VERSION ""

NS_ :

BS_:

BU_: VMM IMR BCS GSM EMS EPB SRS TEL ICM ACU VCU WCM TSCM Tester Test SCMRR SCMRL SCM SBM RCP PSDR PSDL PLGM PAS LCU IHU IBCM IAL HVSPRR HVSPRL HVSMR HVSM HVACF HUD GWM FRDCM FLDCM FCP FAPA ETC Diagnostic Messages AVAS AMP

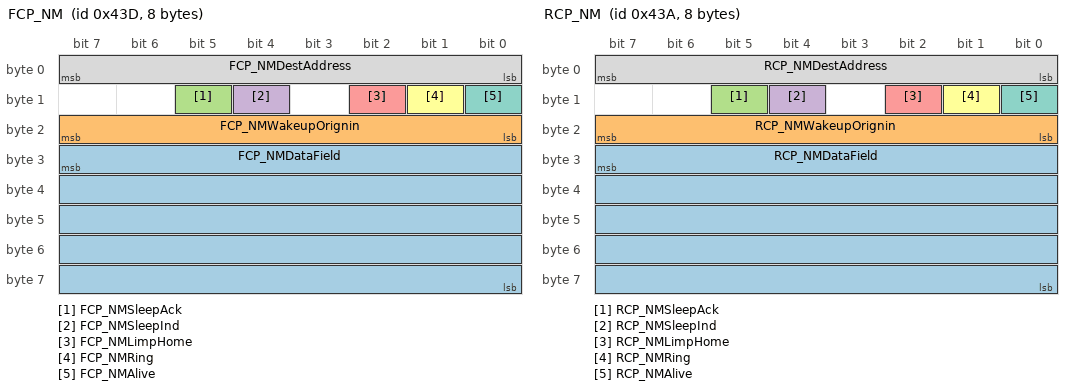
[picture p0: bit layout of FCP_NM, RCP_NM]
BO_ 1085 FCP_NM: 8 FCP
 SG_ FCP_NMDataField : 31|40@0+ (1,0) [0|0] ""  PSDR,PSDL,AMP,LCU,HUD,PLGM,FLDCM,FRDCM,SCM,TSCM,IBCM,HVACF,IAL,RCP,HVSM,IHU,SBM,WCM,ETC,GWM
 SG_ FCP_NMWakeupOrignin : 23|8@0+ (1,0) [0|255] ""  PSDR,PSDL,AMP,LCU,HUD,PLGM,FLDCM,FRDCM,SCM,TSCM,IBCM,HVACF,IAL,RCP,HVSM,IHU,SBM,WCM,ETC,GWM
 SG_ FCP_NMSleepAck : 13|1@0+ (1,0) [0|1] ""  PSDR,PSDL,AMP,LCU,HUD,PLGM,FLDCM,FRDCM,SCM,TSCM,IBCM,HVACF,IAL,RCP,HVSM,IHU,SBM,WCM,ETC,GWM
 SG_ FCP_NMSleepInd : 12|1@0+ (1,0) [0|1] ""  PSDR,PSDL,AMP,LCU,HUD,PLGM,FLDCM,FRDCM,SCM,TSCM,IBCM,HVACF,IAL,RCP,HVSM,IHU,SBM,WCM,ETC,GWM
 SG_ FCP_NMLimpHome : 10|1@0+ (1,0) [0|1] ""  PSDR,PSDL,AMP,LCU,HUD,PLGM,FLDCM,FRDCM,SCM,TSCM,IBCM,HVACF,IAL,RCP,HVSM,IHU,SBM,WCM,ETC,GWM
 SG_ FCP_NMRing : 9|1@0+ (1,0) [0|1] ""  PSDR,PSDL,AMP,LCU,HUD,PLGM,FLDCM,FRDCM,SCM,TSCM,IBCM,HVACF,IAL,RCP,HVSM,IHU,SBM,WCM,ETC,GWM
 SG_ FCP_NMAlive : 8|1@0+ (1,0) [0|1] ""  PSDR,PSDL,AMP,LCU,HUD,PLGM,FLDCM,FRDCM,SCM,TSCM,IBCM,HVACF,IAL,RCP,HVSM,IHU,SBM,WCM,ETC,GWM
 SG_ FCP_NMDestAddress : 7|8@0+ (1,0) [0|255] ""  PSDR,PSDL,AMP,LCU,HUD,PLGM,FLDCM,FRDCM,SCM,TSCM,IBCM,HVACF,IAL,RCP,HVSM,IHU,SBM,WCM,ETC,GWM

BO_ 1082 RCP_NM: 8 RCP
 SG_ RCP_NMDataField : 31|40@0+ (1,0) [0|0] ""  PSDR,PSDL,AMP,LCU,HUD,PLGM,FLDCM,FRDCM,SCM,TSCM,IBCM,HVACF,IAL,HVSM,IHU,SBM,WCM,ETC,GWM
 SG_ RCP_NMWakeupOrignin : 23|8@0+ (1,0) [0|255] ""  PSDR,PSDL,AMP,LCU,HUD,PLGM,FLDCM,FRDCM,SCM,TSCM,IBCM,HVACF,IAL,HVSM,IHU,SBM,WCM,ETC,GWM
 SG_ RCP_NMSleepAck : 13|1@0+ (1,0) [0|1] ""  PSDR,PSDL,AMP,LCU,HUD,PLGM,FLDCM,FRDCM,SCM,TSCM,IBCM,HVACF,IAL,HVSM,IHU,SBM,WCM,ETC,GWM
 SG_ RCP_NMSleepInd : 12|1@0+ (1,0) [0|1] ""  PSDR,PSDL,AMP,LCU,HUD,PLGM,FLDCM,FRDCM,SCM,TSCM,IBCM,HVACF,IAL,HVSM,IHU,SBM,WCM,ETC,GWM
 SG_ RCP_NMLimpHome : 10|1@0+ (1,0) [0|1] ""  PSDR,PSDL,AMP,LCU,HUD,PLGM,FLDCM,FRDCM,SCM,TSCM,IBCM,HVACF,IAL,HVSM,IHU,SBM,WCM,ETC,GWM
 SG_ RCP_NMRing : 9|1@0+ (1,0) [0|1] ""  PSDR,PSDL,AMP,LCU,HUD,PLGM,FLDCM,FRDCM,SCM,TSCM,IBCM,HVACF,IAL,HVSM,IHU,SBM,WCM,ETC,GWM
 SG_ RCP_NMAlive : 8|1@0+ (1,0) [0|1] ""  PSDR,PSDL,AMP,LCU,HUD,PLGM,FLDCM,FRDCM,SCM,TSCM,IBCM,HVACF,IAL,HVSM,IHU,SBM,WCM,ETC,GWM
 SG_ RCP_NMDestAddress : 7|8@0+ (1,0) [0|255] ""  PSDR,PSDL,AMP,LCU,HUD,PLGM,FLDCM,FRDCM,SCM,TSCM,IBCM,HVACF,IAL,HVSM,IHU,SBM,WCM,ETC,GWM

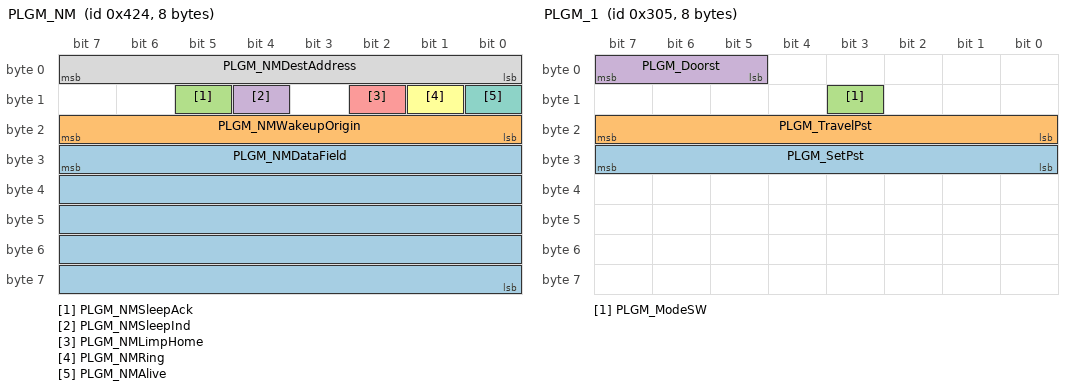
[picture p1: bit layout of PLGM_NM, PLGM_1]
BO_ 1060 PLGM_NM: 8 PLGM
 SG_ PLGM_NMDataField : 31|40@0+ (1,0) [0|0] ""  PSDR,PSDL,AMP,LCU,HUD,FLDCM,FRDCM,SCM,TSCM,IBCM,HVACF,IAL,RCP,FCP,HVSM,IHU,SBM,WCM,ETC,GWM
 SG_ PLGM_NMWakeupOrigin : 23|8@0+ (1,0) [0|255] ""  PSDR,PSDL,AMP,LCU,HUD,FLDCM,FRDCM,SCM,TSCM,IBCM,HVACF,IAL,RCP,FCP,HVSM,IHU,SBM,WCM,ETC,GWM
 SG_ PLGM_NMSleepAck : 13|1@0+ (1,0) [0|1] ""  PSDR,PSDL,AMP,LCU,HUD,FLDCM,FRDCM,SCM,TSCM,IBCM,HVACF,IAL,RCP,FCP,HVSM,IHU,SBM,WCM,ETC,GWM
 SG_ PLGM_NMSleepInd : 12|1@0+ (1,0) [0|1] ""  PSDR,PSDL,AMP,LCU,HUD,FLDCM,FRDCM,SCM,TSCM,IBCM,HVACF,IAL,RCP,FCP,HVSM,IHU,SBM,WCM,ETC,GWM
 SG_ PLGM_NMLimpHome : 10|1@0+ (1,0) [0|1] ""  PSDR,PSDL,AMP,LCU,HUD,FLDCM,FRDCM,SCM,TSCM,IBCM,HVACF,IAL,RCP,FCP,HVSM,IHU,SBM,WCM,ETC,GWM
 SG_ PLGM_NMRing : 9|1@0+ (1,0) [0|1] ""  PSDR,PSDL,AMP,LCU,HUD,FLDCM,FRDCM,SCM,TSCM,IBCM,HVACF,IAL,RCP,FCP,HVSM,IHU,SBM,WCM,ETC,GWM
 SG_ PLGM_NMAlive : 8|1@0+ (1,0) [0|1] ""  PSDR,PSDL,AMP,LCU,HUD,FLDCM,FRDCM,SCM,TSCM,IBCM,HVACF,IAL,RCP,FCP,HVSM,IHU,SBM,WCM,ETC,GWM
 SG_ PLGM_NMDestAddress : 7|8@0+ (1,0) [0|255] ""  PSDR,PSDL,AMP,LCU,HUD,FLDCM,FRDCM,SCM,TSCM,IBCM,HVACF,IAL,RCP,FCP,HVSM,IHU,SBM,WCM,ETC,GWM

BO_ 773 PLGM_1: 8 PLGM
 SG_ PLGM_SetPst : 31|8@0+ (1,0) [0|100] "%"  IHU,GWM
 SG_ PLGM_TravelPst : 23|8@0+ (1,0) [0|100] "%"  IHU,GWM
 SG_ PLGM_ModeSW : 11|1@0+ (1,0) [0|1] ""  IHU,GWM
 SG_ PLGM_Doorst : 7|3@0+ (1,0) [0|7] ""  IHU,SBM,GWM

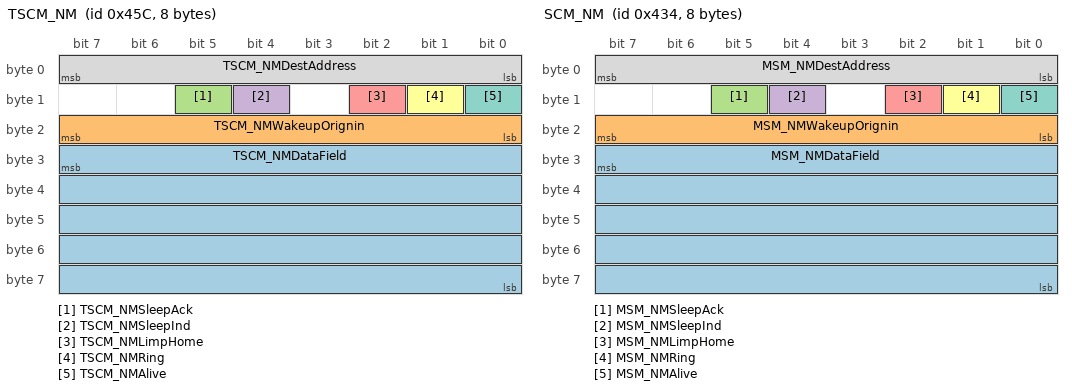
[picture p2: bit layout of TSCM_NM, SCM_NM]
BO_ 1116 TSCM_NM: 8 TSCM
 SG_ TSCM_NMDataField : 31|40@0+ (1,0) [0|0] ""  PSDR,PSDL,AMP,LCU,HUD,PLGM,FLDCM,FRDCM,SCM,IBCM,HVACF,IAL,RCP,FCP,HVSM,IHU,SBM,WCM,ETC
 SG_ TSCM_NMWakeupOrignin : 23|8@0+ (1,0) [0|255] ""  PSDR,PSDL,AMP,LCU,HUD,PLGM,FLDCM,FRDCM,SCM,IBCM,HVACF,IAL,RCP,FCP,HVSM,IHU,SBM,WCM,ETC
 SG_ TSCM_NMSleepAck : 13|1@0+ (1,0) [0|1] ""  PSDR,PSDL,AMP,LCU,HUD,PLGM,FLDCM,FRDCM,SCM,IBCM,HVACF,IAL,RCP,FCP,HVSM,IHU,SBM,WCM,ETC
 SG_ TSCM_NMSleepInd : 12|1@0+ (1,0) [0|1] ""  PSDR,PSDL,AMP,LCU,HUD,PLGM,FLDCM,FRDCM,SCM,IBCM,HVACF,IAL,RCP,FCP,HVSM,IHU,SBM,WCM,ETC
 SG_ TSCM_NMLimpHome : 10|1@0+ (1,0) [0|1] ""  PSDR,PSDL,AMP,LCU,HUD,PLGM,FLDCM,FRDCM,SCM,IBCM,HVACF,IAL,RCP,FCP,HVSM,IHU,SBM,WCM,ETC
 SG_ TSCM_NMRing : 9|1@0+ (1,0) [0|1] ""  PSDR,PSDL,AMP,LCU,HUD,PLGM,FLDCM,FRDCM,SCM,IBCM,HVACF,IAL,RCP,FCP,HVSM,IHU,SBM,WCM,ETC
 SG_ TSCM_NMAlive : 8|1@0+ (1,0) [0|1] ""  PSDR,PSDL,AMP,LCU,HUD,PLGM,FLDCM,FRDCM,SCM,IBCM,HVACF,IAL,RCP,FCP,HVSM,IHU,SBM,WCM,ETC
 SG_ TSCM_NMDestAddress : 7|8@0+ (1,0) [0|255] ""  PSDR,PSDL,AMP,LCU,HUD,PLGM,FLDCM,FRDCM,SCM,IBCM,HVACF,IAL,RCP,FCP,HVSM,IHU,SBM,WCM,ETC

BO_ 1076 SCM_NM: 8 SCM
 SG_ MSM_NMDataField : 31|40@0+ (1,0) [0|0] ""  PSDR,PSDL,AMP,LCU,HUD,PLGM,FLDCM,FRDCM,TSCM,IBCM,HVACF,IAL,RCP,FCP,HVSM,IHU,SBM,WCM,ETC,GWM
 SG_ MSM_NMWakeupOrignin : 23|8@0+ (1,0) [0|255] ""  PSDR,PSDL,AMP,LCU,HUD,PLGM,FLDCM,FRDCM,TSCM,IBCM,HVACF,IAL,RCP,FCP,HVSM,IHU,SBM,WCM,ETC,GWM
 SG_ MSM_NMSleepAck : 13|1@0+ (1,0) [0|1] ""  PSDR,PSDL,AMP,LCU,HUD,PLGM,FLDCM,FRDCM,TSCM,IBCM,HVACF,IAL,RCP,FCP,HVSM,IHU,SBM,WCM,ETC,GWM
 SG_ MSM_NMSleepInd : 12|1@0+ (1,0) [0|1] ""  PSDR,PSDL,AMP,LCU,HUD,PLGM,FLDCM,FRDCM,TSCM,IBCM,HVACF,IAL,RCP,FCP,HVSM,IHU,SBM,WCM,ETC,GWM
 SG_ MSM_NMLimpHome : 10|1@0+ (1,0) [0|1] ""  PSDR,PSDL,AMP,LCU,HUD,PLGM,FLDCM,FRDCM,TSCM,IBCM,HVACF,IAL,RCP,FCP,HVSM,IHU,SBM,WCM,ETC,GWM
 SG_ MSM_NMRing : 9|1@0+ (1,0) [0|1] ""  PSDR,PSDL,AMP,LCU,HUD,PLGM,FLDCM,FRDCM,TSCM,IBCM,HVACF,IAL,RCP,FCP,HVSM,IHU,SBM,WCM,ETC,GWM
 SG_ MSM_NMAlive : 8|1@0+ (1,0) [0|1] ""  PSDR,PSDL,AMP,LCU,HUD,PLGM,FLDCM,FRDCM,TSCM,IBCM,HVACF,IAL,RCP,FCP,HVSM,IHU,SBM,WCM,ETC,GWM
 SG_ MSM_NMDestAddress : 7|8@0+ (1,0) [0|255] ""  PSDR,PSDL,AMP,LCU,HUD,PLGM,FLDCM,FRDCM,TSCM,IBCM,HVACF,IAL,RCP,FCP,HVSM,IHU,SBM,WCM,ETC,GWM

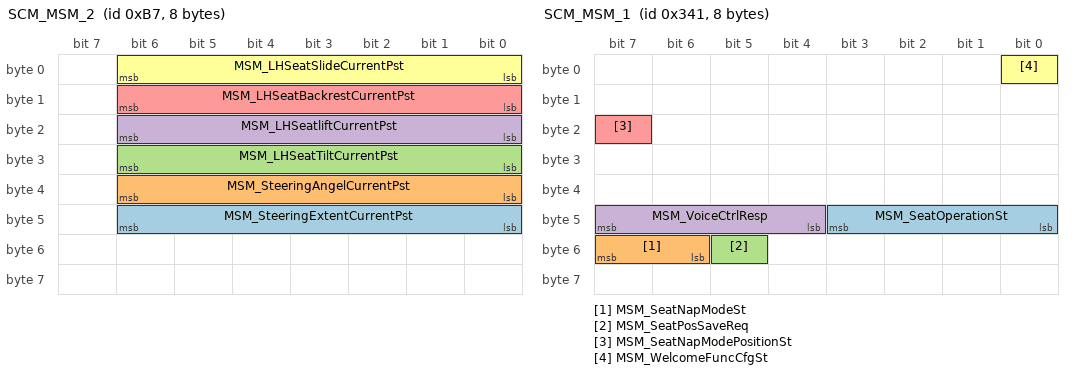
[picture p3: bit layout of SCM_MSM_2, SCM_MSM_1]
BO_ 183 SCM_MSM_2: 8 SCM
 SG_ MSM_SteeringExtentCurrentPst : 46|7@0+ (1,1) [0|0] "%"  IHU
 SG_ MSM_SteeringAngelCurrentPst : 38|7@0+ (1,1) [0|0] "%"  IHU
 SG_ MSM_LHSeatTiltCurrentPst : 30|7@0+ (1,1) [0|0] "%"  IHU
 SG_ MSM_LHSeatliftCurrentPst : 22|7@0+ (1,1) [0|0] "%"  IHU
 SG_ MSM_LHSeatBackrestCurrentPst : 14|7@0+ (1,1) [0|0] "%"  IHU
 SG_ MSM_LHSeatSlideCurrentPst : 6|7@0+ (1,1) [0|0] "%"  IHU

BO_ 833 SCM_MSM_1: 8 SCM
 SG_ MSM_SeatOperationSt : 43|4@0+ (1,0) [0|15] ""  FLDCM,FRDCM,IHU
 SG_ MSM_SeatNapModeSt : 55|2@0+ (1,0) [0|3] ""  FLDCM,IHU
 SG_ MSM_SeatPosSaveReq : 53|1@0+ (1,0) [0|1] ""  FLDCM,IHU
 SG_ MSM_VoiceCtrlResp : 47|4@0+ (1,0) [0|15] ""  IHU
 SG_ MSM_SeatNapModePositionSt : 23|1@0+ (1,0) [0|1] ""  IHU
 SG_ MSM_WelcomeFuncCfgSt : 0|1@0+ (1,0) [0|1] ""  IHU

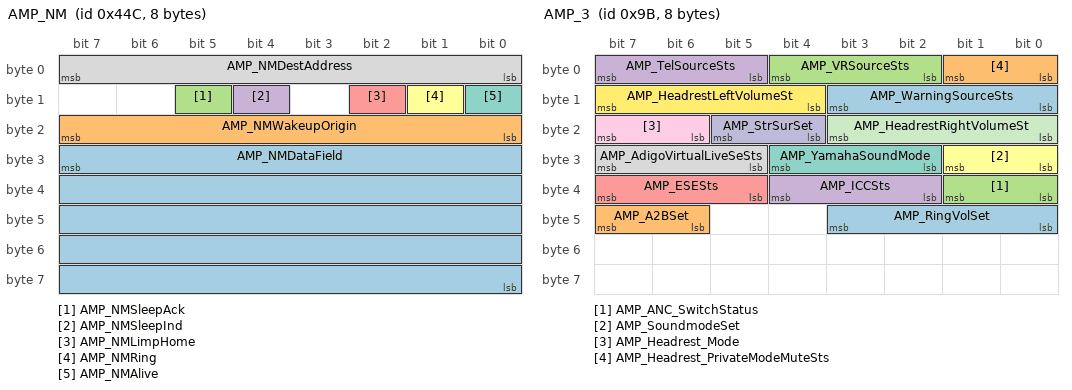
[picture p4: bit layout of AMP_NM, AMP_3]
BO_ 1100 AMP_NM: 8 AMP
 SG_ AMP_NMDataField : 31|40@0+ (1,0) [0|0] "-"  PSDR,PSDL,AMP,LCU,HUD,PLGM,FLDCM,FRDCM,SCM,TSCM,IBCM,HVACF,IAL,RCP,FCP,HVSM,IHU,SBM,WCM,ETC,GWM
 SG_ AMP_NMWakeupOrigin : 23|8@0+ (1,0) [0|255] "-"  PSDR,PSDL,AMP,LCU,HUD,PLGM,FLDCM,FRDCM,SCM,TSCM,IBCM,HVACF,IAL,RCP,FCP,HVSM,IHU,SBM,WCM,ETC,GWM
 SG_ AMP_NMSleepAck : 13|1@0+ (1,0) [0|1] "-"  PSDR,PSDL,AMP,LCU,HUD,PLGM,FLDCM,FRDCM,SCM,TSCM,IBCM,HVACF,IAL,RCP,FCP,HVSM,IHU,SBM,WCM,ETC,GWM
 SG_ AMP_NMSleepInd : 12|1@0+ (1,0) [0|1] "-"  PSDR,PSDL,AMP,LCU,HUD,PLGM,FLDCM,FRDCM,SCM,TSCM,IBCM,HVACF,IAL,RCP,FCP,HVSM,IHU,SBM,WCM,ETC,GWM
 SG_ AMP_NMLimpHome : 10|1@0+ (1,0) [0|1] "-"  PSDR,PSDL,AMP,LCU,HUD,PLGM,FLDCM,FRDCM,SCM,TSCM,IBCM,HVACF,IAL,RCP,FCP,HVSM,IHU,SBM,WCM,ETC,GWM
 SG_ AMP_NMRing : 9|1@0+ (1,0) [0|1] "-"  PSDR,PSDL,AMP,LCU,HUD,PLGM,FLDCM,FRDCM,SCM,TSCM,IBCM,HVACF,IAL,RCP,FCP,HVSM,IHU,SBM,WCM,ETC,GWM
 SG_ AMP_NMAlive : 8|1@0+ (1,0) [0|1] "-"  PSDR,PSDL,AMP,LCU,HUD,PLGM,FLDCM,FRDCM,SCM,TSCM,IBCM,HVACF,IAL,RCP,FCP,HVSM,IHU,SBM,WCM,ETC,GWM
 SG_ AMP_NMDestAddress : 7|8@0+ (1,0) [0|255] "-"  PSDR,PSDL,AMP,LCU,HUD,PLGM,FLDCM,FRDCM,SCM,TSCM,IBCM,HVACF,IAL,RCP,FCP,HVSM,IHU,SBM,WCM,ETC,GWM

BO_ 155 AMP_3: 8 AMP
 SG_ AMP_RingVolSet : 43|4@0+ (1,0) [0|15] ""  IHU
 SG_ AMP_A2BSet : 47|2@0+ (1,0) [0|3] ""  IHU
 SG_ AMP_ANC_SwitchStatus : 33|2@0+ (1,0) [0|3] ""  IHU
 SG_ AMP_ICCSts : 36|3@0+ (1,0) [0|7] ""  IHU
 SG_ AMP_ESESts : 39|3@0+ (1,0) [0|7] ""  IHU
 SG_ AMP_SoundmodeSet : 25|2@0+ (1,0) [0|3] ""  IHU
 SG_ AMP_YamahaSoundMode : 28|3@0+ (1,0) [0|7] ""  IHU
 SG_ AMP_AdigoVirtualLiveSeSts : 31|3@0+ (1,0) [0|7] ""  IHU
 SG_ AMP_Headrest_Mode : 23|2@0+ (1,0) [0|3] ""  HVSPRR,HVSPRL,IHU
 SG_ AMP_StrSurSet : 21|2@0+ (1,0) [0|1] ""  IHU
 SG_ AMP_HeadrestRightVolumeSt : 19|4@0+ (1,0) [0|15] ""  HVSPRR,IHU
 SG_ AMP_HeadrestLeftVolumeSt : 15|4@0+ (1,0) [0|15] ""  HVSPRL,IHU
 SG_ AMP_WarningSourceSts : 11|4@0+ (1,0) [0|15] ""  IHU
 SG_ AMP_Headrest_PrivateModeMuteSts : 1|2@0+ (1,0) [0|3] ""  HVSPRR,HVSPRL,IHU
 SG_ AMP_VRSourceSts : 4|3@0+ (1,0) [0|7] ""  IHU
 SG_ AMP_TelSourceSts : 7|3@0+ (1,0) [0|7] ""  IHU

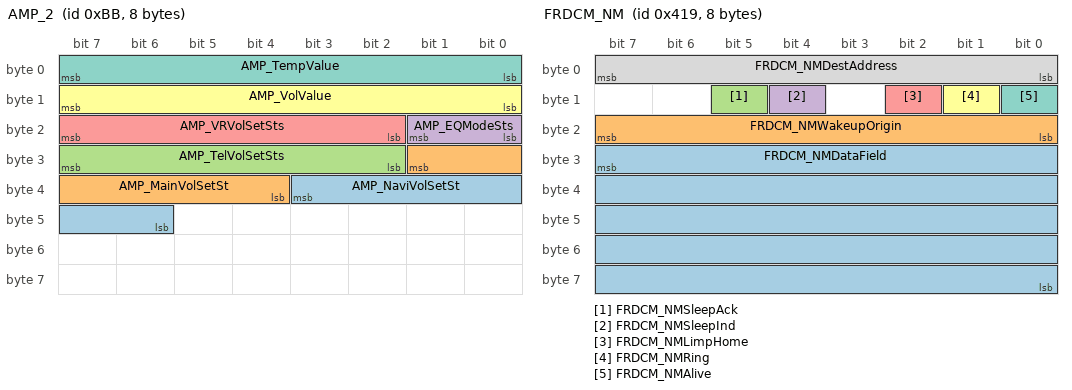
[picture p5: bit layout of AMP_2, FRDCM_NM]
BO_ 187 AMP_2: 8 AMP
 SG_ AMP_NaviVolSetSt : 35|6@0+ (1,0) [0|63] ""  IHU
 SG_ AMP_MainVolSetSt : 25|6@0+ (1,0) [0|63] ""  IHU
 SG_ AMP_TelVolSetSts : 31|6@0+ (1,0) [0|63] ""  IHU
 SG_ AMP_EQModeSts : 17|2@0+ (1,0) [0|3] ""  IHU
 SG_ AMP_VRVolSetSts : 23|6@0+ (1,0) [0|63] ""  IHU
 SG_ AMP_VolValue : 15|8@0+ (1,0) [0|255] ""  IHU
 SG_ AMP_TempValue : 7|8@0+ (1,0) [0|255] ""  IHU

BO_ 188 AMP_1: 8 AMP
 SG_ AMP_SpeakMid : 57|2@0+ (1,0) [0|3] ""  IHU
 SG_ AMP_SpeakrRR : 59|2@0+ (1,0) [0|3] ""  IHU
 SG_ AMP_SpeakrRL : 61|2@0+ (1,0) [0|3] ""  IHU
 SG_ AMP_SpeakrFR : 63|2@0+ (1,0) [0|3] ""  IHU
 SG_ AMP_SpeakFL : 49|2@0+ (1,0) [0|3] ""  IHU
 SG_ AMP_MediaSourceSt : 53|4@0+ (1,0) [0|15] ""  IHU
 SG_ AMP_ClariFiSt : 55|2@0+ (1,0) [0|3] ""  IHU
 SG_ AMP_PowerSts : 41|2@0+ (1,0) [0|3] ""  IHU
 SG_ AMP_HighFrqSet : 46|5@0+ (1,0) [0|31] ""  IHU
 SG_ AMP_TreSurSetSt : 32|2@0+ (1,0) [0|3] ""  IHU
 SG_ AMP_GetHUTInfoSts : 34|2@0+ (1,0) [0|3] ""  IHU
 SG_ AMP_TEL_ECallSts : 36|2@0+ (1,0) [0|3] ""  IHU
 SG_ AMP_MuteRearSet : 38|2@0+ (1,0) [0|3] ""  IHU
 SG_ AMP_MuteSt : 24|2@0+ (1,0) [0|3] ""  IHU
 SG_ AMP_DriveSideSt : 26|2@0+ (1,0) [0|3] ""  IHU
 SG_ AMP_MidFrqSet : 31|5@0+ (1,0) [0|31] ""  IHU
 SG_ AMP_LowFrqSet : 20|5@0+ (1,0) [0|31] ""  IHU
 SG_ AMP_VSCModeSt : 23|3@0+ (1,0) [0|7] ""  IHU
 SG_ AMP_NaviSourceSt : 10|3@0+ (1,0) [0|7] ""  IHU
 SG_ AMP_FadeSetSt : 15|5@0+ (1,0) [0|31] ""  IHU
 SG_ AMP_BeepSourceSts : 2|3@0+ (1,0) [0|7] ""  IHU
 SG_ AMP_BlcSetSt : 7|5@0+ (1,0) [0|31] ""  IHU

BO_ 1049 FRDCM_NM: 8 FRDCM
 SG_ FRDCM_NMDataField : 31|40@0+ (1,0) [0|0] ""  PSDR,PSDL,AMP,LCU,HUD,PLGM,FLDCM,SCM,TSCM,IBCM,HVACF,IAL,RCP,FCP,HVSM,IHU,SBM,WCM,ETC,GWM
 SG_ FRDCM_NMWakeupOrigin : 23|8@0+ (1,0) [0|255] ""  PSDR,PSDL,AMP,LCU,HUD,PLGM,FLDCM,SCM,TSCM,IBCM,HVACF,IAL,RCP,FCP,HVSM,IHU,SBM,WCM,ETC,GWM
 SG_ FRDCM_NMSleepAck : 13|1@0+ (1,0) [0|1] ""  PSDR,PSDL,AMP,LCU,HUD,PLGM,FLDCM,SCM,TSCM,IBCM,HVACF,IAL,RCP,FCP,HVSM,IHU,SBM,WCM,ETC,GWM
 SG_ FRDCM_NMSleepInd : 12|1@0+ (1,0) [0|1] ""  PSDR,PSDL,AMP,LCU,HUD,PLGM,FLDCM,SCM,TSCM,IBCM,HVACF,IAL,RCP,FCP,HVSM,IHU,SBM,WCM,ETC,GWM
 SG_ FRDCM_NMLimpHome : 10|1@0+ (1,0) [0|1] ""  PSDR,PSDL,AMP,LCU,HUD,PLGM,FLDCM,SCM,TSCM,IBCM,HVACF,IAL,RCP,FCP,HVSM,IHU,SBM,WCM,ETC,GWM
 SG_ FRDCM_NMRing : 9|1@0+ (1,0) [0|1] ""  PSDR,PSDL,AMP,LCU,HUD,PLGM,FLDCM,SCM,TSCM,IBCM,HVACF,IAL,RCP,FCP,HVSM,IHU,SBM,WCM,ETC,GWM
 SG_ FRDCM_NMAlive : 8|1@0+ (1,0) [0|1] ""  PSDR,PSDL,AMP,LCU,HUD,PLGM,FLDCM,SCM,TSCM,IBCM,HVACF,IAL,RCP,FCP,HVSM,IHU,SBM,WCM,ETC,GWM
 SG_ FRDCM_NMDestAddress : 7|8@0+ (1,0) [0|255] ""  PSDR,PSDL,AMP,LCU,HUD,PLGM,FLDCM,SCM,TSCM,IBCM,HVACF,IAL,RCP,FCP,HVSM,IHU,SBM,WCM,ETC,GWM

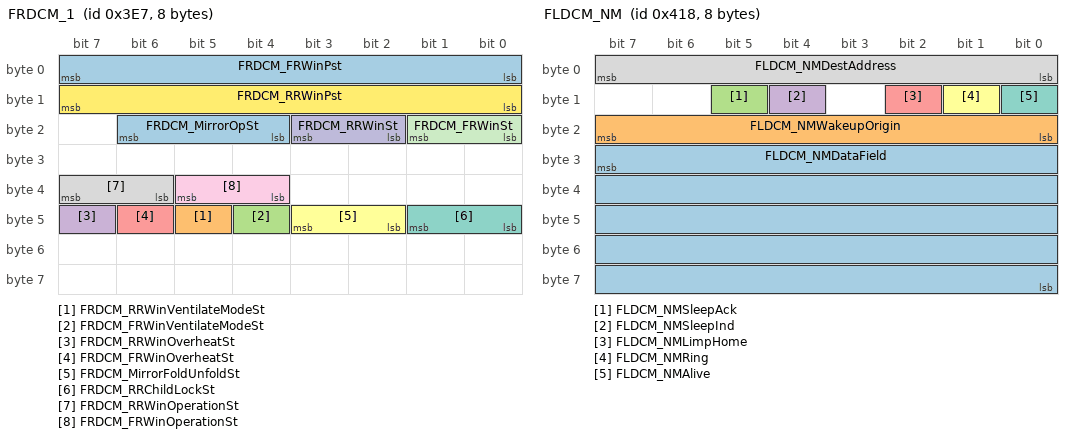
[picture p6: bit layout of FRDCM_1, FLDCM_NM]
BO_ 999 FRDCM_1: 8 FRDCM
 SG_ FRDCM_MirrorOpSt : 22|3@0+ (1,0) [0|7] ""  TEL,FLDCM,IHU,GWM
 SG_ FRDCM_RRWinVentilateModeSt : 45|1@0+ (1,0) [0|1] ""  FLDCM,IHU,GWM
 SG_ FRDCM_FRWinVentilateModeSt : 44|1@0+ (1,0) [0|1] ""  FLDCM,IHU,GWM
 SG_ FRDCM_RRWinOverheatSt : 47|1@0+ (1,0) [0|3] ""  IHU,SBM,GWM
 SG_ FRDCM_FRWinOverheatSt : 46|1@0+ (1,0) [0|3] ""  IHU,SBM,GWM
 SG_ FRDCM_MirrorFoldUnfoldSt : 43|2@0+ (1,0) [0|3] ""  IHU,FAPA,GWM
 SG_ FRDCM_RRChildLockSt : 41|2@0+ (1,0) [0|3] ""  IBCM,IHU,GWM
 SG_ FRDCM_RRWinOperationSt : 39|2@0+ (1,0) [0|3] ""  IBCM,IHU,SBM,GWM
 SG_ FRDCM_FRWinOperationSt : 37|2@0+ (1,0) [0|3] ""  IBCM,IHU,SBM,GWM
 SG_ FRDCM_RRWinSt : 19|2@0+ (1,0) [0|3] ""  FLDCM,IBCM,IAL,IHU,SBM,FAPA,GWM
 SG_ FRDCM_FRWinSt : 17|2@0+ (1,0) [0|3] ""  FLDCM,IBCM,IAL,IHU,SBM,FAPA,GWM
 SG_ FRDCM_RRWinPst : 15|8@0+ (0.5,0) [0|100] "%"  AMP,IBCM,IHU,GWM
 SG_ FRDCM_FRWinPst : 7|8@0+ (0.5,0) [0|100] "%"  AMP,IBCM,IHU,GWM

BO_ 1048 FLDCM_NM: 8 FLDCM
 SG_ FLDCM_NMDataField : 31|40@0+ (1,0) [0|0] ""  PSDR,PSDL,AMP,LCU,HUD,PLGM,FRDCM,SCM,TSCM,IBCM,HVACF,IAL,RCP,FCP,HVSM,IHU,SBM,WCM,ETC,GWM
 SG_ FLDCM_NMWakeupOrigin : 23|8@0+ (1,0) [0|255] ""  PSDR,PSDL,AMP,LCU,HUD,PLGM,FRDCM,SCM,TSCM,IBCM,HVACF,IAL,RCP,FCP,HVSM,IHU,SBM,WCM,ETC,GWM
 SG_ FLDCM_NMSleepAck : 13|1@0+ (1,0) [0|1] ""  PSDR,PSDL,AMP,LCU,HUD,PLGM,FRDCM,SCM,TSCM,IBCM,HVACF,IAL,RCP,FCP,HVSM,IHU,SBM,WCM,ETC,GWM
 SG_ FLDCM_NMSleepInd : 12|1@0+ (1,0) [0|1] ""  PSDR,PSDL,AMP,LCU,HUD,PLGM,FRDCM,SCM,TSCM,IBCM,HVACF,IAL,RCP,FCP,HVSM,IHU,SBM,WCM,ETC,GWM
 SG_ FLDCM_NMLimpHome : 10|1@0+ (1,0) [0|1] ""  PSDR,PSDL,AMP,LCU,HUD,PLGM,FRDCM,SCM,TSCM,IBCM,HVACF,IAL,RCP,FCP,HVSM,IHU,SBM,WCM,ETC,GWM
 SG_ FLDCM_NMRing : 9|1@0+ (1,0) [0|1] ""  PSDR,PSDL,AMP,LCU,HUD,PLGM,FRDCM,SCM,TSCM,IBCM,HVACF,IAL,RCP,FCP,HVSM,IHU,SBM,WCM,ETC,GWM
 SG_ FLDCM_NMAlive : 8|1@0+ (1,0) [0|1] ""  PSDR,PSDL,AMP,LCU,HUD,PLGM,FRDCM,SCM,TSCM,IBCM,HVACF,IAL,RCP,FCP,HVSM,IHU,SBM,WCM,ETC,GWM
 SG_ FLDCM_NMDestAddress : 7|8@0+ (1,0) [0|255] ""  PSDR,PSDL,AMP,LCU,HUD,PLGM,FRDCM,SCM,TSCM,IBCM,HVACF,IAL,RCP,FCP,HVSM,IHU,SBM,WCM,ETC,GWM

BO_ 997 FLDCM_1: 8 FLDCM
 SG_ FLDCM_MirrorOpSt : 34|3@0+ (1,0) [0|7] ""  TEL,FRDCM,IHU,GWM
 SG_ FLDCM_RLWinVentilateModeSt : 63|1@0+ (1,0) [0|1] ""  FRDCM,IHU,GWM
 SG_ FLDCM_FLWinVentilateModeSt : 62|1@0+ (1,0) [0|1] ""  FRDCM,IHU,GWM
 SG_ FLDCM_MirrorFoldUnfoldSt : 61|2@0+ (1,0) [0|3] ""  IHU,FAPA,GWM
 SG_ FLDCM_RLWinOperationSt : 59|2@0+ (1,0) [0|3] ""  IBCM,IHU,SBM,GWM
 SG_ FLDCM_FLWinOperationSt : 57|2@0+ (1,0) [0|3] ""  IBCM,IHU,SBM,GWM
 SG_ FLDCM_OSRMAngleAdjFuncCfgSt : 55|2@0+ (1,0) [0|3] ""  FRDCM,IHU,GWM
 SG_ FLDCM_MemorySysBuzzerReq : 53|2@0+ (1,0) [0|3] ""  IHU,GWM
 SG_ FLDCM_RLWinOverheatSt : 49|1@0+ (1,0) [0|1] ""  IHU,SBM,GWM
 SG_ FLDCM_FLWinOverheatSt : 48|1@0+ (1,0) [0|1] ""  IHU,SBM,GWM
 SG_ FLDCM_APWLEnableSt : 44|1@0+ (1,0) [0|1] ""  FRDCM,IHU,GWM
 SG_ FLDCM_PowerWinOpenWarn : 43|1@0+ (1,0) [0|1] ""  IHU,GWM
 SG_ FLDCM_MemSysOperationReq : 42|1@0+ (1,0) [0|1] ""  IHU,GWM
 SG_ FLDCM_RLChildLockSt : 41|2@0+ (1,0) [0|3] ""  IBCM,IHU,GWM
 SG_ FLDCM_RLWinSt : 19|2@0+ (1,0) [0|3] ""  IBCM,IAL,IHU,SBM,FAPA,GWM
 SG_ FLDCM_FLWinSt : 17|2@0+ (1,0) [0|3] ""  IBCM,IAL,IHU,SBM,FAPA,GWM
 SG_ FLDCM_RLWinPst : 15|8@0+ (0.5,0) [0|100] "%"  AMP,IBCM,IHU,GWM
 SG_ FLDCM_FLWinPst : 7|8@0+ (0.5,0) [0|100] "%"  AMP,IBCM,IHU,GWM

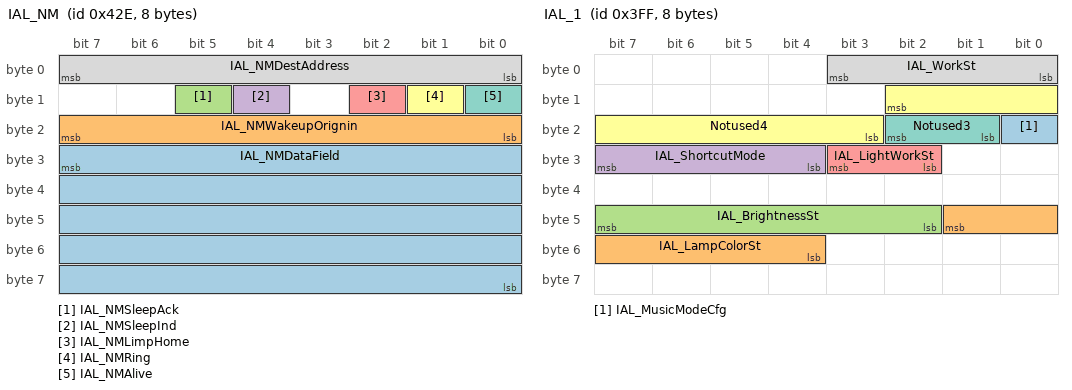
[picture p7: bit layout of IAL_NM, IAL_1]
BO_ 1070 IAL_NM: 8 IAL
 SG_ IAL_NMDataField : 31|40@0+ (1,0) [0|0] ""  PSDR,PSDL,AMP,LCU,HUD,PLGM,FLDCM,FRDCM,SCM,TSCM,IBCM,HVACF,RCP,FCP,HVSM,IHU,SBM,WCM,ETC,GWM
 SG_ IAL_NMWakeupOrignin : 23|8@0+ (1,0) [0|255] ""  PSDR,PSDL,AMP,LCU,HUD,PLGM,FLDCM,FRDCM,SCM,TSCM,IBCM,HVACF,RCP,FCP,HVSM,IHU,SBM,WCM,ETC,GWM
 SG_ IAL_NMSleepAck : 13|1@0+ (1,0) [0|1] ""  PSDR,PSDL,AMP,LCU,HUD,PLGM,FLDCM,FRDCM,SCM,TSCM,IBCM,HVACF,RCP,FCP,HVSM,IHU,SBM,WCM,ETC,GWM
 SG_ IAL_NMSleepInd : 12|1@0+ (1,0) [0|1] ""  PSDR,PSDL,AMP,LCU,HUD,PLGM,FLDCM,FRDCM,SCM,TSCM,IBCM,HVACF,RCP,FCP,HVSM,IHU,SBM,WCM,ETC,GWM
 SG_ IAL_NMLimpHome : 10|1@0+ (1,0) [0|1] ""  PSDR,PSDL,AMP,LCU,HUD,PLGM,FLDCM,FRDCM,SCM,TSCM,IBCM,HVACF,RCP,FCP,HVSM,IHU,SBM,WCM,ETC,GWM
 SG_ IAL_NMRing : 9|1@0+ (1,0) [0|1] ""  PSDR,PSDL,AMP,LCU,HUD,PLGM,FLDCM,FRDCM,SCM,TSCM,IBCM,HVACF,RCP,FCP,HVSM,IHU,SBM,WCM,ETC,GWM
 SG_ IAL_NMAlive : 8|1@0+ (1,0) [0|1] ""  PSDR,PSDL,AMP,LCU,HUD,PLGM,FLDCM,FRDCM,SCM,TSCM,IBCM,HVACF,RCP,FCP,HVSM,IHU,SBM,WCM,ETC,GWM
 SG_ IAL_NMDestAddress : 7|8@0+ (1,0) [0|255] ""  PSDR,PSDL,AMP,LCU,HUD,PLGM,FLDCM,FRDCM,SCM,TSCM,IBCM,HVACF,RCP,FCP,HVSM,IHU,SBM,WCM,ETC,GWM

BO_ 1023 IAL_1: 8 IBCM
 SG_ IAL_MusicModeCfg : 16|1@0+ (1,0) [0|1] ""  IHU
 SG_ IAL_LampColorSt : 41|6@0+ (1,0) [0|63] ""  FCP,IHU,GWM
 SG_ IAL_BrightnessSt : 47|6@0+ (1,0) [0|63] ""  IHU,GWM
 SG_ IAL_ShortcutMode : 31|4@0+ (1,0) [0|7] ""  IHU
 SG_ IAL_LightWorkSt : 27|2@0+ (1,0) [0|3] ""  IHU,GWM
 SG_ Notused4 : 10|8@0+ (1,0) [0|255] ""  IHU
 SG_ Notused3 : 18|2@0+ (1,0) [0|3] ""  IHU
 SG_ IAL_WorkSt : 3|4@0+ (1,0) [0|15] "-"  FCP,IHU

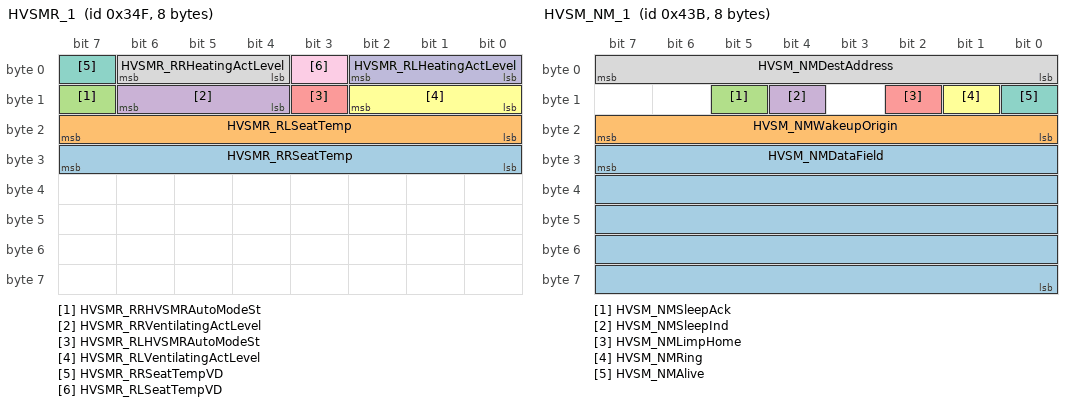
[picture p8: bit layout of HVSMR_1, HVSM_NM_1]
BO_ 847 HVSMR_1: 8 HVSMR
 SG_ HVSMR_RRSeatTemp : 31|8@0+ (1,-40) [-40|87.5] "°C"  IHU
 SG_ HVSMR_RLSeatTemp : 23|8@0+ (1,-40) [-40|87.5] "°C"  IHU
 SG_ HVSMR_RRHVSMRAutoModeSt : 15|1@0+ (1,0) [0|1] ""  IHU
 SG_ HVSMR_RRVentilatingActLevel : 14|3@0+ (1,0) [0|7] ""  IHU
 SG_ HVSMR_RLHVSMRAutoModeSt : 11|1@0+ (1,0) [0|1] ""  IHU
 SG_ HVSMR_RLVentilatingActLevel : 10|3@0+ (1,0) [0|7] ""  IHU
 SG_ HVSMR_RRSeatTempVD : 7|1@0+ (1,0) [0|1] ""  IHU
 SG_ HVSMR_RRHeatingActLevel : 6|3@0+ (1,0) [0|7] ""  IHU
 SG_ HVSMR_RLSeatTempVD : 3|1@0+ (1,0) [0|1] ""  IHU
 SG_ HVSMR_RLHeatingActLevel : 2|3@0+ (1,0) [0|7] ""  IHU

BO_ 1083 HVSM_NM_1: 8 HVSM
 SG_ HVSM_NMDataField : 31|40@0+ (1,0) [0|0] ""  PSDR,PSDL,AMP,LCU,HUD,PLGM,FLDCM,FRDCM,SCM,TSCM,IBCM,HVACF,IAL,RCP,FCP,IHU,SBM,WCM,ETC,GWM
 SG_ HVSM_NMWakeupOrigin : 23|8@0+ (1,0) [0|255] ""  PSDR,PSDL,AMP,LCU,HUD,PLGM,FLDCM,FRDCM,SCM,TSCM,IBCM,HVACF,IAL,RCP,FCP,IHU,SBM,WCM,ETC,GWM
 SG_ HVSM_NMSleepAck : 13|1@0+ (1,0) [0|1] ""  PSDR,PSDL,AMP,LCU,HUD,PLGM,FLDCM,FRDCM,SCM,TSCM,IBCM,HVACF,IAL,RCP,FCP,IHU,SBM,WCM,ETC,GWM
 SG_ HVSM_NMSleepInd : 12|1@0+ (1,0) [0|1] ""  PSDR,PSDL,AMP,LCU,HUD,PLGM,FLDCM,FRDCM,SCM,TSCM,IBCM,HVACF,IAL,RCP,FCP,IHU,SBM,WCM,ETC,GWM
 SG_ HVSM_NMLimpHome : 10|1@0+ (1,0) [0|1] ""  PSDR,PSDL,AMP,LCU,HUD,PLGM,FLDCM,FRDCM,SCM,TSCM,IBCM,HVACF,IAL,RCP,FCP,IHU,SBM,WCM,ETC,GWM
 SG_ HVSM_NMRing : 9|1@0+ (1,0) [0|1] ""  PSDR,PSDL,AMP,LCU,HUD,PLGM,FLDCM,FRDCM,SCM,TSCM,IBCM,HVACF,IAL,RCP,FCP,IHU,SBM,WCM,ETC,GWM
 SG_ HVSM_NMAlive : 8|1@0+ (1,0) [0|1] ""  PSDR,PSDL,AMP,LCU,HUD,PLGM,FLDCM,FRDCM,SCM,TSCM,IBCM,HVACF,IAL,RCP,FCP,IHU,SBM,WCM,ETC,GWM
 SG_ HVSM_NMDestAddress : 7|8@0+ (1,0) [0|255] ""  PSDR,PSDL,AMP,LCU,HUD,PLGM,FLDCM,FRDCM,SCM,TSCM,IBCM,HVACF,IAL,RCP,FCP,IHU,SBM,WCM,ETC,GWM

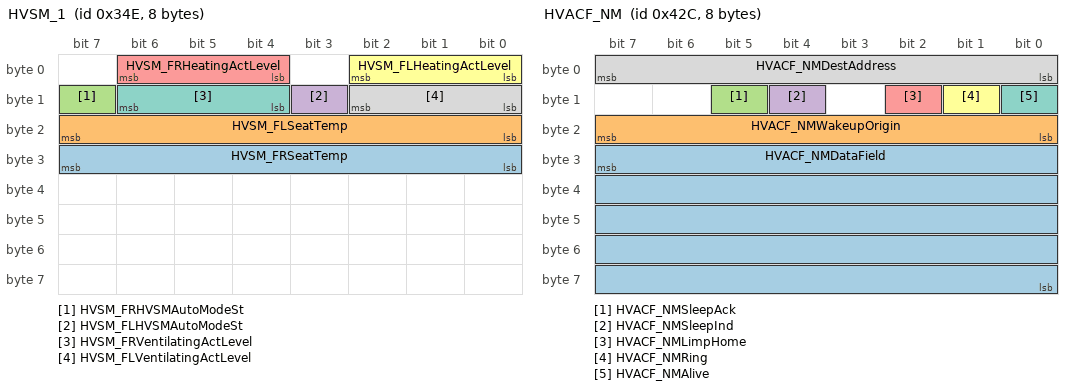
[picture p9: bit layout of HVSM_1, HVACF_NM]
BO_ 846 HVSM_1: 8 HVSM
 SG_ HVSM_FRSeatTemp : 31|8@0+ (0.5,-40) [-40|87.5] ""  IHU,ACU,FCP
 SG_ HVSM_FLSeatTemp : 23|8@0+ (0.5,-40) [-40|87.5] ""  IHU,ACU,FCP
 SG_ HVSM_FRHVSMAutoModeSt : 15|1@0+ (1,0) [0|1] ""  IHU,ACU,FCP
 SG_ HVSM_FLHVSMAutoModeSt : 11|1@0+ (1,0) [0|1] ""  FCP,IHU,ACU
 SG_ HVSM_FRHeatingActLevel : 6|3@0+ (1,0) [0|7] ""  IHU,ACU,FCP
 SG_ HVSM_FLHeatingActLevel : 2|3@0+ (1,0) [0|7] ""  ACU,IHU,FCP
 SG_ HVSM_FRVentilatingActLevel : 14|3@0+ (1,0) [0|7] ""  FCP,IHU
 SG_ HVSM_FLVentilatingActLevel : 10|3@0+ (1,0) [0|7] ""  FCP,IHU

BO_ 1068 HVACF_NM: 8 HVACF
 SG_ HVACF_NMDataField : 31|40@0+ (1,0) [0|0] ""  PSDR,PSDL,AMP,LCU,HUD,PLGM,FLDCM,FRDCM,SCM,TSCM,IBCM,IAL,RCP,FCP,HVSM,IHU,SBM,WCM,ETC,GWM
 SG_ HVACF_NMWakeupOrigin : 23|8@0+ (1,0) [0|255] ""  PSDR,PSDL,AMP,LCU,HUD,PLGM,FLDCM,FRDCM,SCM,TSCM,IBCM,IAL,RCP,FCP,HVSM,IHU,SBM,WCM,ETC,GWM
 SG_ HVACF_NMSleepAck : 13|1@0+ (1,0) [0|1] ""  PSDR,PSDL,AMP,LCU,HUD,PLGM,FLDCM,FRDCM,SCM,TSCM,IBCM,IAL,RCP,FCP,HVSM,IHU,SBM,WCM,ETC,GWM
 SG_ HVACF_NMSleepInd : 12|1@0+ (1,0) [0|1] ""  PSDR,PSDL,AMP,LCU,HUD,PLGM,FLDCM,FRDCM,SCM,TSCM,IBCM,IAL,RCP,FCP,HVSM,IHU,SBM,WCM,ETC,GWM
 SG_ HVACF_NMLimpHome : 10|1@0+ (1,0) [0|1] ""  PSDR,PSDL,AMP,LCU,HUD,PLGM,FLDCM,FRDCM,SCM,TSCM,IBCM,IAL,RCP,FCP,HVSM,IHU,SBM,WCM,ETC,GWM
 SG_ HVACF_NMRing : 9|1@0+ (1,0) [0|1] ""  PSDR,PSDL,AMP,LCU,HUD,PLGM,FLDCM,FRDCM,SCM,TSCM,IBCM,IAL,RCP,FCP,HVSM,IHU,SBM,WCM,ETC,GWM
 SG_ HVACF_NMAlive : 8|1@0+ (1,0) [0|1] ""  PSDR,PSDL,AMP,LCU,HUD,PLGM,FLDCM,FRDCM,SCM,TSCM,IBCM,IAL,RCP,FCP,HVSM,IHU,SBM,WCM,ETC,GWM
 SG_ HVACF_NMDestAddress : 7|8@0+ (1,0) [0|255] ""  PSDR,PSDL,AMP,LCU,HUD,PLGM,FLDCM,FRDCM,SCM,TSCM,IBCM,IAL,RCP,FCP,HVSM,IHU,SBM,WCM,ETC,GWM

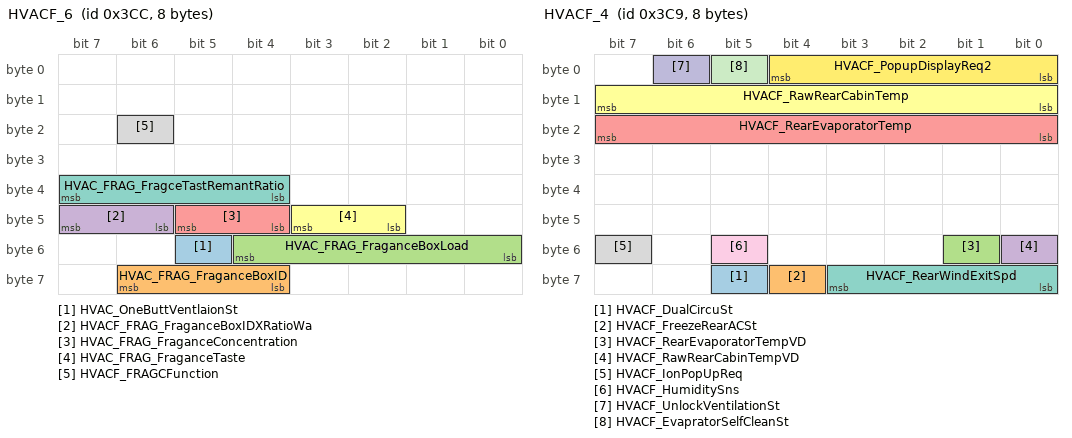
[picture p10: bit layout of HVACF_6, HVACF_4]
BO_ 972 HVACF_6: 8 HVACF
 SG_ HVAC_OneButtVentlaionSt : 53|1@0+ (1,0) [0|1] ""  IHU
 SG_ HVAC_FRAG_FraganceBoxID : 62|3@0+ (1,0) [0|7] ""  IHU
 SG_ HVAC_FRAG_FraganceBoxLoad : 52|5@0+ (1,0) [0|31] "%"  IHU
 SG_ HVACF_FRAG_FraganceBoxIDXRatioWa : 47|2@0+ (1,0) [0|3] ""  IHU
 SG_ HVAC_FRAG_FraganceConcentration : 45|2@0+ (1,0) [0|3] ""  IHU
 SG_ HVAC_FRAG_FraganceTaste : 43|2@0+ (1,0) [0|3] ""  IHU
 SG_ HVAC_FRAG_FragceTastRemantRatio : 39|4@0+ (10,0) [0|100] "%"  IHU
 SG_ HVACF_FRAGCFunction : 22|1@0+ (1,0) [0|1] "-"  IHU

BO_ 969 HVACF_4: 8 HVACF
 SG_ HVACF_DualCircuSt : 61|1@0+ (1,0) [0|1] ""  IHU
 SG_ HVACF_FreezeRearACSt : 60|1@0+ (1,0) [0|1] ""  IHU
 SG_ HVACF_RearEvaporatorTempVD : 49|1@0+ (1,0) [0|1] ""  IHU
 SG_ HVACF_RawRearCabinTempVD : 48|1@0+ (1,0) [0|1] ""  IHU
 SG_ HVACF_RearEvaporatorTemp : 23|8@0+ (0.5,-40) [-40|87.5] ""  IHU
 SG_ HVACF_RawRearCabinTemp : 15|8@0+ (0.5,-40) [-40|87.5] ""  IHU
 SG_ HVACF_RearWindExitSpd : 59|4@0+ (1,0) [0|15] ""  RCP,FCP,IHU,GWM
 SG_ HVACF_IonPopUpReq : 55|1@0+ (1,0) [0|1] ""  IHU,GWM
 SG_ HVACF_HumiditySns : 53|1@0+ (1,0) [0|1] ""  IHU,GWM
 SG_ HVACF_UnlockVentilationSt : 6|1@0+ (1,0) [0|1] ""  IHU
 SG_ HVACF_EvapratorSelfCleanSt : 5|1@0+ (1,0) [0|1] ""  IHU
 SG_ HVACF_PopupDisplayReq2 : 4|5@0+ (1,0) [0|30] ""  IHU,GWM

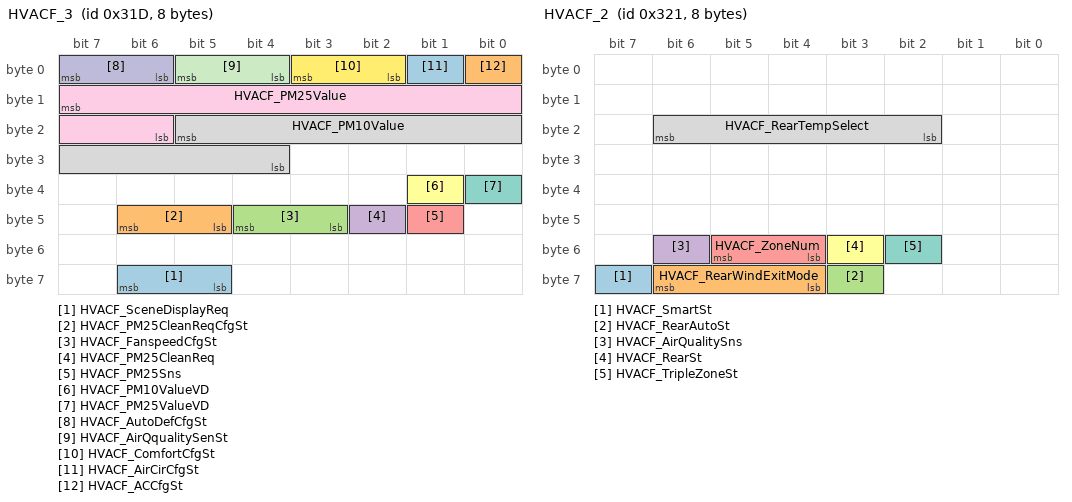
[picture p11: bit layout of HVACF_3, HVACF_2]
BO_ 797 HVACF_3: 8 HVACF
 SG_ HVACF_SceneDisplayReq : 62|2@0+ (1,0) [0|3] ""  IHU,GWM
 SG_ HVACF_PM25CleanReqCfgSt : 46|2@0+ (1,0) [0|3] ""  IHU,GWM
 SG_ HVACF_FanspeedCfgSt : 44|2@0+ (1,0) [0|3] ""  IHU,GWM
 SG_ HVACF_PM25CleanReq : 42|1@0+ (1,0) [0|1] ""  IHU,GWM
 SG_ HVACF_PM25Sns : 41|1@0+ (1,0) [0|1] ""  IHU,GWM
 SG_ HVACF_PM10ValueVD : 33|1@0+ (1,0) [0|1] ""  IHU,GWM
 SG_ HVACF_PM25ValueVD : 32|1@0+ (1,0) [0|1] ""  IHU,GWM
 SG_ HVACF_PM10Value : 21|10@0+ (1,0) [0|999] ""  IHU,GWM
 SG_ HVACF_PM25Value : 15|10@0+ (1,0) [0|999] ""  IHU,GWM
 SG_ HVACF_AutoDefCfgSt : 7|2@0+ (1,0) [0|3] ""  IHU,GWM
 SG_ HVACF_AirQqualitySenSt : 5|2@0+ (1,0) [0|3] ""  IHU,GWM
 SG_ HVACF_ComfortCfgSt : 3|2@0+ (1,0) [0|3] ""  IHU,GWM
 SG_ HVACF_AirCirCfgSt : 1|1@0+ (1,0) [0|1] ""  IHU,GWM
 SG_ HVACF_ACCfgSt : 0|1@0+ (1,0) [0|1] ""  IHU,GWM

BO_ 801 HVACF_2: 8 HVACF
 SG_ HVACF_SmartSt : 63|1@0+ (1,0) [0|1] ""  IHU
 SG_ HVACF_RearWindExitMode : 62|3@0+ (1,0) [0|7] ""  RCP,FCP,IHU,GWM
 SG_ HVACF_RearAutoSt : 59|1@0+ (1,0) [0|1] ""  RCP,FCP,IHU,GWM
 SG_ HVACF_AirQualitySns : 54|1@0+ (1,0) [0|1] ""  IHU,GWM
 SG_ HVACF_ZoneNum : 53|2@0+ (1,0) [0|3] ""  IHU,GWM
 SG_ HVACF_RearSt : 51|1@0+ (1,0) [0|1] ""  IHU,GWM
 SG_ HVACF_TripleZoneSt : 50|1@0+ (1,0) [0|1] ""  IHU,GWM
 SG_ HVACF_RearTempSelect : 22|5@0+ (0.5,18) [18|32] "°C"  IBCM,IAL,RCP,FCP,IHU,GWM

BO_ 800 HVACF_1: 8 HVACF
 SG_ HVACF_PsnTempSelect : 48|5@0+ (0.5,18) [18|32] "°C"  IBCM,IAL,IHU,SBM,GWM
 SG_ HVACF_WindExitSpd : 59|4@0+ (1,0) [0|15] ""  IHU,SBM,GWM
 SG_ HVACF_IonMode : 55|2@0+ (1,0) [0|3] ""  IHU,GWM
 SG_ HVACF_DriverTempSelect : 53|5@0+ (0.5,18) [18|32] "°C"  IBCM,IAL,IHU,SBM,GWM
 SG_ HVACF_PopUpDisplayReq1 : 47|1@0+ (1,0) [0|1] ""  IHU,SBM,GWM
 SG_ HVACF_AirCirculationSt : 46|2@0+ (1,0) [0|3] ""  IHU,SBM,GWM
 SG_ HVACF_SYNCSt : 39|1@0+ (1,0) [0|1] ""  IHU,GWM
 SG_ HVACF_TempSelectManual : 38|3@0+ (1,0) [0|7] ""  IHU,GWM
 SG_ HVACF_IonCleanFunction : 35|1@0+ (1,0) [0|1] ""  IHU,GWM
 SG_ HVACF_WindExitMode : 34|3@0+ (1,0) [0|7] ""  IHU,SBM,GWM
 SG_ HVACF_Type : 31|1@0+ (1,0) [0|1] ""  IHU,SBM,GWM
 SG_ HVACF_AutoSt : 30|1@0+ (1,0) [0|1] ""  RCP,FCP,HVSM,IHU,SBM,GWM
 SG_ HVACF_DualSyncSt : 29|1@0+ (1,0) [0|1] ""  IHU,GWM
 SG_ HVACF_TempSelectAuto : 28|5@0+ (0.5,18) [18|32] "°C"  IHU,SBM,GWM
 SG_ HVACF_CorrectedExterTemp : 15|8@0+ (0.5,-40) [-40|87.5] "°C"  HVSMR,SCMRL,SCM,IBCM,RCP,FCP,HVSM,IHU,SBM,PAS,FAPA,GWM
 SG_ HVACF_ACSt : 6|1@0+ (1,0) [0|1] ""  IHU,SBM,GWM
 SG_ HVACF_CorrectedExterTempVD : 3|1@0+ (1,0) [0|1] ""  HVSMR,SCMRL,SCM,IBCM,RCP,FCP,HVSM,IHU,SBM,PAS,GWM
 SG_ HVACF_RearDefrostSt : 2|1@0+ (1,0) [0|1] ""  IBCM,IHU,SBM,GWM

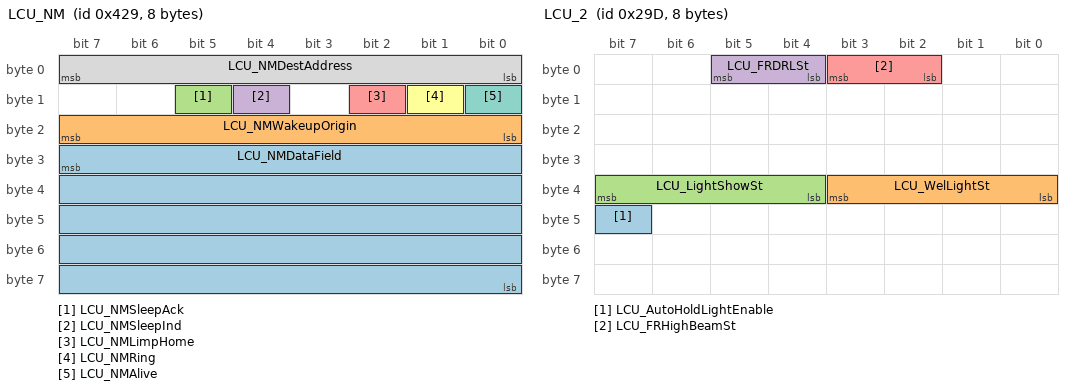
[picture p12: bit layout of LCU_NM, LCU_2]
BO_ 1065 LCU_NM: 8 LCU
 SG_ LCU_NMDataField : 31|40@0+ (1,0) [0|0] ""  PSDR,PSDL,AMP,HUD,PLGM,FLDCM,FRDCM,SCM,TSCM,IBCM,HVACF,IAL,RCP,FCP,HVSM,IHU,SBM,WCM,ETC,GWM
 SG_ LCU_NMWakeupOrigin : 23|8@0+ (1,0) [0|255] ""  PSDR,PSDL,AMP,HUD,PLGM,FLDCM,FRDCM,SCM,TSCM,IBCM,HVACF,IAL,RCP,FCP,HVSM,IHU,SBM,WCM,ETC,GWM
 SG_ LCU_NMSleepAck : 13|1@0+ (1,0) [0|1] ""  PSDR,PSDL,AMP,HUD,PLGM,FLDCM,FRDCM,SCM,TSCM,IBCM,HVACF,IAL,RCP,FCP,HVSM,IHU,SBM,WCM,ETC,GWM
 SG_ LCU_NMSleepInd : 12|1@0+ (1,0) [0|1] ""  PSDR,PSDL,AMP,HUD,PLGM,FLDCM,FRDCM,SCM,TSCM,IBCM,HVACF,IAL,RCP,FCP,HVSM,IHU,SBM,WCM,ETC,GWM
 SG_ LCU_NMLimpHome : 10|1@0+ (1,0) [0|1] ""  PSDR,PSDL,AMP,HUD,PLGM,FLDCM,FRDCM,SCM,TSCM,IBCM,HVACF,IAL,RCP,FCP,HVSM,IHU,SBM,WCM,ETC,GWM
 SG_ LCU_NMRing : 9|1@0+ (1,0) [0|1] ""  PSDR,PSDL,AMP,HUD,PLGM,FLDCM,FRDCM,SCM,TSCM,IBCM,HVACF,IAL,RCP,FCP,HVSM,IHU,SBM,WCM,ETC,GWM
 SG_ LCU_NMAlive : 8|1@0+ (1,0) [0|1] ""  PSDR,PSDL,AMP,HUD,PLGM,FLDCM,FRDCM,SCM,TSCM,IBCM,HVACF,IAL,RCP,FCP,HVSM,IHU,SBM,WCM,ETC,GWM
 SG_ LCU_NMDestAddress : 7|8@0+ (1,0) [0|255] ""  PSDR,PSDL,AMP,HUD,PLGM,FLDCM,FRDCM,SCM,TSCM,IBCM,HVACF,IAL,RCP,FCP,HVSM,IHU,SBM,WCM,ETC,GWM

BO_ 669 LCU_2: 8 GWM
 SG_ LCU_AutoHoldLightEnable : 47|1@0+ (1,0) [0|1] ""  IHU
 SG_ LCU_WelLightSt : 35|4@0+ (1,0) [0|15] ""  IHU
 SG_ LCU_LightShowSt : 39|4@0+ (1,0) [0|15] ""  IHU
 SG_ LCU_FRDRLSt : 5|2@0+ (1,0) [0|3] ""  IBCM,IHU
 SG_ LCU_FRHighBeamSt : 3|2@0+ (1,0) [0|3] ""  IBCM,IHU

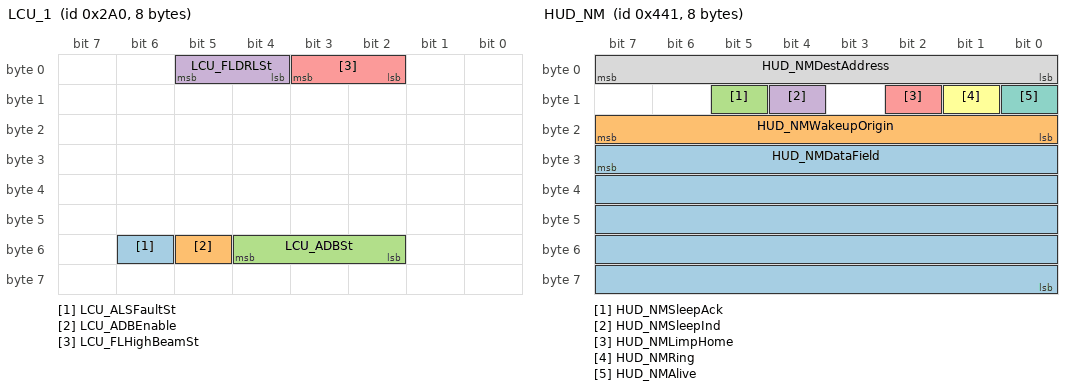
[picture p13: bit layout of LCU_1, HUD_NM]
BO_ 672 LCU_1: 8 GWM
 SG_ LCU_ALSFaultSt : 54|1@0+ (1,0) [0|1] ""  IHU
 SG_ LCU_ADBEnable : 53|1@0+ (1,0) [0|1] ""  IHU
 SG_ LCU_ADBSt : 52|3@0+ (1,0) [0|7] ""  IHU
 SG_ LCU_FLDRLSt : 5|2@0+ (1,0) [0|3] ""  IBCM,IHU
 SG_ LCU_FLHighBeamSt : 3|2@0+ (1,0) [0|3] ""  IBCM,IHU

BO_ 1089 HUD_NM: 8 HUD
 SG_ HUD_NMDataField : 31|40@0+ (1,0) [0|0] ""  PSDR,PSDL,AMP,LCU,PLGM,FLDCM,FRDCM,SCM,TSCM,IBCM,HVACF,IAL,RCP,FCP,HVSM,IHU,SBM,WCM,ETC,GWM
 SG_ HUD_NMWakeupOrigin : 23|8@0+ (1,0) [0|255] ""  PSDR,PSDL,AMP,LCU,PLGM,FLDCM,FRDCM,SCM,TSCM,IBCM,HVACF,IAL,RCP,FCP,HVSM,IHU,SBM,WCM,ETC,GWM
 SG_ HUD_NMSleepAck : 13|1@0+ (1,0) [0|1] ""  PSDR,PSDL,AMP,LCU,PLGM,FLDCM,FRDCM,SCM,TSCM,IBCM,HVACF,IAL,RCP,FCP,HVSM,IHU,SBM,WCM,ETC,GWM
 SG_ HUD_NMSleepInd : 12|1@0+ (1,0) [0|1] ""  PSDR,PSDL,AMP,LCU,PLGM,FLDCM,FRDCM,SCM,TSCM,IBCM,HVACF,IAL,RCP,FCP,HVSM,IHU,SBM,WCM,ETC,GWM
 SG_ HUD_NMLimpHome : 10|1@0+ (1,0) [0|1] ""  PSDR,PSDL,AMP,LCU,PLGM,FLDCM,FRDCM,SCM,TSCM,IBCM,HVACF,IAL,RCP,FCP,HVSM,IHU,SBM,WCM,ETC,GWM
 SG_ HUD_NMRing : 9|1@0+ (1,0) [0|1] ""  PSDR,PSDL,AMP,LCU,PLGM,FLDCM,FRDCM,SCM,TSCM,IBCM,HVACF,IAL,RCP,FCP,HVSM,IHU,SBM,WCM,ETC,GWM
 SG_ HUD_NMAlive : 8|1@0+ (1,0) [0|1] ""  PSDR,PSDL,AMP,LCU,PLGM,FLDCM,FRDCM,SCM,TSCM,IBCM,HVACF,IAL,RCP,FCP,HVSM,IHU,SBM,WCM,ETC,GWM
 SG_ HUD_NMDestAddress : 7|8@0+ (1,0) [0|255] ""  PSDR,PSDL,AMP,LCU,PLGM,FLDCM,FRDCM,SCM,TSCM,IBCM,HVACF,IAL,RCP,FCP,HVSM,IHU,SBM,WCM,ETC,GWM

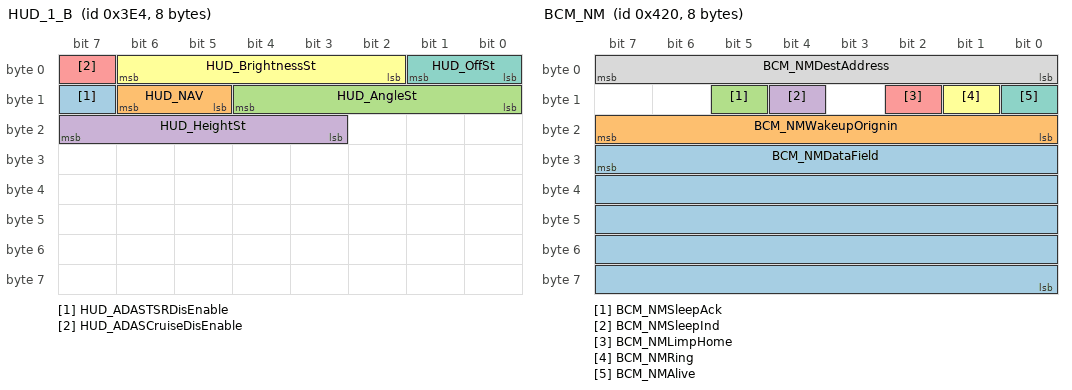
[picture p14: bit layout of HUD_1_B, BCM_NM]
BO_ 996 HUD_1_B: 8 HUD
 SG_ HUD_ADASTSRDisEnable : 15|1@0+ (1,0) [0|1] ""  IHU
 SG_ HUD_NAV : 14|2@0+ (1,0) [0|2] ""  IHU
 SG_ HUD_AngleSt : 12|5@0+ (1,0) [0|31] ""  IHU
 SG_ HUD_HeightSt : 23|5@0+ (1,0) [0|31] ""  IHU
 SG_ HUD_ADASCruiseDisEnable : 7|1@0+ (1,0) [0|1] ""  IHU
 SG_ HUD_BrightnessSt : 6|5@0+ (1,0) [0|31] ""  IHU
 SG_ HUD_OffSt : 1|2@0+ (1,0) [0|3] ""  IHU

BO_ 2015 Func_Diag_Rx: 8 Tester
 SG_ Func_Diag_Request : 7|64@0+ (1,0) [0|0] ""  HVSMR,SCMRR,SCMRL,PSDR,PSDL,AMP,LCU,HUD,PLGM,FLDCM,FRDCM,SCM,TSCM,IBCM,HVACF,IAL,RCP,FCP,HVSM,IHU,SBM,WCM,ETC,PAS,FAPA,GWM

BO_ 1056 BCM_NM: 8 IBCM
 SG_ BCM_NMDataField : 31|40@0+ (1,0) [0|0] ""  PSDR,PSDL,AMP,LCU,HUD,PLGM,FLDCM,FRDCM,SCM,TSCM,HVACF,IAL,RCP,FCP,HVSM,IHU,SBM,WCM,ETC,GWM
 SG_ BCM_NMWakeupOrignin : 23|8@0+ (1,0) [0|255] ""  PSDR,PSDL,AMP,LCU,HUD,PLGM,FLDCM,FRDCM,SCM,TSCM,HVACF,IAL,RCP,FCP,HVSM,IHU,SBM,WCM,ETC,GWM
 SG_ BCM_NMSleepAck : 13|1@0+ (1,0) [0|1] ""  PSDR,PSDL,AMP,LCU,HUD,PLGM,FLDCM,FRDCM,SCM,TSCM,HVACF,IAL,RCP,FCP,HVSM,IHU,SBM,WCM,ETC,GWM
 SG_ BCM_NMSleepInd : 12|1@0+ (1,0) [0|1] ""  PSDR,PSDL,AMP,LCU,HUD,PLGM,FLDCM,FRDCM,SCM,TSCM,HVACF,IAL,RCP,FCP,HVSM,IHU,SBM,WCM,ETC,GWM
 SG_ BCM_NMLimpHome : 10|1@0+ (1,0) [0|1] ""  PSDR,PSDL,AMP,LCU,HUD,PLGM,FLDCM,FRDCM,SCM,TSCM,HVACF,IAL,RCP,FCP,HVSM,IHU,SBM,WCM,ETC,GWM
 SG_ BCM_NMRing : 9|1@0+ (1,0) [0|1] ""  PSDR,PSDL,AMP,LCU,HUD,PLGM,FLDCM,FRDCM,SCM,TSCM,HVACF,IAL,RCP,FCP,HVSM,IHU,SBM,WCM,ETC,GWM
 SG_ BCM_NMAlive : 8|1@0+ (1,0) [0|1] ""  PSDR,PSDL,AMP,LCU,HUD,PLGM,FLDCM,FRDCM,SCM,TSCM,HVACF,IAL,RCP,FCP,HVSM,IHU,SBM,WCM,ETC,GWM
 SG_ BCM_NMDestAddress : 7|8@0+ (1,0) [0|255] ""  PSDR,PSDL,AMP,LCU,HUD,PLGM,FLDCM,FRDCM,SCM,TSCM,HVACF,IAL,RCP,FCP,HVSM,IHU,SBM,WCM,ETC,GWM

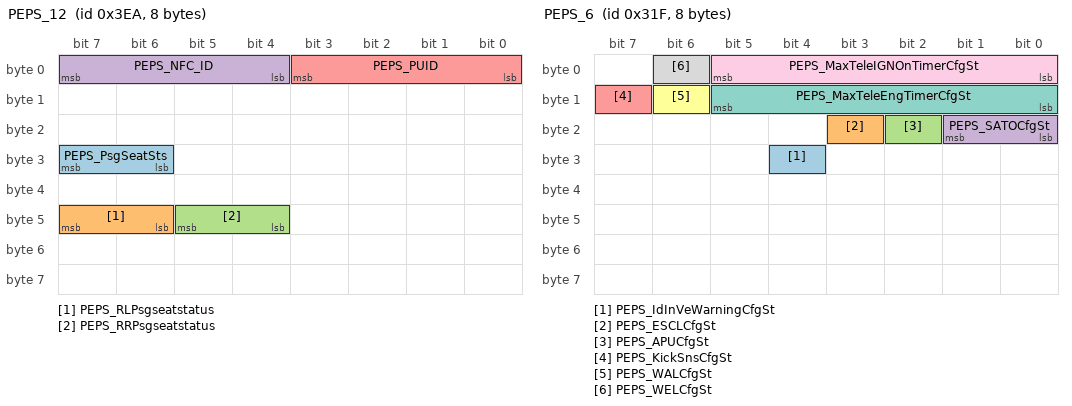
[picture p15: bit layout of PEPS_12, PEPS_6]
BO_ 1002 PEPS_12: 8 IBCM
 SG_ PEPS_PsgSeatSts : 31|2@0+ (1,0) [0|3] ""  IHU
 SG_ PEPS_RLPsgseatstatus : 47|2@0+ (1,0) [0|3] ""  IHU
 SG_ PEPS_RRPsgseatstatus : 45|2@0+ (1,0) [0|3] ""  IHU
 SG_ PEPS_NFC_ID : 7|4@0+ (1,0) [0|15] ""  IHU
 SG_ PEPS_PUID : 3|4@0+ (1,0) [0|15] ""  SCM,IAL,IHU,SBM

BO_ 799 PEPS_6: 8 IBCM
 SG_ PEPS_IdInVeWarningCfgSt : 28|1@0+ (1,0) [0|1] ""  IHU,GWM
 SG_ PEPS_ESCLCfgSt : 19|1@0+ (1,0) [0|1] ""  IHU,GWM
 SG_ PEPS_APUCfgSt : 18|1@0+ (1,0) [0|1] ""  IHU,GWM
 SG_ PEPS_SATOCfgSt : 17|2@0+ (1,0) [0|3] ""  IHU,GWM
 SG_ PEPS_KickSnsCfgSt : 15|1@0+ (1,0) [0|1] ""  IHU,GWM
 SG_ PEPS_WALCfgSt : 14|1@0+ (1,0) [0|1] ""  IHU,GWM
 SG_ PEPS_MaxTeleEngTimerCfgSt : 13|6@0+ (1,0) [0|30] "min"  IHU,GWM
 SG_ PEPS_WELCfgSt : 6|1@0+ (1,0) [0|1] ""  IHU,GWM
 SG_ PEPS_MaxTeleIGNOnTimerCfgSt : 5|6@0+ (1,0) [0|30] "min"  IHU,GWM

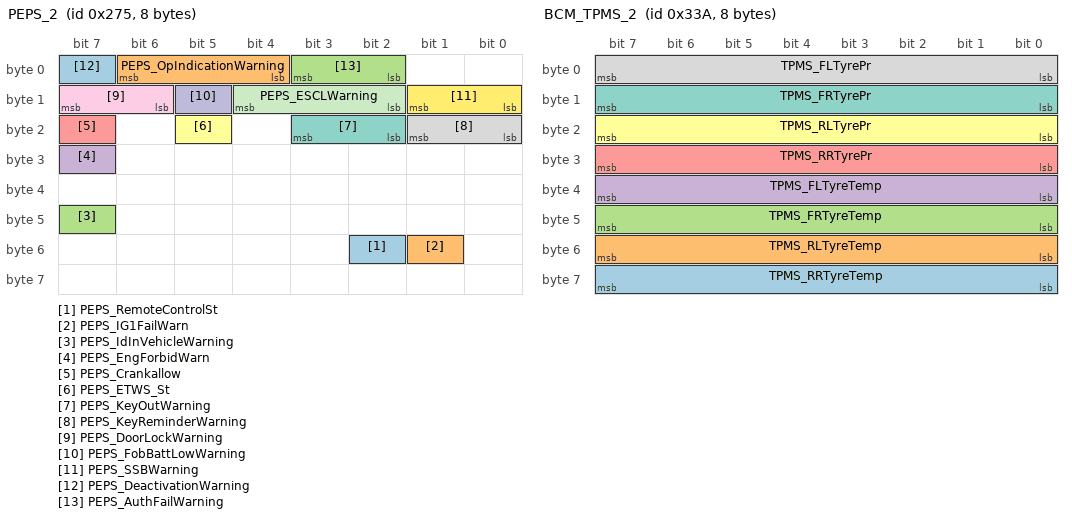
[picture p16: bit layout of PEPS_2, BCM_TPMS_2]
BO_ 629 PEPS_2: 8 IBCM
 SG_ PEPS_RemoteControlSt : 50|1@0+ (1,0) [0|1] ""  IHU
 SG_ PEPS_IG1FailWarn : 49|1@0+ (1,0) [0|1] ""  IHU,GWM
 SG_ PEPS_IdInVehicleWarning : 47|1@0+ (1,0) [0|1] ""  IHU,GWM
 SG_ PEPS_EngForbidWarn : 31|1@0+ (1,0) [0|1] ""  IHU,GWM
 SG_ PEPS_Crankallow : 23|1@0+ (1,0) [0|1] ""  IHU,SBM,GWM
 SG_ PEPS_ETWS_St : 21|1@0+ (1,0) [0|1] ""  IHU,GWM
 SG_ PEPS_KeyOutWarning : 19|2@0+ (1,0) [0|3] ""  IAL,IHU,GWM
 SG_ PEPS_KeyReminderWarning : 17|2@0+ (1,0) [0|3] ""  IAL,IHU,SBM,GWM
 SG_ PEPS_DoorLockWarning : 15|2@0+ (1,0) [0|3] ""  IHU,GWM
 SG_ PEPS_FobBattLowWarning : 13|1@0+ (1,0) [0|1] ""  IHU,SBM,GWM
 SG_ PEPS_ESCLWarning : 12|3@0+ (1,0) [0|7] ""  IHU,SBM,GWM
 SG_ PEPS_SSBWarning : 9|2@0+ (1,0) [0|3] ""  IHU,SBM,GWM
 SG_ PEPS_DeactivationWarning : 7|1@0+ (1,0) [0|1] ""  IHU,SBM,GWM
 SG_ PEPS_OpIndicationWarning : 6|3@0+ (1,0) [0|7] ""  IHU,GWM
 SG_ PEPS_AuthFailWarning : 3|2@0+ (1,0) [0|3] ""  IHU,GWM

BO_ 826 BCM_TPMS_2: 8 IBCM
 SG_ TPMS_RRTyreTemp : 63|8@0+ (1,-50) [-40|120] "℃"  IHU,SBM,GWM
 SG_ TPMS_RLTyreTemp : 55|8@0+ (1,-50) [-40|120] "℃"  IHU,SBM,GWM
 SG_ TPMS_FRTyreTemp : 47|8@0+ (1,-50) [-40|120] "℃"  IHU,SBM,GWM
 SG_ TPMS_FLTyreTemp : 39|8@0+ (1,-50) [-40|120] "℃"  IHU,SBM,GWM
 SG_ TPMS_RRTyrePr : 31|8@0+ (1.373,0) [0|254] "kpa"  IHU,SBM,GWM
 SG_ TPMS_RLTyrePr : 23|8@0+ (1.373,0) [0|254] "kpa"  IHU,SBM,GWM
 SG_ TPMS_FRTyrePr : 15|8@0+ (1.373,0) [0|254] "kpa"  IHU,SBM,GWM
 SG_ TPMS_FLTyrePr : 7|8@0+ (1.373,0) [0|254] "kpa"  IHU,SBM,GWM

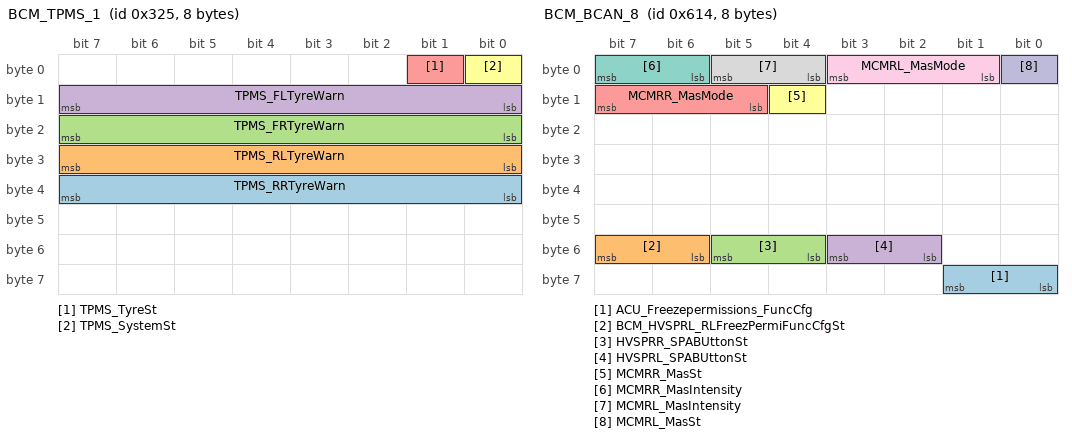
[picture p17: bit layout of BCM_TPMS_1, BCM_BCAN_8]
BO_ 805 BCM_TPMS_1: 8 IBCM
 SG_ TPMS_RRTyreWarn : 39|8@0+ (1,0) [0|255] ""  IHU,GWM
 SG_ TPMS_RLTyreWarn : 31|8@0+ (1,0) [0|255] ""  IHU,GWM
 SG_ TPMS_FRTyreWarn : 23|8@0+ (1,0) [0|255] ""  IHU,GWM
 SG_ TPMS_FLTyreWarn : 15|8@0+ (1,0) [0|255] ""  IHU,GWM
 SG_ TPMS_TyreSt : 1|1@0+ (1,0) [0|1] ""  IHU,FAPA,GWM
 SG_ TPMS_SystemSt : 0|1@0+ (1,0) [0|1] ""  IHU,GWM

BO_ 974 BCM_BCAN_9: 8 IBCM
 SG_ BCM_TCH_CupholdHeatCoolAutoMdSt : 49|2@0+ (1,0) [0|3] ""  IHU
 SG_ BCM_TCH_CupholderHeatCoolModeSt : 51|2@0+ (1,0) [0|3] ""  IHU

BO_ 149 BCM_BCAN_10: 8 IBCM
 SG_ BCM_PCS_ButtonPress : 0|1@0+ (1,0) [0|1] ""  IHU

BO_ 1556 BCM_BCAN_8: 8 IBCM
 SG_ ACU_Freezepermissions_FuncCfg : 57|2@0+ (1,0) [0|3] ""  IHU
 SG_ BCM_HVSPRL_RLFreezPermiFuncCfgSt : 55|2@0+ (1,0) [0|3] ""  IHU
 SG_ HVSPRR_SPABUttonSt : 53|2@0+ (1,0) [0|3] ""  IHU
 SG_ HVSPRL_SPABUttonSt : 51|2@0+ (1,0) [0|3] ""  IHU
 SG_ MCMRR_MasMode : 15|3@0+ (1,0) [0|7] ""  IHU
 SG_ MCMRR_MasSt : 12|1@0+ (1,0) [0|1] ""  HVSPRR,IHU
 SG_ MCMRR_MasIntensity : 7|2@0+ (1,0) [0|3] ""  IHU
 SG_ MCMRL_MasIntensity : 5|2@0+ (1,0) [0|3] ""  IHU
 SG_ MCMRL_MasMode : 3|3@0+ (1,0) [0|7] ""  IHU
 SG_ MCMRL_MasSt : 0|1@0+ (1,0) [0|1] ""  HVSPRL,IHU

BO_ 960 BCM_BCAN_5: 8 IBCM
 SG_ BCM_RefuelSwSt : 34|1@0+ (1,0) [0|1] ""  IHU
 SG_ BCM_RainstormModeReq : 57|2@0+ (1,0) [0|3] ""  IHU,GWM
 SG_ BCM_SunshadePstSt : 55|4@0+ (1,0) [0|15] ""  HUD,IHU,GWM
 SG_ BCM_SunRoofPst : 46|7@0+ (1,0) [0|100] "%"  IHU,GWM
 SG_ BCM_VCU_UnlockACChgPortReqP : 32|1@0+ (1,0) [0|1] ""  IHU,GWM
 SG_ BCM_AmbientLightSt : 31|1@0+ (1,0) [0|1] ""  IHU,GWM
 SG_ BCM_FrontWiperSwitchSt : 30|2@0+ (1,0) [0|3] ""  IHU,GWM
 SG_ BCM_LampOnWarningReq : 21|1@0+ (1,0) [0|1] ""  IHU,SBM,GWM
 SG_ BCM_SunRoofOpenWarning : 20|1@0+ (1,0) [0|1] ""  IAL,IHU,SBM,GWM
 SG_ BCM_RearWiperSwitchSt : 23|1@0+ (1,0) [0|1] ""  IHU,GWM
 SG_ BCM_SunshadePst : 14|7@0+ (1,0) [0|100] ""  IHU,GWM
 SG_ BCM_BrakeLightFaultSt : 7|1@0+ (1,0) [0|1] ""  IHU,FAPA,GWM
 SG_ BCM_BrakeLightSt : 6|1@0+ (1,0) [0|1] ""  IHU,FAPA,GWM
 SG_ BCM_ReverseLightFaultSt : 5|1@0+ (1,0) [0|1] ""  IHU,GWM
 SG_ BCM_ReverseLightSt : 4|1@0+ (1,0) [0|1] ""  IHU,FAPA,GWM
 SG_ BCM_RLSWarningLight : 2|1@0+ (1,0) [0|1] ""  IHU,GWM
 SG_ BCM_RLSWarningRain : 1|1@0+ (1,0) [0|1] ""  IHU,GWM
 SG_ BCM_HazardLampSt : 0|1@0+ (1,0) [0|1] ""  HVACF,FCP,IHU,SBM,FAPA,GWM

CM_ SG_ 1085 FCP_NMWakeupOrignin "Origin of the wake up";
CM_ SG_ 1082 RCP_NMWakeupOrignin "Origin of the wake up";
CM_ SG_ 1060 PLGM_NMWakeupOrigin "Origin of the wake up";
CM_ SG_ 773 PLGM_SetPst "Tail door set position";
CM_ SG_ 773 PLGM_TravelPst "Tail door travel position";
CM_ SG_ 773 PLGM_ModeSW "PLG mode switch staus";
CM_ SG_ 1116 TSCM_NMWakeupOrignin "Origin of the wake up";
CM_ SG_ 1116 TSCM_NMDestAddress "NM destination address";
CM_ SG_ 1076 MSM_NMWakeupOrignin "Origin of the wake up";
CM_ SG_ 1076 MSM_NMDestAddress "NM destination address";
CM_ SG_ 183 MSM_SteeringExtentCurrentPst "Steering Extent Current  Position Percentage";
CM_ SG_ 183 MSM_SteeringAngelCurrentPst "Steering Angel Current  Position Percentage";
CM_ SG_ 183 MSM_LHSeatTiltCurrentPst "Front Left Seat Tilt Current Position Percentage";
CM_ SG_ 183 MSM_LHSeatliftCurrentPst "Front Left Seat Lift Current  Position Percentage";
CM_ SG_ 183 MSM_LHSeatBackrestCurrentPst "Front Left Seat Backrest Current  Position Percentage";
CM_ SG_ 183 MSM_LHSeatSlideCurrentPst "Front Left Seat Slide Current  Position Percentage";
CM_ SG_ 833 MSM_SeatNapModeSt "Seat nap mode Status";
CM_ SG_ 833 MSM_SeatPosSaveReq "Seat nap mode position save popup Request";
CM_ SG_ 833 MSM_VoiceCtrlResp "MSM Voice control response";
CM_ SG_ 833 MSM_SeatNapModePositionSt "Seat nap mode position stored status feedback to ACU";
CM_ SG_ 833 MSM_WelcomeFuncCfgSt "MSM welcome function configuration status";
CM_ SG_ 1100 AMP_NMWakeupOrigin "Origin of the wake up";
CM_ SG_ 1100 AMP_NMDestAddress "NM destination address";
CM_ SG_ 155 AMP_A2BSet "AMP_A2BSet";
CM_ SG_ 155 AMP_ANC_SwitchStatus "ANC_SwitchStatus";
CM_ SG_ 155 AMP_ICCSts "ICC_Sts";
CM_ SG_ 155 AMP_ESESts "ESE_Sts";
CM_ SG_ 155 AMP_SoundmodeSet "SoundmodeSet";
CM_ SG_ 155 AMP_YamahaSoundMode "Yamaha Sound effect Mode";
CM_ SG_ 155 AMP_AdigoVirtualLiveSeSts "Adigo_VirtualLiveSet_Sts";
CM_ SG_ 155 AMP_Headrest_Mode "Headrest_Mode";
CM_ SG_ 155 AMP_StrSurSet "Stereo or surround set.";
CM_ SG_ 155 AMP_HeadrestRightVolumeSt "Headrest Right Private Mode Volume Status";
CM_ SG_ 155 AMP_HeadrestLeftVolumeSt "Headrest Left Private Mode Volume Status";
CM_ SG_ 155 AMP_WarningSourceSts "WarningSound source  status";
CM_ SG_ 155 AMP_Headrest_PrivateModeMuteSts "Headrest(Left or Right)_Mute_Status";
CM_ SG_ 155 AMP_VRSourceSts "VR source  status";
CM_ SG_ 155 AMP_TelSourceSts "Telephone source status";
CM_ BO_ 187 "Reserved";
CM_ SG_ 187 AMP_NaviVolSetSt "Navi volume adjustment";
CM_ SG_ 187 AMP_MainVolSetSt "Main volume step";
CM_ SG_ 187 AMP_TelVolSetSts "HFM(hand free mode), RT(ring tone) and Tbox-I/B call volume set status.";
CM_ SG_ 187 AMP_EQModeSts "EQ mode status.";
CM_ SG_ 187 AMP_VRVolSetSts "VR/TTS(text to sound) volume set state.";
CM_ SG_ 187 AMP_VolValue "Internal working voltage of AMP";
CM_ SG_ 187 AMP_TempValue "Internal temperature of AMP";
CM_ SG_ 188 AMP_SpeakMid "Mid speaker";
CM_ SG_ 188 AMP_SpeakrRR "RR speaker";
CM_ SG_ 188 AMP_SpeakrRL "RL speaker";
CM_ SG_ 188 AMP_SpeakrFR "FR speaker";
CM_ SG_ 188 AMP_SpeakFL "FL speaker";
CM_ SG_ 188 AMP_MediaSourceSt "Media/ Source State";
CM_ SG_ 188 AMP_ClariFiSt "Clari-Fi state respond.";
CM_ SG_ 188 AMP_PowerSts "AMP feedback Power 
Status to HUT";
CM_ SG_ 188 AMP_HighFrqSet "High frequency audio setting";
CM_ SG_ 188 AMP_TreSurSetSt "Stereo or surround state. (Only for A86)";
CM_ SG_ 188 AMP_GetHUTInfoSts "Get HUT Information.";
CM_ SG_ 188 AMP_TEL_ECallSts "T_box Ecall(emergency call) status.";
CM_ SG_ 188 AMP_MuteRearSet "Mute rear speakers";
CM_ SG_ 188 AMP_MuteSt "Mute/Unmute all speakers";
CM_ SG_ 188 AMP_DriveSideSt "Drive side state.";
CM_ SG_ 188 AMP_MidFrqSet "Mid frequency audio setting";
CM_ SG_ 188 AMP_LowFrqSet "Low frequency audio setting";
CM_ SG_ 188 AMP_VSCModeSt "Vehicle Speed Compensation on/off";
CM_ SG_ 188 AMP_NaviSourceSt "Navi channel state imformation";
CM_ SG_ 188 AMP_FadeSetSt "Fade setting";
CM_ SG_ 188 AMP_BeepSourceSts "Beep source status.";
CM_ SG_ 188 AMP_BlcSetSt "Balance setting";
CM_ SG_ 1049 FRDCM_NMWakeupOrigin "Origin of the wake up";
CM_ SG_ 1049 FRDCM_NMDestAddress "NM destination address";
CM_ SG_ 999 FRDCM_RRWinVentilateModeSt "Rear Right window Ventilate Mode status";
CM_ SG_ 999 FRDCM_FRWinVentilateModeSt "Front Right window Ventilate Mode status";
CM_ SG_ 999 FRDCM_RRWinOverheatSt "Rear right window overheat status";
CM_ SG_ 999 FRDCM_FRWinOverheatSt "Front right window overheat status";
CM_ SG_ 999 FRDCM_MirrorFoldUnfoldSt "Right Rearview Mirror Fold/Unfold status";
CM_ SG_ 999 FRDCM_RRChildLockSt "Rear Right ChildLockstatus";
CM_ SG_ 999 FRDCM_RRWinOperationSt "Rear right window operation status";
CM_ SG_ 999 FRDCM_FRWinOperationSt "Front right window operation status";
CM_ SG_ 999 FRDCM_RRWinSt "Rear right window status";
CM_ SG_ 999 FRDCM_FRWinSt "Front right window status";
CM_ SG_ 999 FRDCM_RRWinPst "Rear right window position";
CM_ SG_ 999 FRDCM_FRWinPst "Front right window position";
CM_ SG_ 1048 FLDCM_NMWakeupOrigin "Origin of the wake up";
CM_ SG_ 1048 FLDCM_NMDestAddress "NM destination address";
CM_ SG_ 997 FLDCM_RLWinVentilateModeSt "Rear Left window Ventilate Mode status";
CM_ SG_ 997 FLDCM_FLWinVentilateModeSt "Front Left window Ventilate Mode status";
CM_ SG_ 997 FLDCM_MirrorFoldUnfoldSt "Left Rearview Mirror Fold/Unfold status";
CM_ SG_ 997 FLDCM_RLWinOperationSt "Rear left window operation status";
CM_ SG_ 997 FLDCM_FLWinOperationSt "Front left window operation status";
CM_ SG_ 997 FLDCM_OSRMAngleAdjFuncCfgSt "Function Configuration Status，Reverse Mirror Dip";
CM_ SG_ 997 FLDCM_MemorySysBuzzerReq "Memory system buzzer request,This signal send current memory system operation buzzer request to instrument.";
CM_ SG_ 997 FLDCM_RLWinOverheatSt "Rear left window overheat status";
CM_ SG_ 997 FLDCM_FLWinOverheatSt "Front left window overheat status";
CM_ SG_ 997 FLDCM_APWLEnableSt "Anti-pinch Window Lifter operation
enable status";
CM_ SG_ 997 FLDCM_PowerWinOpenWarn "Window open warning";
CM_ SG_ 997 FLDCM_MemSysOperationReq "Memory System Operation request for AVNT active pop-up window";
CM_ SG_ 997 FLDCM_RLChildLockSt "Rear Left ChildLockstatus";
CM_ SG_ 997 FLDCM_RLWinSt "Rear left window status";
CM_ SG_ 997 FLDCM_FLWinSt "Front left window status";
CM_ SG_ 997 FLDCM_RLWinPst "Rear left window position";
CM_ SG_ 997 FLDCM_FLWinPst "Front left window position";
CM_ SG_ 1070 IAL_NMWakeupOrignin "Origin of the wake up";
CM_ SG_ 1023 IAL_LampColorSt "Current ambient lamps color status";
CM_ SG_ 1023 IAL_BrightnessSt "Current ambient lamps brightness status";
CM_ SG_ 1023 IAL_ShortcutMode "Current Setting Shortcut Mode";
CM_ SG_ 1023 IAL_LightWorkSt "Light work status";
CM_ SG_ 1023 IAL_WorkSt "Work status";
CM_ SG_ 847 HVSMR_RRSeatTemp "Rear right seat temperature";
CM_ SG_ 847 HVSMR_RLSeatTemp "Rear left seat temperature";
CM_ SG_ 847 HVSMR_RRHVSMRAutoModeSt "Rear right seat heating/ventilating auto mode status";
CM_ SG_ 847 HVSMR_RRVentilatingActLevel "Rear right seat Ventilating actual level";
CM_ SG_ 847 HVSMR_RLHVSMRAutoModeSt "Rear left seat heating/ventilating auto mode status";
CM_ SG_ 847 HVSMR_RLVentilatingActLevel "Rear left seat Ventilating actual level";
CM_ SG_ 847 HVSMR_RRSeatTempVD "Rear right seat ventilating actual level validity";
CM_ SG_ 847 HVSMR_RRHeatingActLevel "Rear right seat heating actual level";
CM_ SG_ 847 HVSMR_RLSeatTempVD "Rear left seat ventilating actual level validity";
CM_ SG_ 847 HVSMR_RLHeatingActLevel "Rear left seat heating actual level";
CM_ SG_ 1083 HVSM_NMWakeupOrigin "Origin of the wake up";
CM_ SG_ 846 HVSM_FRVentilatingActLevel "Front right seat ventilating actual level";
CM_ SG_ 846 HVSM_FLVentilatingActLevel "Front left seat ventilating actual level";
CM_ SG_ 1068 HVACF_NMDestAddress "NM destination address";
CM_ SG_ 972 HVAC_FRAG_FraganceBoxID "FraganceBox ID";
CM_ SG_ 972 HVAC_FRAG_FraganceBoxLoad "Taste2 Remanent Ratio";
CM_ SG_ 972 HVACF_FRAG_FraganceBoxIDXRatioWa "HVAC_FRAG_FraganceBoxID_X_RatioWarn";
CM_ SG_ 972 HVAC_FRAG_FraganceConcentration "Fragance Concentration";
CM_ SG_ 972 HVAC_FRAG_FraganceTaste "Fragance Taste choose";
CM_ SG_ 972 HVAC_FRAG_FragceTastRemantRatio "BOX Remanent Ratio according to HVAC_FRAG_FraganceBox ID";
CM_ SG_ 972 HVACF_FRAGCFunction "Indicates whether HVACF has FRAG
or not";
CM_ SG_ 969 HVACF_RearWindExitSpd "The rear wind exit speed";
CM_ SG_ 969 HVACF_IonPopUpReq "Ion automatic open popup Request";
CM_ SG_ 969 HVACF_HumiditySns "Indicates  whether HVACF has humidity sensor or not";
CM_ SG_ 969 HVACF_UnlockVentilationSt "Unlock Ventilation function  configuration status";
CM_ SG_ 969 HVACF_EvapratorSelfCleanSt "Evaprator Self Clean function configuration status";
CM_ SG_ 969 HVACF_PopupDisplayReq2 "The Air Condition Information Pop-Up Display Request（toast）";
CM_ SG_ 797 HVACF_SceneDisplayReq "Scene Button Display Request";
CM_ SG_ 797 HVACF_PM25CleanReqCfgSt "PM25CleanReq Set configuration status";
CM_ SG_ 797 HVACF_FanspeedCfgSt "HVAC Fan speed of AUTO  mode configuration status";
CM_ SG_ 797 HVACF_PM25CleanReq "PM2.5 Clean Req from the HVACF";
CM_ SG_ 797 HVACF_PM25Sns "Indicates  whether HVACF has PM2.5 sensor or not";
CM_ SG_ 797 HVACF_PM10ValueVD "indicate signal “HVACF_PM10 Value”Validity";
CM_ SG_ 797 HVACF_PM25ValueVD "indicate signal “HVACF_PM2.5 Value”Validity";
CM_ SG_ 797 HVACF_PM10Value "PM10";
CM_ SG_ 797 HVACF_PM25Value "PM2.5";
CM_ SG_ 797 HVACF_AutoDefCfgSt "Configurates auto deforst status";
CM_ SG_ 797 HVACF_AirQqualitySenSt "Air quality sensitivity status";
CM_ SG_ 797 HVACF_ComfortCfgSt "Comfort curve configuration status";
CM_ SG_ 797 HVACF_AirCirCfgSt "Air circulation control mode when HVACF  in auto mode  configuration status";
CM_ SG_ 797 HVACF_ACCfgSt "Compressor control mode when HVACF in auto mode configuration status";
CM_ SG_ 801 HVACF_SmartSt "Dual Circu";
CM_ SG_ 801 HVACF_RearWindExitMode "The rear wind exit mode";
CM_ SG_ 801 HVACF_RearAutoSt "The rear HVAC auto state display";
CM_ SG_ 801 HVACF_AirQualitySns "Indicates  whether HVACF has AQS(Air Quality Sensor) or not";
CM_ SG_ 801 HVACF_ZoneNum "Indicates the HVACF zone numbers";
CM_ SG_ 801 HVACF_RearSt "Indicates the rear status display";
CM_ SG_ 801 HVACF_TripleZoneSt "The HVACF triple zone control state";
CM_ SG_ 800 HVACF_PsnTempSelect "The selected temperature  of passenger side";
CM_ SG_ 800 HVACF_WindExitSpd "The wind exit speed";
CM_ SG_ 800 HVACF_IonMode "Ion mode";
CM_ SG_ 800 HVACF_DriverTempSelect "The selected temperature  of Driver side";
CM_ SG_ 800 HVACF_PopUpDisplayReq1 "The Air Condition Information Pop-Up Display Request";
CM_ SG_ 800 HVACF_AirCirculationSt "Airconditionor air circulation state";
CM_ SG_ 800 HVACF_SYNCSt "The HVACF Sync control state";
CM_ SG_ 800 HVACF_TempSelectManual "The  temperature selected on manual HVAC";
CM_ SG_ 800 HVACF_IonCleanFunction "Indicates whether HVACF has Ionclean
or not";
CM_ SG_ 800 HVACF_WindExitMode "The wind exit mode";
CM_ SG_ 800 HVACF_Type "The HVACF type";
CM_ SG_ 800 HVACF_AutoSt "The HVACF auto state display";
CM_ SG_ 800 HVACF_DualSyncSt "The HVACF Dual/SYNC control display";
CM_ SG_ 800 HVACF_TempSelectAuto "The  temperature selected on auto HVACF";
CM_ SG_ 800 HVACF_CorrectedExterTemp "External temperature";
CM_ SG_ 800 HVACF_ACSt "The HVACF A/C state display";
CM_ SG_ 800 HVACF_CorrectedExterTempVD "External temperature validity";
CM_ SG_ 800 HVACF_RearDefrostSt "Rear window and  mirror heater activation status";
CM_ SG_ 1065 LCU_NMDestAddress "NM destination address";
CM_ SG_ 669 LCU_LightShowSt "Light show status";
CM_ SG_ 669 LCU_FRDRLSt "Right daytime running lamp status";
CM_ SG_ 669 LCU_FRHighBeamSt "Rignt high beam status";
CM_ SG_ 672 LCU_ALSFaultSt "ALS fault status";
CM_ SG_ 672 LCU_ADBEnable "ADB Enable Status";
CM_ SG_ 672 LCU_ADBSt "ADB status";
CM_ SG_ 672 LCU_FLDRLSt "Left daytime running lamp status";
CM_ SG_ 672 LCU_FLHighBeamSt "Left high beam status";
CM_ SG_ 1089 HUD_NMDestAddress "NM destination address";
CM_ SG_ 996 HUD_ADASTSRDisEnable "Shielding state feedback of  TSR in HUD display";
CM_ SG_ 996 HUD_NAV "Shielding state feedback of navigation in HUD display";
CM_ SG_ 996 HUD_AngleSt "HUD angle signal feedback";
CM_ SG_ 996 HUD_HeightSt "HUD height signal feedback";
CM_ SG_ 996 HUD_ADASCruiseDisEnable "Shielding state feedback of  Cruise in HUD display";
CM_ SG_ 996 HUD_BrightnessSt "HUD brightness signal feedback";
CM_ SG_ 996 HUD_OffSt "HUD switch signal feedback";
CM_ SG_ 2015 Func_Diag_Request "Diagnostic functional request";
CM_ SG_ 1056 BCM_NMWakeupOrignin "Origin of the wake up";
CM_ SG_ 1056 BCM_NMDestAddress "NM Destination Address";
CM_ SG_ 1002 PEPS_NFC_ID "NFC identification";
CM_ SG_ 1002 PEPS_PUID "Current Account ID";
CM_ SG_ 799 PEPS_IdInVeWarningCfgSt "PEPS ID in Vehicle warning satatues";
CM_ SG_ 799 PEPS_ESCLCfgSt "ESCL configuration status";
CM_ SG_ 799 PEPS_APUCfgSt "Indicate PEPS APU configuration status";
CM_ SG_ 799 PEPS_SATOCfgSt "Indicate PEPS SATO configuration status";
CM_ SG_ 799 PEPS_KickSnsCfgSt "Kick sensor (sensor to open trunk) configuration status";
CM_ SG_ 799 PEPS_WALCfgSt "Indicate PEPS WAL configuration status";
CM_ SG_ 799 PEPS_MaxTeleEngTimerCfgSt "Max telematics engine running time  configuration status";
CM_ SG_ 799 PEPS_WELCfgSt "Indicate PEPS WEL(Welcome light) configuration status";
CM_ SG_ 799 PEPS_MaxTeleIGNOnTimerCfgSt "Max telematics IGN ON time configuration status";
CM_ BO_ 629 "Only for AVNT";
CM_ SG_ 629 PEPS_IG1FailWarn "IG1 fail warning";
CM_ SG_ 629 PEPS_IdInVehicleWarning "When closed last door,if found id in vehicle ,polling condition not OK";
CM_ SG_ 629 PEPS_EngForbidWarn "Engine start forbid warning";
CM_ SG_ 629 PEPS_Crankallow "Allow cranking at mode 2";
CM_ SG_ 629 PEPS_ETWS_St "Engine theft warning status";
CM_ SG_ 629 PEPS_KeyOutWarning "Key out warning";
CM_ SG_ 629 PEPS_KeyReminderWarning "Key reminder warning";
CM_ SG_ 629 PEPS_DoorLockWarning "Door lock warning";
CM_ SG_ 629 PEPS_FobBattLowWarning "FOB battery low warning";
CM_ SG_ 629 PEPS_ESCLWarning "ESCL warning";
CM_ SG_ 629 PEPS_SSBWarning "Start and stop button warning";
CM_ SG_ 629 PEPS_DeactivationWarning "Deactivation warning";
CM_ SG_ 629 PEPS_OpIndicationWarning "Operation indication warning";
CM_ SG_ 629 PEPS_AuthFailWarning "Authentication fail warnings";
CM_ SG_ 826 TPMS_RRTyreTemp "Rear right tyre temperature";
CM_ SG_ 826 TPMS_RLTyreTemp "Rear left tyre temperature";
CM_ SG_ 826 TPMS_FRTyreTemp "Front right tyre temperature";
CM_ SG_ 826 TPMS_FLTyreTemp "Front left tyre temperature";
CM_ SG_ 826 TPMS_RRTyrePr "Rear right tyre pressure";
CM_ SG_ 826 TPMS_RLTyrePr "Rear left tyre pressure";
CM_ SG_ 826 TPMS_FRTyrePr "Front right tyre pressure";
CM_ SG_ 826 TPMS_FLTyrePr "Front left tyre pressure";
CM_ SG_ 805 TPMS_RRTyreWarn "Rear right tyre warning";
CM_ SG_ 805 TPMS_RLTyreWarn "Rear left tyre warning";
CM_ SG_ 805 TPMS_FRTyreWarn "Front right tyre warning";
CM_ SG_ 805 TPMS_FLTyreWarn "Front left tyre warning";
CM_ SG_ 805 TPMS_TyreSt "Tyre status";
CM_ SG_ 805 TPMS_SystemSt "TPMS system status";
CM_ SG_ 974 BCM_TCH_CupholdHeatCoolAutoMdSt "Cupholder heating/cooling AutoMode mode status";
CM_ SG_ 974 BCM_TCH_CupholderHeatCoolModeSt "Cupholder heating/cooling mode status";
CM_ SG_ 149 BCM_PCS_ButtonPress "SVM Button";
CM_ SG_ 1556 MCMRR_MasMode "Rear Right MCM(Massage Control Module)massage mode";
CM_ SG_ 1556 MCMRR_MasSt "Rear Right  MCM(Massage Control Module)massage status";
CM_ SG_ 1556 MCMRR_MasIntensity "Rear Right MCM(Massage Control Module)massage intensity";
CM_ SG_ 1556 MCMRL_MasIntensity "Rear left MCM(Massage Control Module)massage intensity";
CM_ SG_ 1556 MCMRL_MasMode "Rear left MCM(Massage Control Module)massage mode";
CM_ SG_ 1556 MCMRL_MasSt "Rear left MCM(Massage Control Module)massage status";
CM_ SG_ 960 BCM_RainstormModeReq "Rain storm Mode request";
CM_ SG_ 960 BCM_SunshadePstSt "The Sunshade Position status.";
CM_ SG_ 960 BCM_SunRoofPst "The Sun Roof Position.";
CM_ SG_ 960 BCM_VCU_UnlockACChgPortReqP "BCM request VCU to unlock AC charge lock port(Periodic Message)";
CM_ SG_ 960 BCM_AmbientLightSt "Ambient Light status";
CM_ SG_ 960 BCM_FrontWiperSwitchSt "Front wiper switch status";
CM_ SG_ 960 BCM_LampOnWarningReq "Lamp left on warning request";
CM_ SG_ 960 BCM_SunRoofOpenWarning "SunRoof open warning";
CM_ SG_ 960 BCM_RearWiperSwitchSt "Rear wiper switch status";
CM_ SG_ 960 BCM_SunshadePst "The Sun Shade Position";
CM_ SG_ 960 BCM_BrakeLightFaultSt "Brake light fault status";
CM_ SG_ 960 BCM_BrakeLightSt "Brake light status";
CM_ SG_ 960 BCM_ReverseLightFaultSt "Reverse light fault status";
CM_ SG_ 960 BCM_ReverseLightSt "Reverse light status";
CM_ SG_ 960 BCM_RLSWarningLight "RLS auto light warning";
CM_ SG_ 960 BCM_RLSWarningRain "RLS auto wiper warning";
CM_ SG_ 960 BCM_HazardLampSt "Hazard lamp  status";
BA_DEF_ SG_  "Remark" STRING ;
BA_DEF_ SG_  "EventCommandSignal" ENUM  "No","Yes";
BA_DEF_ SG_  "GatewayedSignals" ENUM  "No","Yes";
BA_DEF_ SG_  "GenSigTimeoutValue" INT 0 0;
BA_DEF_ SG_  "GenSigStartValue" INT 0 0;
BA_DEF_ SG_  "GenSigInvalidValue" INT 0 0;
BA_DEF_ SG_  "GenSigInactiveValue" INT 0 0;
BA_DEF_ BO_  "GenMsgCycleTimeFast" INT 0 0;
BA_DEF_ BO_  "GenMsgCycleTime" INT 0 0;
BA_DEF_ SG_  "GenSigSendType" ENUM  "Trigger","Passive";
BA_DEF_ BO_  "GenMsgSendType" ENUM  "Periodic","Event","IfActive","POE","PA";
BA_DEF_ SG_  "SystemSignalLongSymbol" STRING ;
BA_DEF_DEF_  "Remark" "*";
BA_DEF_DEF_  "EventCommandSignal" "No";
BA_DEF_DEF_  "GatewayedSignals" "No";
BA_DEF_DEF_  "GenSigTimeoutValue" 0;
BA_DEF_DEF_  "GenSigStartValue" 0;
BA_DEF_DEF_  "GenSigInvalidValue" 0;
BA_DEF_DEF_  "GenSigInactiveValue" 0;
BA_DEF_DEF_  "GenMsgCycleTimeFast" 0;
BA_DEF_DEF_  "GenMsgCycleTime" 0;
BA_DEF_DEF_  "GenSigSendType" "Trigger";
BA_DEF_DEF_  "GenMsgSendType" "Periodic";
BA_DEF_DEF_  "SystemSignalLongSymbol" "";
BA_ "GenMsgCycleTime" BO_ 773 100;
BA_ "GenMsgSendType" BO_ 183 1;
BA_ "GenMsgCycleTime" BO_ 833 100;
BA_ "GenMsgSendType" BO_ 155 1;
BA_ "GenMsgSendType" BO_ 187 1;
BA_ "GenMsgSendType" BO_ 188 1;
BA_ "GenMsgCycleTime" BO_ 999 100;
BA_ "GenMsgCycleTime" BO_ 997 100;
BA_ "GenMsgCycleTime" BO_ 1023 500;
BA_ "GenMsgCycleTime" BO_ 847 200;
BA_ "GenMsgCycleTime" BO_ 846 200;
BA_ "GenMsgCycleTime" BO_ 972 100;
BA_ "GenMsgCycleTime" BO_ 969 100;
BA_ "GenMsgCycleTime" BO_ 797 500;
BA_ "GenMsgCycleTime" BO_ 801 100;
BA_ "GenMsgCycleTime" BO_ 800 100;
BA_ "GenMsgCycleTime" BO_ 669 100;
BA_ "GenMsgCycleTime" BO_ 672 100;
BA_ "GenMsgCycleTime" BO_ 996 100;
BA_ "GenMsgCycleTime" BO_ 1002 100;
BA_ "GenMsgCycleTime" BO_ 799 500;
BA_ "GenMsgCycleTime" BO_ 629 100;
BA_ "GenMsgCycleTime" BO_ 826 500;
BA_ "GenMsgCycleTime" BO_ 805 100;
BA_ "GenMsgCycleTime" BO_ 974 100;
BA_ "GenMsgSendType" BO_ 149 1;
BA_ "GenMsgCycleTime" BO_ 1556 100;
BA_ "GenMsgCycleTime" BO_ 960 100;
BA_ "Remark" SG_ 1085 FCP_NMDataField "";
BA_ "GenSigSendType" SG_ 1085 FCP_NMDataField 1;
BA_ "Remark" SG_ 1085 FCP_NMWakeupOrignin "";
BA_ "GenSigSendType" SG_ 1085 FCP_NMWakeupOrignin 1;
BA_ "Remark" SG_ 1085 FCP_NMSleepAck "";
BA_ "GenSigSendType" SG_ 1085 FCP_NMSleepAck 1;
BA_ "Remark" SG_ 1085 FCP_NMSleepInd "";
BA_ "GenSigSendType" SG_ 1085 FCP_NMSleepInd 1;
BA_ "Remark" SG_ 1085 FCP_NMLimpHome "";
BA_ "GenSigSendType" SG_ 1085 FCP_NMLimpHome 1;
BA_ "Remark" SG_ 1085 FCP_NMRing "";
BA_ "GenSigSendType" SG_ 1085 FCP_NMRing 1;
BA_ "Remark" SG_ 1085 FCP_NMAlive "";
BA_ "GenSigSendType" SG_ 1085 FCP_NMAlive 1;
BA_ "Remark" SG_ 1085 FCP_NMDestAddress "";
BA_ "GenSigSendType" SG_ 1085 FCP_NMDestAddress 1;
BA_ "Remark" SG_ 1082 RCP_NMDataField "";
BA_ "GenSigSendType" SG_ 1082 RCP_NMDataField 1;
BA_ "Remark" SG_ 1082 RCP_NMWakeupOrignin "";
BA_ "GenSigSendType" SG_ 1082 RCP_NMWakeupOrignin 1;
BA_ "Remark" SG_ 1082 RCP_NMSleepAck "";
BA_ "GenSigSendType" SG_ 1082 RCP_NMSleepAck 1;
BA_ "Remark" SG_ 1082 RCP_NMSleepInd "";
BA_ "GenSigSendType" SG_ 1082 RCP_NMSleepInd 1;
BA_ "Remark" SG_ 1082 RCP_NMLimpHome "";
BA_ "GenSigSendType" SG_ 1082 RCP_NMLimpHome 1;
BA_ "Remark" SG_ 1082 RCP_NMRing "";
BA_ "GenSigSendType" SG_ 1082 RCP_NMRing 1;
BA_ "Remark" SG_ 1082 RCP_NMAlive "";
BA_ "GenSigSendType" SG_ 1082 RCP_NMAlive 1;
BA_ "Remark" SG_ 1082 RCP_NMDestAddress "";
BA_ "GenSigSendType" SG_ 1082 RCP_NMDestAddress 1;
BA_ "Remark" SG_ 1060 PLGM_NMDataField "";
BA_ "GenSigSendType" SG_ 1060 PLGM_NMDataField 1;
BA_ "Remark" SG_ 1060 PLGM_NMWakeupOrigin "";
BA_ "GenSigSendType" SG_ 1060 PLGM_NMWakeupOrigin 1;
BA_ "Remark" SG_ 1060 PLGM_NMSleepAck "";
BA_ "GenSigSendType" SG_ 1060 PLGM_NMSleepAck 1;
BA_ "Remark" SG_ 1060 PLGM_NMSleepInd "";
BA_ "GenSigSendType" SG_ 1060 PLGM_NMSleepInd 1;
BA_ "Remark" SG_ 1060 PLGM_NMLimpHome "";
BA_ "GenSigSendType" SG_ 1060 PLGM_NMLimpHome 1;
BA_ "Remark" SG_ 1060 PLGM_NMRing "";
BA_ "GenSigSendType" SG_ 1060 PLGM_NMRing 1;
BA_ "Remark" SG_ 1060 PLGM_NMAlive "";
BA_ "GenSigSendType" SG_ 1060 PLGM_NMAlive 1;
BA_ "Remark" SG_ 1060 PLGM_NMDestAddress "";
BA_ "GenSigSendType" SG_ 1060 PLGM_NMDestAddress 1;
BA_ "Remark" SG_ 773 PLGM_SetPst "";
BA_ "GenSigSendType" SG_ 773 PLGM_SetPst 1;
BA_ "Remark" SG_ 773 PLGM_TravelPst "";
BA_ "GenSigSendType" SG_ 773 PLGM_TravelPst 1;
BA_ "Remark" SG_ 773 PLGM_ModeSW "";
BA_ "GenSigSendType" SG_ 773 PLGM_ModeSW 1;
BA_ "Remark" SG_ 773 PLGM_Doorst "";
BA_ "GenSigSendType" SG_ 773 PLGM_Doorst 1;
BA_ "Remark" SG_ 1116 TSCM_NMDataField "";
BA_ "GenSigSendType" SG_ 1116 TSCM_NMDataField 1;
BA_ "Remark" SG_ 1116 TSCM_NMWakeupOrignin "";
BA_ "GenSigSendType" SG_ 1116 TSCM_NMWakeupOrignin 1;
BA_ "Remark" SG_ 1116 TSCM_NMSleepAck "";
BA_ "GenSigSendType" SG_ 1116 TSCM_NMSleepAck 1;
BA_ "Remark" SG_ 1116 TSCM_NMSleepInd "";
BA_ "GenSigSendType" SG_ 1116 TSCM_NMSleepInd 1;
BA_ "Remark" SG_ 1116 TSCM_NMLimpHome "";
BA_ "GenSigSendType" SG_ 1116 TSCM_NMLimpHome 1;
BA_ "Remark" SG_ 1116 TSCM_NMRing "";
BA_ "GenSigSendType" SG_ 1116 TSCM_NMRing 1;
BA_ "Remark" SG_ 1116 TSCM_NMAlive "";
BA_ "GenSigSendType" SG_ 1116 TSCM_NMAlive 1;
BA_ "Remark" SG_ 1116 TSCM_NMDestAddress "";
BA_ "GenSigSendType" SG_ 1116 TSCM_NMDestAddress 1;
BA_ "Remark" SG_ 1076 MSM_NMDataField "";
BA_ "GenSigSendType" SG_ 1076 MSM_NMDataField 1;
BA_ "Remark" SG_ 1076 MSM_NMWakeupOrignin "";
BA_ "GenSigSendType" SG_ 1076 MSM_NMWakeupOrignin 1;
BA_ "Remark" SG_ 1076 MSM_NMSleepAck "";
BA_ "GenSigSendType" SG_ 1076 MSM_NMSleepAck 1;
BA_ "Remark" SG_ 1076 MSM_NMSleepInd "";
BA_ "GenSigSendType" SG_ 1076 MSM_NMSleepInd 1;
BA_ "Remark" SG_ 1076 MSM_NMLimpHome "";
BA_ "GenSigSendType" SG_ 1076 MSM_NMLimpHome 1;
BA_ "Remark" SG_ 1076 MSM_NMRing "";
BA_ "GenSigSendType" SG_ 1076 MSM_NMRing 1;
BA_ "Remark" SG_ 1076 MSM_NMAlive "";
BA_ "GenSigSendType" SG_ 1076 MSM_NMAlive 1;
BA_ "Remark" SG_ 1076 MSM_NMDestAddress "";
BA_ "GenSigSendType" SG_ 1076 MSM_NMDestAddress 1;
BA_ "Remark" SG_ 183 MSM_SteeringExtentCurrentPst "";
BA_ "EventCommandSignal" SG_ 183 MSM_SteeringExtentCurrentPst 1;
BA_ "GenSigStartValue" SG_ 183 MSM_SteeringExtentCurrentPst 127;
BA_ "Remark" SG_ 183 MSM_SteeringAngelCurrentPst "";
BA_ "EventCommandSignal" SG_ 183 MSM_SteeringAngelCurrentPst 1;
BA_ "GenSigStartValue" SG_ 183 MSM_SteeringAngelCurrentPst 127;
BA_ "Remark" SG_ 183 MSM_LHSeatTiltCurrentPst "";
BA_ "EventCommandSignal" SG_ 183 MSM_LHSeatTiltCurrentPst 1;
BA_ "GenSigStartValue" SG_ 183 MSM_LHSeatTiltCurrentPst 127;
BA_ "Remark" SG_ 183 MSM_LHSeatliftCurrentPst "";
BA_ "EventCommandSignal" SG_ 183 MSM_LHSeatliftCurrentPst 1;
BA_ "GenSigStartValue" SG_ 183 MSM_LHSeatliftCurrentPst 127;
BA_ "Remark" SG_ 183 MSM_LHSeatBackrestCurrentPst "";
BA_ "EventCommandSignal" SG_ 183 MSM_LHSeatBackrestCurrentPst 1;
BA_ "GenSigStartValue" SG_ 183 MSM_LHSeatBackrestCurrentPst 127;
BA_ "Remark" SG_ 183 MSM_LHSeatSlideCurrentPst "";
BA_ "EventCommandSignal" SG_ 183 MSM_LHSeatSlideCurrentPst 1;
BA_ "GenSigStartValue" SG_ 183 MSM_LHSeatSlideCurrentPst 127;
BA_ "Remark" SG_ 833 MSM_SeatNapModeSt "";
BA_ "GenSigSendType" SG_ 833 MSM_SeatNapModeSt 1;
BA_ "Remark" SG_ 833 MSM_SeatPosSaveReq "";
BA_ "GenSigSendType" SG_ 833 MSM_SeatPosSaveReq 1;
BA_ "Remark" SG_ 833 MSM_VoiceCtrlResp "";
BA_ "GenSigSendType" SG_ 833 MSM_VoiceCtrlResp 1;
BA_ "Remark" SG_ 833 MSM_SeatNapModePositionSt "";
BA_ "GenSigSendType" SG_ 833 MSM_SeatNapModePositionSt 1;
BA_ "Remark" SG_ 833 MSM_WelcomeFuncCfgSt "";
BA_ "GenSigSendType" SG_ 833 MSM_WelcomeFuncCfgSt 1;
BA_ "Remark" SG_ 1100 AMP_NMDataField "";
BA_ "GenSigSendType" SG_ 1100 AMP_NMDataField 1;
BA_ "Remark" SG_ 1100 AMP_NMWakeupOrigin "";
BA_ "GenSigSendType" SG_ 1100 AMP_NMWakeupOrigin 1;
BA_ "Remark" SG_ 1100 AMP_NMSleepAck "";
BA_ "GenSigSendType" SG_ 1100 AMP_NMSleepAck 1;
BA_ "Remark" SG_ 1100 AMP_NMSleepInd "";
BA_ "GenSigSendType" SG_ 1100 AMP_NMSleepInd 1;
BA_ "Remark" SG_ 1100 AMP_NMLimpHome "";
BA_ "GenSigSendType" SG_ 1100 AMP_NMLimpHome 1;
BA_ "Remark" SG_ 1100 AMP_NMRing "";
BA_ "GenSigSendType" SG_ 1100 AMP_NMRing 1;
BA_ "Remark" SG_ 1100 AMP_NMAlive "";
BA_ "GenSigSendType" SG_ 1100 AMP_NMAlive 1;
BA_ "Remark" SG_ 1100 AMP_NMDestAddress "";
BA_ "GenSigSendType" SG_ 1100 AMP_NMDestAddress 1;
BA_ "EventCommandSignal" SG_ 155 AMP_RingVolSet 1;
BA_ "GenSigStartValue" SG_ 155 AMP_RingVolSet 15;
BA_ "Remark" SG_ 155 AMP_A2BSet "";
BA_ "GenSigStartValue" SG_ 155 AMP_A2BSet 3;
BA_ "Remark" SG_ 155 AMP_ANC_SwitchStatus "";
BA_ "EventCommandSignal" SG_ 155 AMP_ANC_SwitchStatus 1;
BA_ "GenSigStartValue" SG_ 155 AMP_ANC_SwitchStatus 3;
BA_ "Remark" SG_ 155 AMP_ICCSts "";
BA_ "EventCommandSignal" SG_ 155 AMP_ICCSts 1;
BA_ "GenSigStartValue" SG_ 155 AMP_ICCSts 10;
BA_ "Remark" SG_ 155 AMP_ESESts "";
BA_ "EventCommandSignal" SG_ 155 AMP_ESESts 1;
BA_ "GenSigStartValue" SG_ 155 AMP_ESESts 10;
BA_ "Remark" SG_ 155 AMP_SoundmodeSet "";
BA_ "EventCommandSignal" SG_ 155 AMP_SoundmodeSet 1;
BA_ "GenSigStartValue" SG_ 155 AMP_SoundmodeSet 3;
BA_ "Remark" SG_ 155 AMP_YamahaSoundMode "";
BA_ "EventCommandSignal" SG_ 155 AMP_YamahaSoundMode 1;
BA_ "GenSigStartValue" SG_ 155 AMP_YamahaSoundMode 3;
BA_ "Remark" SG_ 155 AMP_AdigoVirtualLiveSeSts "";
BA_ "EventCommandSignal" SG_ 155 AMP_AdigoVirtualLiveSeSts 1;
BA_ "GenSigStartValue" SG_ 155 AMP_AdigoVirtualLiveSeSts 3;
BA_ "Remark" SG_ 155 AMP_Headrest_Mode "";
BA_ "EventCommandSignal" SG_ 155 AMP_Headrest_Mode 1;
BA_ "GenSigStartValue" SG_ 155 AMP_Headrest_Mode 3;
BA_ "Remark" SG_ 155 AMP_StrSurSet "";
BA_ "EventCommandSignal" SG_ 155 AMP_StrSurSet 1;
BA_ "GenSigStartValue" SG_ 155 AMP_StrSurSet 2;
BA_ "Remark" SG_ 155 AMP_HeadrestRightVolumeSt "";
BA_ "EventCommandSignal" SG_ 155 AMP_HeadrestRightVolumeSt 1;
BA_ "GenSigStartValue" SG_ 155 AMP_HeadrestRightVolumeSt 10;
BA_ "Remark" SG_ 155 AMP_HeadrestLeftVolumeSt "";
BA_ "EventCommandSignal" SG_ 155 AMP_HeadrestLeftVolumeSt 1;
BA_ "GenSigStartValue" SG_ 155 AMP_HeadrestLeftVolumeSt 10;
BA_ "Remark" SG_ 155 AMP_WarningSourceSts "";
BA_ "EventCommandSignal" SG_ 155 AMP_WarningSourceSts 1;
BA_ "GenSigStartValue" SG_ 155 AMP_WarningSourceSts 15;
BA_ "Remark" SG_ 155 AMP_Headrest_PrivateModeMuteSts "";
BA_ "EventCommandSignal" SG_ 155 AMP_Headrest_PrivateModeMuteSts 1;
BA_ "GenSigStartValue" SG_ 155 AMP_Headrest_PrivateModeMuteSts 2;
BA_ "Remark" SG_ 155 AMP_VRSourceSts "";
BA_ "EventCommandSignal" SG_ 155 AMP_VRSourceSts 1;
BA_ "GenSigStartValue" SG_ 155 AMP_VRSourceSts 7;
BA_ "Remark" SG_ 155 AMP_TelSourceSts "";
BA_ "EventCommandSignal" SG_ 155 AMP_TelSourceSts 1;
BA_ "GenSigStartValue" SG_ 155 AMP_TelSourceSts 7;
BA_ "Remark" SG_ 187 AMP_NaviVolSetSt "Reserved";
BA_ "EventCommandSignal" SG_ 187 AMP_NaviVolSetSt 1;
BA_ "GenSigSendType" SG_ 187 AMP_NaviVolSetSt 1;
BA_ "GenSigStartValue" SG_ 187 AMP_NaviVolSetSt 63;
BA_ "Remark" SG_ 187 AMP_MainVolSetSt "";
BA_ "EventCommandSignal" SG_ 187 AMP_MainVolSetSt 1;
BA_ "GenSigSendType" SG_ 187 AMP_MainVolSetSt 1;
BA_ "GenSigStartValue" SG_ 187 AMP_MainVolSetSt 63;
BA_ "Remark" SG_ 187 AMP_TelVolSetSts "";
BA_ "EventCommandSignal" SG_ 187 AMP_TelVolSetSts 1;
BA_ "GenSigSendType" SG_ 187 AMP_TelVolSetSts 1;
BA_ "GenSigStartValue" SG_ 187 AMP_TelVolSetSts 3;
BA_ "Remark" SG_ 187 AMP_EQModeSts "";
BA_ "EventCommandSignal" SG_ 187 AMP_EQModeSts 1;
BA_ "GenSigSendType" SG_ 187 AMP_EQModeSts 1;
BA_ "GenSigStartValue" SG_ 187 AMP_EQModeSts 3;
BA_ "Remark" SG_ 187 AMP_VRVolSetSts "";
BA_ "EventCommandSignal" SG_ 187 AMP_VRVolSetSts 1;
BA_ "GenSigSendType" SG_ 187 AMP_VRVolSetSts 1;
BA_ "GenSigStartValue" SG_ 187 AMP_VRVolSetSts 63;
BA_ "Remark" SG_ 187 AMP_VolValue "Reserved";
BA_ "EventCommandSignal" SG_ 187 AMP_VolValue 1;
BA_ "GenSigSendType" SG_ 187 AMP_VolValue 1;
BA_ "GenSigStartValue" SG_ 187 AMP_VolValue 255;
BA_ "Remark" SG_ 187 AMP_TempValue "Reserved";
BA_ "EventCommandSignal" SG_ 187 AMP_TempValue 1;
BA_ "GenSigSendType" SG_ 187 AMP_TempValue 1;
BA_ "GenSigStartValue" SG_ 187 AMP_TempValue 255;
BA_ "Remark" SG_ 188 AMP_SpeakMid "";
BA_ "EventCommandSignal" SG_ 188 AMP_SpeakMid 1;
BA_ "GenSigSendType" SG_ 188 AMP_SpeakMid 1;
BA_ "GenSigStartValue" SG_ 188 AMP_SpeakMid 3;
BA_ "Remark" SG_ 188 AMP_SpeakrRR "";
BA_ "EventCommandSignal" SG_ 188 AMP_SpeakrRR 1;
BA_ "GenSigSendType" SG_ 188 AMP_SpeakrRR 1;
BA_ "GenSigStartValue" SG_ 188 AMP_SpeakrRR 3;
BA_ "Remark" SG_ 188 AMP_SpeakrRL "";
BA_ "EventCommandSignal" SG_ 188 AMP_SpeakrRL 1;
BA_ "GenSigSendType" SG_ 188 AMP_SpeakrRL 1;
BA_ "GenSigStartValue" SG_ 188 AMP_SpeakrRL 3;
BA_ "Remark" SG_ 188 AMP_SpeakrFR "";
BA_ "EventCommandSignal" SG_ 188 AMP_SpeakrFR 1;
BA_ "GenSigSendType" SG_ 188 AMP_SpeakrFR 1;
BA_ "GenSigStartValue" SG_ 188 AMP_SpeakrFR 3;
BA_ "Remark" SG_ 188 AMP_SpeakFL "";
BA_ "EventCommandSignal" SG_ 188 AMP_SpeakFL 1;
BA_ "GenSigSendType" SG_ 188 AMP_SpeakFL 1;
BA_ "GenSigStartValue" SG_ 188 AMP_SpeakFL 3;
BA_ "Remark" SG_ 188 AMP_MediaSourceSt "";
BA_ "EventCommandSignal" SG_ 188 AMP_MediaSourceSt 1;
BA_ "GenSigSendType" SG_ 188 AMP_MediaSourceSt 1;
BA_ "GenSigStartValue" SG_ 188 AMP_MediaSourceSt 15;
BA_ "Remark" SG_ 188 AMP_ClariFiSt "";
BA_ "EventCommandSignal" SG_ 188 AMP_ClariFiSt 1;
BA_ "GenSigSendType" SG_ 188 AMP_ClariFiSt 1;
BA_ "GenSigStartValue" SG_ 188 AMP_ClariFiSt 3;
BA_ "Remark" SG_ 188 AMP_PowerSts "";
BA_ "EventCommandSignal" SG_ 188 AMP_PowerSts 1;
BA_ "GenSigSendType" SG_ 188 AMP_PowerSts 1;
BA_ "GenSigStartValue" SG_ 188 AMP_PowerSts 3;
BA_ "Remark" SG_ 188 AMP_HighFrqSet "";
BA_ "EventCommandSignal" SG_ 188 AMP_HighFrqSet 1;
BA_ "GenSigSendType" SG_ 188 AMP_HighFrqSet 1;
BA_ "GenSigStartValue" SG_ 188 AMP_HighFrqSet 31;
BA_ "Remark" SG_ 188 AMP_TreSurSetSt "";
BA_ "EventCommandSignal" SG_ 188 AMP_TreSurSetSt 1;
BA_ "GenSigSendType" SG_ 188 AMP_TreSurSetSt 1;
BA_ "GenSigStartValue" SG_ 188 AMP_TreSurSetSt 3;
BA_ "Remark" SG_ 188 AMP_GetHUTInfoSts "";
BA_ "EventCommandSignal" SG_ 188 AMP_GetHUTInfoSts 1;
BA_ "GenSigSendType" SG_ 188 AMP_GetHUTInfoSts 1;
BA_ "GenSigStartValue" SG_ 188 AMP_GetHUTInfoSts 3;
BA_ "Remark" SG_ 188 AMP_TEL_ECallSts "";
BA_ "EventCommandSignal" SG_ 188 AMP_TEL_ECallSts 1;
BA_ "GenSigSendType" SG_ 188 AMP_TEL_ECallSts 1;
BA_ "GenSigStartValue" SG_ 188 AMP_TEL_ECallSts 3;
BA_ "Remark" SG_ 188 AMP_MuteRearSet "";
BA_ "EventCommandSignal" SG_ 188 AMP_MuteRearSet 1;
BA_ "GenSigSendType" SG_ 188 AMP_MuteRearSet 1;
BA_ "GenSigStartValue" SG_ 188 AMP_MuteRearSet 3;
BA_ "Remark" SG_ 188 AMP_MuteSt "";
BA_ "EventCommandSignal" SG_ 188 AMP_MuteSt 1;
BA_ "GenSigSendType" SG_ 188 AMP_MuteSt 1;
BA_ "GenSigStartValue" SG_ 188 AMP_MuteSt 3;
BA_ "Remark" SG_ 188 AMP_DriveSideSt "";
BA_ "EventCommandSignal" SG_ 188 AMP_DriveSideSt 1;
BA_ "GenSigSendType" SG_ 188 AMP_DriveSideSt 1;
BA_ "GenSigStartValue" SG_ 188 AMP_DriveSideSt 3;
BA_ "Remark" SG_ 188 AMP_MidFrqSet "";
BA_ "EventCommandSignal" SG_ 188 AMP_MidFrqSet 1;
BA_ "GenSigSendType" SG_ 188 AMP_MidFrqSet 1;
BA_ "GenSigStartValue" SG_ 188 AMP_MidFrqSet 31;
BA_ "Remark" SG_ 188 AMP_LowFrqSet "";
BA_ "EventCommandSignal" SG_ 188 AMP_LowFrqSet 1;
BA_ "GenSigSendType" SG_ 188 AMP_LowFrqSet 1;
BA_ "GenSigStartValue" SG_ 188 AMP_LowFrqSet 31;
BA_ "Remark" SG_ 188 AMP_VSCModeSt "";
BA_ "EventCommandSignal" SG_ 188 AMP_VSCModeSt 1;
BA_ "GenSigSendType" SG_ 188 AMP_VSCModeSt 1;
BA_ "GenSigStartValue" SG_ 188 AMP_VSCModeSt 7;
BA_ "Remark" SG_ 188 AMP_NaviSourceSt "";
BA_ "EventCommandSignal" SG_ 188 AMP_NaviSourceSt 1;
BA_ "GenSigSendType" SG_ 188 AMP_NaviSourceSt 1;
BA_ "GenSigStartValue" SG_ 188 AMP_NaviSourceSt 7;
BA_ "Remark" SG_ 188 AMP_FadeSetSt "";
BA_ "EventCommandSignal" SG_ 188 AMP_FadeSetSt 1;
BA_ "GenSigSendType" SG_ 188 AMP_FadeSetSt 1;
BA_ "GenSigStartValue" SG_ 188 AMP_FadeSetSt 31;
BA_ "Remark" SG_ 188 AMP_BeepSourceSts "";
BA_ "EventCommandSignal" SG_ 188 AMP_BeepSourceSts 1;
BA_ "GenSigSendType" SG_ 188 AMP_BeepSourceSts 1;
BA_ "GenSigStartValue" SG_ 188 AMP_BeepSourceSts 7;
BA_ "Remark" SG_ 188 AMP_BlcSetSt "";
BA_ "EventCommandSignal" SG_ 188 AMP_BlcSetSt 1;
BA_ "GenSigSendType" SG_ 188 AMP_BlcSetSt 1;
BA_ "GenSigStartValue" SG_ 188 AMP_BlcSetSt 31;
BA_ "Remark" SG_ 1049 FRDCM_NMDataField "";
BA_ "GenSigSendType" SG_ 1049 FRDCM_NMDataField 1;
BA_ "Remark" SG_ 1049 FRDCM_NMWakeupOrigin "";
BA_ "GenSigSendType" SG_ 1049 FRDCM_NMWakeupOrigin 1;
BA_ "Remark" SG_ 1049 FRDCM_NMSleepAck "";
BA_ "GenSigSendType" SG_ 1049 FRDCM_NMSleepAck 1;
BA_ "Remark" SG_ 1049 FRDCM_NMSleepInd "";
BA_ "GenSigSendType" SG_ 1049 FRDCM_NMSleepInd 1;
BA_ "Remark" SG_ 1049 FRDCM_NMLimpHome "";
BA_ "GenSigSendType" SG_ 1049 FRDCM_NMLimpHome 1;
BA_ "Remark" SG_ 1049 FRDCM_NMRing "";
BA_ "GenSigSendType" SG_ 1049 FRDCM_NMRing 1;
BA_ "Remark" SG_ 1049 FRDCM_NMAlive "";
BA_ "GenSigSendType" SG_ 1049 FRDCM_NMAlive 1;
BA_ "Remark" SG_ 1049 FRDCM_NMDestAddress "";
BA_ "GenSigSendType" SG_ 1049 FRDCM_NMDestAddress 1;
BA_ "Remark" SG_ 999 FRDCM_RRWinVentilateModeSt "";
BA_ "GenSigSendType" SG_ 999 FRDCM_RRWinVentilateModeSt 1;
BA_ "Remark" SG_ 999 FRDCM_FRWinVentilateModeSt "";
BA_ "GenSigSendType" SG_ 999 FRDCM_FRWinVentilateModeSt 1;
BA_ "Remark" SG_ 999 FRDCM_RRWinOverheatSt "";
BA_ "GenSigSendType" SG_ 999 FRDCM_RRWinOverheatSt 1;
BA_ "Remark" SG_ 999 FRDCM_FRWinOverheatSt "";
BA_ "GenSigSendType" SG_ 999 FRDCM_FRWinOverheatSt 1;
BA_ "Remark" SG_ 999 FRDCM_MirrorFoldUnfoldSt "";
BA_ "GenSigSendType" SG_ 999 FRDCM_MirrorFoldUnfoldSt 1;
BA_ "Remark" SG_ 999 FRDCM_RRChildLockSt "";
BA_ "GenSigSendType" SG_ 999 FRDCM_RRChildLockSt 1;
BA_ "Remark" SG_ 999 FRDCM_RRWinOperationSt "";
BA_ "GenSigSendType" SG_ 999 FRDCM_RRWinOperationSt 1;
BA_ "Remark" SG_ 999 FRDCM_FRWinOperationSt "";
BA_ "GenSigSendType" SG_ 999 FRDCM_FRWinOperationSt 1;
BA_ "Remark" SG_ 999 FRDCM_RRWinSt "";
BA_ "GenSigSendType" SG_ 999 FRDCM_RRWinSt 1;
BA_ "Remark" SG_ 999 FRDCM_FRWinSt "";
BA_ "GenSigSendType" SG_ 999 FRDCM_FRWinSt 1;
BA_ "Remark" SG_ 999 FRDCM_RRWinPst "";
BA_ "GenSigSendType" SG_ 999 FRDCM_RRWinPst 1;
BA_ "GenSigStartValue" SG_ 999 FRDCM_RRWinPst 255;
BA_ "Remark" SG_ 999 FRDCM_FRWinPst "";
BA_ "GenSigSendType" SG_ 999 FRDCM_FRWinPst 1;
BA_ "GenSigStartValue" SG_ 999 FRDCM_FRWinPst 255;
BA_ "Remark" SG_ 1048 FLDCM_NMDataField "";
BA_ "GenSigSendType" SG_ 1048 FLDCM_NMDataField 1;
BA_ "Remark" SG_ 1048 FLDCM_NMWakeupOrigin "";
BA_ "GenSigSendType" SG_ 1048 FLDCM_NMWakeupOrigin 1;
BA_ "Remark" SG_ 1048 FLDCM_NMSleepAck "";
BA_ "GenSigSendType" SG_ 1048 FLDCM_NMSleepAck 1;
BA_ "Remark" SG_ 1048 FLDCM_NMSleepInd "";
BA_ "GenSigSendType" SG_ 1048 FLDCM_NMSleepInd 1;
BA_ "Remark" SG_ 1048 FLDCM_NMLimpHome "";
BA_ "GenSigSendType" SG_ 1048 FLDCM_NMLimpHome 1;
BA_ "Remark" SG_ 1048 FLDCM_NMRing "";
BA_ "GenSigSendType" SG_ 1048 FLDCM_NMRing 1;
BA_ "Remark" SG_ 1048 FLDCM_NMAlive "";
BA_ "GenSigSendType" SG_ 1048 FLDCM_NMAlive 1;
BA_ "Remark" SG_ 1048 FLDCM_NMDestAddress "";
BA_ "GenSigSendType" SG_ 1048 FLDCM_NMDestAddress 1;
BA_ "Remark" SG_ 997 FLDCM_RLWinVentilateModeSt "";
BA_ "GenSigSendType" SG_ 997 FLDCM_RLWinVentilateModeSt 1;
BA_ "Remark" SG_ 997 FLDCM_FLWinVentilateModeSt "";
BA_ "GenSigSendType" SG_ 997 FLDCM_FLWinVentilateModeSt 1;
BA_ "Remark" SG_ 997 FLDCM_MirrorFoldUnfoldSt "";
BA_ "GenSigSendType" SG_ 997 FLDCM_MirrorFoldUnfoldSt 1;
BA_ "Remark" SG_ 997 FLDCM_RLWinOperationSt "";
BA_ "GenSigSendType" SG_ 997 FLDCM_RLWinOperationSt 1;
BA_ "Remark" SG_ 997 FLDCM_FLWinOperationSt "";
BA_ "GenSigSendType" SG_ 997 FLDCM_FLWinOperationSt 1;
BA_ "Remark" SG_ 997 FLDCM_OSRMAngleAdjFuncCfgSt "";
BA_ "GenSigSendType" SG_ 997 FLDCM_OSRMAngleAdjFuncCfgSt 1;
BA_ "Remark" SG_ 997 FLDCM_MemorySysBuzzerReq "";
BA_ "GenSigSendType" SG_ 997 FLDCM_MemorySysBuzzerReq 1;
BA_ "Remark" SG_ 997 FLDCM_RLWinOverheatSt "";
BA_ "GenSigSendType" SG_ 997 FLDCM_RLWinOverheatSt 1;
BA_ "Remark" SG_ 997 FLDCM_FLWinOverheatSt "";
BA_ "GenSigSendType" SG_ 997 FLDCM_FLWinOverheatSt 1;
BA_ "Remark" SG_ 997 FLDCM_APWLEnableSt "";
BA_ "GenSigSendType" SG_ 997 FLDCM_APWLEnableSt 1;
BA_ "Remark" SG_ 997 FLDCM_PowerWinOpenWarn "";
BA_ "GenSigSendType" SG_ 997 FLDCM_PowerWinOpenWarn 1;
BA_ "Remark" SG_ 997 FLDCM_MemSysOperationReq "";
BA_ "GenSigSendType" SG_ 997 FLDCM_MemSysOperationReq 1;
BA_ "Remark" SG_ 997 FLDCM_RLChildLockSt "";
BA_ "GenSigSendType" SG_ 997 FLDCM_RLChildLockSt 1;
BA_ "Remark" SG_ 997 FLDCM_RLWinSt "";
BA_ "GenSigSendType" SG_ 997 FLDCM_RLWinSt 1;
BA_ "Remark" SG_ 997 FLDCM_FLWinSt "";
BA_ "GenSigSendType" SG_ 997 FLDCM_FLWinSt 1;
BA_ "Remark" SG_ 997 FLDCM_RLWinPst "";
BA_ "GenSigSendType" SG_ 997 FLDCM_RLWinPst 1;
BA_ "GenSigStartValue" SG_ 997 FLDCM_RLWinPst 255;
BA_ "Remark" SG_ 997 FLDCM_FLWinPst "";
BA_ "GenSigSendType" SG_ 997 FLDCM_FLWinPst 1;
BA_ "GenSigStartValue" SG_ 997 FLDCM_FLWinPst 255;
BA_ "Remark" SG_ 1070 IAL_NMDataField "";
BA_ "GenSigSendType" SG_ 1070 IAL_NMDataField 1;
BA_ "Remark" SG_ 1070 IAL_NMWakeupOrignin "";
BA_ "GenSigSendType" SG_ 1070 IAL_NMWakeupOrignin 1;
BA_ "Remark" SG_ 1070 IAL_NMSleepAck "";
BA_ "GenSigSendType" SG_ 1070 IAL_NMSleepAck 1;
BA_ "Remark" SG_ 1070 IAL_NMSleepInd "";
BA_ "GenSigSendType" SG_ 1070 IAL_NMSleepInd 1;
BA_ "Remark" SG_ 1070 IAL_NMLimpHome "";
BA_ "GenSigSendType" SG_ 1070 IAL_NMLimpHome 1;
BA_ "Remark" SG_ 1070 IAL_NMRing "";
BA_ "GenSigSendType" SG_ 1070 IAL_NMRing 1;
BA_ "Remark" SG_ 1070 IAL_NMAlive "";
BA_ "GenSigSendType" SG_ 1070 IAL_NMAlive 1;
BA_ "Remark" SG_ 1070 IAL_NMDestAddress "";
BA_ "GenSigSendType" SG_ 1070 IAL_NMDestAddress 1;
BA_ "Remark" SG_ 1023 IAL_LampColorSt "";
BA_ "GatewayedSignals" SG_ 1023 IAL_LampColorSt 1;
BA_ "GenSigSendType" SG_ 1023 IAL_LampColorSt 1;
BA_ "Remark" SG_ 1023 IAL_BrightnessSt "";
BA_ "GatewayedSignals" SG_ 1023 IAL_BrightnessSt 1;
BA_ "GenSigSendType" SG_ 1023 IAL_BrightnessSt 1;
BA_ "Remark" SG_ 1023 IAL_ShortcutMode "";
BA_ "GenSigSendType" SG_ 1023 IAL_ShortcutMode 1;
BA_ "Remark" SG_ 1023 IAL_LightWorkSt "";
BA_ "GatewayedSignals" SG_ 1023 IAL_LightWorkSt 1;
BA_ "GenSigSendType" SG_ 1023 IAL_LightWorkSt 1;
BA_ "Remark" SG_ 1023 Notused4 "";
BA_ "GenSigSendType" SG_ 1023 Notused4 1;
BA_ "Remark" SG_ 1023 Notused3 "";
BA_ "GenSigSendType" SG_ 1023 Notused3 1;
BA_ "Remark" SG_ 1023 IAL_WorkSt "";
BA_ "GenSigSendType" SG_ 1023 IAL_WorkSt 1;
BA_ "Remark" SG_ 847 HVSMR_RRSeatTemp "";
BA_ "GenSigSendType" SG_ 847 HVSMR_RRSeatTemp 1;
BA_ "GenSigStartValue" SG_ 847 HVSMR_RRSeatTemp 120;
BA_ "Remark" SG_ 847 HVSMR_RLSeatTemp "";
BA_ "GenSigSendType" SG_ 847 HVSMR_RLSeatTemp 1;
BA_ "GenSigStartValue" SG_ 847 HVSMR_RLSeatTemp 120;
BA_ "Remark" SG_ 847 HVSMR_RRHVSMRAutoModeSt "";
BA_ "GenSigSendType" SG_ 847 HVSMR_RRHVSMRAutoModeSt 1;
BA_ "Remark" SG_ 847 HVSMR_RRVentilatingActLevel "";
BA_ "GenSigSendType" SG_ 847 HVSMR_RRVentilatingActLevel 1;
BA_ "Remark" SG_ 847 HVSMR_RLHVSMRAutoModeSt "";
BA_ "GenSigSendType" SG_ 847 HVSMR_RLHVSMRAutoModeSt 1;
BA_ "Remark" SG_ 847 HVSMR_RLVentilatingActLevel "";
BA_ "GenSigSendType" SG_ 847 HVSMR_RLVentilatingActLevel 1;
BA_ "Remark" SG_ 847 HVSMR_RRSeatTempVD "";
BA_ "GenSigSendType" SG_ 847 HVSMR_RRSeatTempVD 1;
BA_ "Remark" SG_ 847 HVSMR_RRHeatingActLevel "";
BA_ "GenSigSendType" SG_ 847 HVSMR_RRHeatingActLevel 1;
BA_ "Remark" SG_ 847 HVSMR_RLSeatTempVD "";
BA_ "GenSigSendType" SG_ 847 HVSMR_RLSeatTempVD 1;
BA_ "Remark" SG_ 847 HVSMR_RLHeatingActLevel "";
BA_ "GenSigSendType" SG_ 847 HVSMR_RLHeatingActLevel 1;
BA_ "Remark" SG_ 1083 HVSM_NMDataField "";
BA_ "GenSigSendType" SG_ 1083 HVSM_NMDataField 1;
BA_ "Remark" SG_ 1083 HVSM_NMWakeupOrigin "";
BA_ "GenSigSendType" SG_ 1083 HVSM_NMWakeupOrigin 1;
BA_ "Remark" SG_ 1083 HVSM_NMSleepAck "";
BA_ "GenSigSendType" SG_ 1083 HVSM_NMSleepAck 1;
BA_ "Remark" SG_ 1083 HVSM_NMSleepInd "";
BA_ "GenSigSendType" SG_ 1083 HVSM_NMSleepInd 1;
BA_ "Remark" SG_ 1083 HVSM_NMLimpHome "";
BA_ "GenSigSendType" SG_ 1083 HVSM_NMLimpHome 1;
BA_ "Remark" SG_ 1083 HVSM_NMRing "";
BA_ "GenSigSendType" SG_ 1083 HVSM_NMRing 1;
BA_ "Remark" SG_ 1083 HVSM_NMAlive "";
BA_ "GenSigSendType" SG_ 1083 HVSM_NMAlive 1;
BA_ "Remark" SG_ 1083 HVSM_NMDestAddress "";
BA_ "GenSigSendType" SG_ 1083 HVSM_NMDestAddress 1;
BA_ "GenSigSendType" SG_ 846 HVSM_FRSeatTemp 1;
BA_ "GenSigStartValue" SG_ 846 HVSM_FRSeatTemp 120;
BA_ "GenSigSendType" SG_ 846 HVSM_FLSeatTemp 1;
BA_ "GenSigStartValue" SG_ 846 HVSM_FLSeatTemp 120;
BA_ "GenSigSendType" SG_ 846 HVSM_FRHVSMAutoModeSt 1;
BA_ "GenSigSendType" SG_ 846 HVSM_FLHVSMAutoModeSt 1;
BA_ "GenSigSendType" SG_ 846 HVSM_FRHeatingActLevel 1;
BA_ "GenSigSendType" SG_ 846 HVSM_FLHeatingActLevel 1;
BA_ "Remark" SG_ 846 HVSM_FRVentilatingActLevel "";
BA_ "GenSigSendType" SG_ 846 HVSM_FRVentilatingActLevel 1;
BA_ "Remark" SG_ 846 HVSM_FLVentilatingActLevel "";
BA_ "GenSigSendType" SG_ 846 HVSM_FLVentilatingActLevel 1;
BA_ "Remark" SG_ 1068 HVACF_NMDataField "";
BA_ "GenSigSendType" SG_ 1068 HVACF_NMDataField 1;
BA_ "Remark" SG_ 1068 HVACF_NMWakeupOrigin "";
BA_ "GenSigSendType" SG_ 1068 HVACF_NMWakeupOrigin 1;
BA_ "Remark" SG_ 1068 HVACF_NMSleepAck "";
BA_ "GenSigSendType" SG_ 1068 HVACF_NMSleepAck 1;
BA_ "Remark" SG_ 1068 HVACF_NMSleepInd "";
BA_ "GenSigSendType" SG_ 1068 HVACF_NMSleepInd 1;
BA_ "Remark" SG_ 1068 HVACF_NMLimpHome "";
BA_ "GenSigSendType" SG_ 1068 HVACF_NMLimpHome 1;
BA_ "Remark" SG_ 1068 HVACF_NMRing "";
BA_ "GenSigSendType" SG_ 1068 HVACF_NMRing 1;
BA_ "Remark" SG_ 1068 HVACF_NMAlive "";
BA_ "GenSigSendType" SG_ 1068 HVACF_NMAlive 1;
BA_ "Remark" SG_ 1068 HVACF_NMDestAddress "";
BA_ "GenSigSendType" SG_ 1068 HVACF_NMDestAddress 1;
BA_ "GenSigSendType" SG_ 972 HVAC_OneButtVentlaionSt 1;
BA_ "Remark" SG_ 972 HVAC_FRAG_FraganceBoxID "A8E修改2";
BA_ "GenSigSendType" SG_ 972 HVAC_FRAG_FraganceBoxID 1;
BA_ "Remark" SG_ 972 HVAC_FRAG_FraganceBoxLoad "A8E修改2";
BA_ "GenSigSendType" SG_ 972 HVAC_FRAG_FraganceBoxLoad 1;
BA_ "Remark" SG_ 972 HVACF_FRAG_FraganceBoxIDXRatioWa "";
BA_ "GenSigSendType" SG_ 972 HVACF_FRAG_FraganceBoxIDXRatioWa 1;
BA_ "SystemSignalLongSymbol" SG_ 972 HVACF_FRAG_FraganceBoxIDXRatioWa "HVACF_FRAG_FraganceBoxIDXRatioWarn";
BA_ "Remark" SG_ 972 HVAC_FRAG_FraganceConcentration "";
BA_ "GenSigSendType" SG_ 972 HVAC_FRAG_FraganceConcentration 1;
BA_ "Remark" SG_ 972 HVAC_FRAG_FraganceTaste "";
BA_ "GenSigSendType" SG_ 972 HVAC_FRAG_FraganceTaste 1;
BA_ "Remark" SG_ 972 HVAC_FRAG_FragceTastRemantRatio "";
BA_ "GenSigSendType" SG_ 972 HVAC_FRAG_FragceTastRemantRatio 1;
BA_ "Remark" SG_ 972 HVACF_FRAGCFunction "";
BA_ "GenSigSendType" SG_ 972 HVACF_FRAGCFunction 1;
BA_ "GenSigStartValue" SG_ 972 HVACF_FRAGCFunction 1;
BA_ "GenSigSendType" SG_ 969 HVACF_DualCircuSt 1;
BA_ "GenSigSendType" SG_ 969 HVACF_FreezeRearACSt 1;
BA_ "GenSigSendType" SG_ 969 HVACF_RearEvaporatorTempVD 1;
BA_ "GenSigSendType" SG_ 969 HVACF_RawRearCabinTempVD 1;
BA_ "GenSigSendType" SG_ 969 HVACF_RearEvaporatorTemp 1;
BA_ "GenSigStartValue" SG_ 969 HVACF_RawRearCabinTemp 120;
BA_ "GenSigSendType" SG_ 969 HVACF_RawRearCabinTemp 1;
BA_ "Remark" SG_ 969 HVACF_RearWindExitSpd "";
BA_ "GenSigSendType" SG_ 969 HVACF_RearWindExitSpd 1;
BA_ "Remark" SG_ 969 HVACF_IonPopUpReq "";
BA_ "GenSigSendType" SG_ 969 HVACF_IonPopUpReq 1;
BA_ "Remark" SG_ 969 HVACF_HumiditySns "";
BA_ "GenSigSendType" SG_ 969 HVACF_HumiditySns 1;
BA_ "Remark" SG_ 969 HVACF_UnlockVentilationSt "";
BA_ "GenSigSendType" SG_ 969 HVACF_UnlockVentilationSt 1;
BA_ "Remark" SG_ 969 HVACF_EvapratorSelfCleanSt "";
BA_ "GenSigSendType" SG_ 969 HVACF_EvapratorSelfCleanSt 1;
BA_ "Remark" SG_ 969 HVACF_PopupDisplayReq2 "";
BA_ "GenSigSendType" SG_ 969 HVACF_PopupDisplayReq2 1;
BA_ "Remark" SG_ 797 HVACF_SceneDisplayReq "";
BA_ "GenSigSendType" SG_ 797 HVACF_SceneDisplayReq 1;
BA_ "Remark" SG_ 797 HVACF_PM25CleanReqCfgSt "";
BA_ "GenSigSendType" SG_ 797 HVACF_PM25CleanReqCfgSt 1;
BA_ "GenSigStartValue" SG_ 797 HVACF_PM25CleanReqCfgSt 2;
BA_ "Remark" SG_ 797 HVACF_FanspeedCfgSt "";
BA_ "GenSigSendType" SG_ 797 HVACF_FanspeedCfgSt 1;
BA_ "GenSigStartValue" SG_ 797 HVACF_FanspeedCfgSt 2;
BA_ "Remark" SG_ 797 HVACF_PM25CleanReq "";
BA_ "GenSigSendType" SG_ 797 HVACF_PM25CleanReq 1;
BA_ "Remark" SG_ 797 HVACF_PM25Sns "";
BA_ "GenSigSendType" SG_ 797 HVACF_PM25Sns 1;
BA_ "Remark" SG_ 797 HVACF_PM10ValueVD "";
BA_ "GenSigSendType" SG_ 797 HVACF_PM10ValueVD 1;
BA_ "Remark" SG_ 797 HVACF_PM25ValueVD "";
BA_ "GenSigSendType" SG_ 797 HVACF_PM25ValueVD 1;
BA_ "Remark" SG_ 797 HVACF_PM10Value "";
BA_ "GenSigSendType" SG_ 797 HVACF_PM10Value 1;
BA_ "Remark" SG_ 797 HVACF_PM25Value "";
BA_ "GenSigSendType" SG_ 797 HVACF_PM25Value 1;
BA_ "Remark" SG_ 797 HVACF_AutoDefCfgSt "";
BA_ "GenSigSendType" SG_ 797 HVACF_AutoDefCfgSt 1;
BA_ "GenSigStartValue" SG_ 797 HVACF_AutoDefCfgSt 2;
BA_ "Remark" SG_ 797 HVACF_AirQqualitySenSt "";
BA_ "GenSigSendType" SG_ 797 HVACF_AirQqualitySenSt 1;
BA_ "GenSigStartValue" SG_ 797 HVACF_AirQqualitySenSt 1;
BA_ "Remark" SG_ 797 HVACF_ComfortCfgSt "";
BA_ "GenSigSendType" SG_ 797 HVACF_ComfortCfgSt 1;
BA_ "GenSigStartValue" SG_ 797 HVACF_ComfortCfgSt 1;
BA_ "Remark" SG_ 797 HVACF_AirCirCfgSt "";
BA_ "GenSigSendType" SG_ 797 HVACF_AirCirCfgSt 1;
BA_ "GenSigStartValue" SG_ 797 HVACF_AirCirCfgSt 1;
BA_ "Remark" SG_ 797 HVACF_ACCfgSt "";
BA_ "GenSigSendType" SG_ 797 HVACF_ACCfgSt 1;
BA_ "Remark" SG_ 801 HVACF_SmartSt "";
BA_ "GenSigSendType" SG_ 801 HVACF_SmartSt 1;
BA_ "Remark" SG_ 801 HVACF_RearWindExitMode "";
BA_ "GenSigSendType" SG_ 801 HVACF_RearWindExitMode 1;
BA_ "Remark" SG_ 801 HVACF_RearAutoSt "";
BA_ "GenSigSendType" SG_ 801 HVACF_RearAutoSt 1;
BA_ "Remark" SG_ 801 HVACF_AirQualitySns "";
BA_ "GenSigSendType" SG_ 801 HVACF_AirQualitySns 1;
BA_ "Remark" SG_ 801 HVACF_ZoneNum "";
BA_ "GenSigSendType" SG_ 801 HVACF_ZoneNum 1;
BA_ "Remark" SG_ 801 HVACF_RearSt "";
BA_ "GenSigSendType" SG_ 801 HVACF_RearSt 1;
BA_ "Remark" SG_ 801 HVACF_TripleZoneSt "";
BA_ "GenSigSendType" SG_ 801 HVACF_TripleZoneSt 1;
BA_ "Remark" SG_ 801 HVACF_RearTempSelect "";
BA_ "GenSigSendType" SG_ 801 HVACF_RearTempSelect 1;
BA_ "GenSigInvalidValue" SG_ 801 HVACF_RearTempSelect 31;
BA_ "GenSigStartValue" SG_ 801 HVACF_RearTempSelect 31;
BA_ "Remark" SG_ 800 HVACF_PsnTempSelect "";
BA_ "GenSigSendType" SG_ 800 HVACF_PsnTempSelect 1;
BA_ "GenSigInvalidValue" SG_ 800 HVACF_PsnTempSelect 31;
BA_ "GenSigStartValue" SG_ 800 HVACF_PsnTempSelect 31;
BA_ "Remark" SG_ 800 HVACF_WindExitSpd "";
BA_ "GatewayedSignals" SG_ 800 HVACF_WindExitSpd 1;
BA_ "GenSigSendType" SG_ 800 HVACF_WindExitSpd 1;
BA_ "Remark" SG_ 800 HVACF_IonMode "";
BA_ "GenSigSendType" SG_ 800 HVACF_IonMode 1;
BA_ "Remark" SG_ 800 HVACF_DriverTempSelect "";
BA_ "GenSigSendType" SG_ 800 HVACF_DriverTempSelect 1;
BA_ "GenSigInvalidValue" SG_ 800 HVACF_DriverTempSelect 31;
BA_ "GenSigStartValue" SG_ 800 HVACF_DriverTempSelect 31;
BA_ "Remark" SG_ 800 HVACF_PopUpDisplayReq1 "";
BA_ "GenSigSendType" SG_ 800 HVACF_PopUpDisplayReq1 1;
BA_ "Remark" SG_ 800 HVACF_AirCirculationSt "";
BA_ "GenSigSendType" SG_ 800 HVACF_AirCirculationSt 1;
BA_ "Remark" SG_ 800 HVACF_SYNCSt "";
BA_ "GenSigSendType" SG_ 800 HVACF_SYNCSt 1;
BA_ "Remark" SG_ 800 HVACF_TempSelectManual "";
BA_ "GenSigSendType" SG_ 800 HVACF_TempSelectManual 1;
BA_ "Remark" SG_ 800 HVACF_IonCleanFunction "";
BA_ "GenSigSendType" SG_ 800 HVACF_IonCleanFunction 1;
BA_ "GenSigStartValue" SG_ 800 HVACF_IonCleanFunction 1;
BA_ "Remark" SG_ 800 HVACF_WindExitMode "";
BA_ "GenSigSendType" SG_ 800 HVACF_WindExitMode 1;
BA_ "Remark" SG_ 800 HVACF_Type "";
BA_ "GenSigSendType" SG_ 800 HVACF_Type 1;
BA_ "GenSigStartValue" SG_ 800 HVACF_Type 1;
BA_ "Remark" SG_ 800 HVACF_AutoSt "";
BA_ "GenSigSendType" SG_ 800 HVACF_AutoSt 1;
BA_ "Remark" SG_ 800 HVACF_DualSyncSt "";
BA_ "GenSigSendType" SG_ 800 HVACF_DualSyncSt 1;
BA_ "Remark" SG_ 800 HVACF_TempSelectAuto "";
BA_ "GenSigSendType" SG_ 800 HVACF_TempSelectAuto 1;
BA_ "GenSigInvalidValue" SG_ 800 HVACF_TempSelectAuto 31;
BA_ "GenSigStartValue" SG_ 800 HVACF_TempSelectAuto 31;
BA_ "Remark" SG_ 800 HVACF_CorrectedExterTemp "";
BA_ "GenSigSendType" SG_ 800 HVACF_CorrectedExterTemp 1;
BA_ "GenSigStartValue" SG_ 800 HVACF_CorrectedExterTemp 120;
BA_ "Remark" SG_ 800 HVACF_ACSt "";
BA_ "GenSigSendType" SG_ 800 HVACF_ACSt 1;
BA_ "Remark" SG_ 800 HVACF_CorrectedExterTempVD "";
BA_ "GenSigSendType" SG_ 800 HVACF_CorrectedExterTempVD 1;
BA_ "Remark" SG_ 800 HVACF_RearDefrostSt "";
BA_ "GenSigSendType" SG_ 800 HVACF_RearDefrostSt 1;
BA_ "Remark" SG_ 1065 LCU_NMDataField "";
BA_ "GenSigSendType" SG_ 1065 LCU_NMDataField 1;
BA_ "Remark" SG_ 1065 LCU_NMWakeupOrigin "";
BA_ "GenSigSendType" SG_ 1065 LCU_NMWakeupOrigin 1;
BA_ "Remark" SG_ 1065 LCU_NMSleepAck "";
BA_ "GenSigSendType" SG_ 1065 LCU_NMSleepAck 1;
BA_ "Remark" SG_ 1065 LCU_NMSleepInd "";
BA_ "GenSigSendType" SG_ 1065 LCU_NMSleepInd 1;
BA_ "Remark" SG_ 1065 LCU_NMLimpHome "";
BA_ "GenSigSendType" SG_ 1065 LCU_NMLimpHome 1;
BA_ "Remark" SG_ 1065 LCU_NMRing "";
BA_ "GenSigSendType" SG_ 1065 LCU_NMRing 1;
BA_ "Remark" SG_ 1065 LCU_NMAlive "";
BA_ "GenSigSendType" SG_ 1065 LCU_NMAlive 1;
BA_ "Remark" SG_ 1065 LCU_NMDestAddress "";
BA_ "GenSigSendType" SG_ 1065 LCU_NMDestAddress 1;
BA_ "GenSigSendType" SG_ 669 LCU_AutoHoldLightEnable 1;
BA_ "GenSigSendType" SG_ 669 LCU_WelLightSt 1;
BA_ "Remark" SG_ 669 LCU_LightShowSt "";
BA_ "GenSigSendType" SG_ 669 LCU_LightShowSt 1;
BA_ "GenSigInvalidValue" SG_ 669 LCU_LightShowSt 4;
BA_ "Remark" SG_ 669 LCU_FRDRLSt "";
BA_ "GenSigSendType" SG_ 669 LCU_FRDRLSt 1;
BA_ "GenSigInvalidValue" SG_ 669 LCU_FRDRLSt 3;
BA_ "Remark" SG_ 669 LCU_FRHighBeamSt "";
BA_ "GenSigSendType" SG_ 669 LCU_FRHighBeamSt 1;
BA_ "GenSigInvalidValue" SG_ 669 LCU_FRHighBeamSt 3;
BA_ "Remark" SG_ 672 LCU_ALSFaultSt "";
BA_ "GenSigSendType" SG_ 672 LCU_ALSFaultSt 1;
BA_ "Remark" SG_ 672 LCU_ADBEnable "";
BA_ "GenSigSendType" SG_ 672 LCU_ADBEnable 1;
BA_ "Remark" SG_ 672 LCU_ADBSt "";
BA_ "GenSigSendType" SG_ 672 LCU_ADBSt 1;
BA_ "Remark" SG_ 672 LCU_FLDRLSt "";
BA_ "GenSigSendType" SG_ 672 LCU_FLDRLSt 1;
BA_ "GenSigInvalidValue" SG_ 672 LCU_FLDRLSt 3;
BA_ "Remark" SG_ 672 LCU_FLHighBeamSt "";
BA_ "GenSigSendType" SG_ 672 LCU_FLHighBeamSt 1;
BA_ "GenSigInvalidValue" SG_ 672 LCU_FLHighBeamSt 3;
BA_ "Remark" SG_ 1089 HUD_NMDataField "";
BA_ "GenSigSendType" SG_ 1089 HUD_NMDataField 1;
BA_ "Remark" SG_ 1089 HUD_NMWakeupOrigin "";
BA_ "GenSigSendType" SG_ 1089 HUD_NMWakeupOrigin 1;
BA_ "Remark" SG_ 1089 HUD_NMSleepAck "";
BA_ "GenSigSendType" SG_ 1089 HUD_NMSleepAck 1;
BA_ "Remark" SG_ 1089 HUD_NMSleepInd "";
BA_ "GenSigSendType" SG_ 1089 HUD_NMSleepInd 1;
BA_ "Remark" SG_ 1089 HUD_NMLimpHome "";
BA_ "GenSigSendType" SG_ 1089 HUD_NMLimpHome 1;
BA_ "Remark" SG_ 1089 HUD_NMRing "";
BA_ "GenSigSendType" SG_ 1089 HUD_NMRing 1;
BA_ "Remark" SG_ 1089 HUD_NMAlive "";
BA_ "GenSigSendType" SG_ 1089 HUD_NMAlive 1;
BA_ "Remark" SG_ 1089 HUD_NMDestAddress "";
BA_ "GenSigSendType" SG_ 1089 HUD_NMDestAddress 1;
BA_ "Remark" SG_ 996 HUD_ADASTSRDisEnable "";
BA_ "GenSigSendType" SG_ 996 HUD_ADASTSRDisEnable 1;
BA_ "GenSigInvalidValue" SG_ 996 HUD_ADASTSRDisEnable 1;
BA_ "Remark" SG_ 996 HUD_NAV "";
BA_ "GenSigSendType" SG_ 996 HUD_NAV 1;
BA_ "GenSigInvalidValue" SG_ 996 HUD_NAV 3;
BA_ "GenSigStartValue" SG_ 996 HUD_NAV 2;
BA_ "Remark" SG_ 996 HUD_AngleSt "";
BA_ "GenSigSendType" SG_ 996 HUD_AngleSt 1;
BA_ "GenSigInvalidValue" SG_ 996 HUD_AngleSt 21;
BA_ "GenSigStartValue" SG_ 996 HUD_AngleSt 10;
BA_ "Remark" SG_ 996 HUD_HeightSt "";
BA_ "GenSigSendType" SG_ 996 HUD_HeightSt 1;
BA_ "GenSigInvalidValue" SG_ 996 HUD_HeightSt 21;
BA_ "GenSigStartValue" SG_ 996 HUD_HeightSt 10;
BA_ "Remark" SG_ 996 HUD_ADASCruiseDisEnable "";
BA_ "GenSigSendType" SG_ 996 HUD_ADASCruiseDisEnable 1;
BA_ "GenSigInvalidValue" SG_ 996 HUD_ADASCruiseDisEnable 1;
BA_ "Remark" SG_ 996 HUD_BrightnessSt "";
BA_ "GenSigSendType" SG_ 996 HUD_BrightnessSt 1;
BA_ "GenSigInvalidValue" SG_ 996 HUD_BrightnessSt 21;
BA_ "GenSigStartValue" SG_ 996 HUD_BrightnessSt 10;
BA_ "Remark" SG_ 996 HUD_OffSt "";
BA_ "GenSigSendType" SG_ 996 HUD_OffSt 1;
BA_ "GenSigInvalidValue" SG_ 996 HUD_OffSt 3;
BA_ "Remark" SG_ 2015 Func_Diag_Request "";
BA_ "GenSigSendType" SG_ 2015 Func_Diag_Request 1;
BA_ "Remark" SG_ 1056 BCM_NMDataField "";
BA_ "GenSigSendType" SG_ 1056 BCM_NMDataField 1;
BA_ "Remark" SG_ 1056 BCM_NMWakeupOrignin "";
BA_ "GenSigSendType" SG_ 1056 BCM_NMWakeupOrignin 1;
BA_ "Remark" SG_ 1056 BCM_NMSleepAck "";
BA_ "GenSigSendType" SG_ 1056 BCM_NMSleepAck 1;
BA_ "Remark" SG_ 1056 BCM_NMSleepInd "";
BA_ "GenSigSendType" SG_ 1056 BCM_NMSleepInd 1;
BA_ "Remark" SG_ 1056 BCM_NMLimpHome "";
BA_ "GenSigSendType" SG_ 1056 BCM_NMLimpHome 1;
BA_ "Remark" SG_ 1056 BCM_NMRing "";
BA_ "GenSigSendType" SG_ 1056 BCM_NMRing 1;
BA_ "Remark" SG_ 1056 BCM_NMAlive "";
BA_ "GenSigSendType" SG_ 1056 BCM_NMAlive 1;
BA_ "Remark" SG_ 1056 BCM_NMDestAddress "";
BA_ "GenSigSendType" SG_ 1056 BCM_NMDestAddress 1;
BA_ "Remark" SG_ 1002 PEPS_NFC_ID "";
BA_ "GenSigSendType" SG_ 1002 PEPS_NFC_ID 1;
BA_ "Remark" SG_ 1002 PEPS_PUID "";
BA_ "GenSigSendType" SG_ 1002 PEPS_PUID 1;
BA_ "Remark" SG_ 799 PEPS_IdInVeWarningCfgSt "";
BA_ "EventCommandSignal" SG_ 799 PEPS_IdInVeWarningCfgSt 1;
BA_ "GenSigSendType" SG_ 799 PEPS_IdInVeWarningCfgSt 1;
BA_ "Remark" SG_ 799 PEPS_ESCLCfgSt "";
BA_ "GenSigSendType" SG_ 799 PEPS_ESCLCfgSt 1;
BA_ "Remark" SG_ 799 PEPS_APUCfgSt "";
BA_ "GenSigSendType" SG_ 799 PEPS_APUCfgSt 1;
BA_ "Remark" SG_ 799 PEPS_SATOCfgSt "";
BA_ "GenSigSendType" SG_ 799 PEPS_SATOCfgSt 1;
BA_ "Remark" SG_ 799 PEPS_KickSnsCfgSt "";
BA_ "GenSigSendType" SG_ 799 PEPS_KickSnsCfgSt 1;
BA_ "GenSigStartValue" SG_ 799 PEPS_KickSnsCfgSt 1;
BA_ "Remark" SG_ 799 PEPS_WALCfgSt "";
BA_ "GenSigSendType" SG_ 799 PEPS_WALCfgSt 1;
BA_ "Remark" SG_ 799 PEPS_MaxTeleEngTimerCfgSt "";
BA_ "GenSigSendType" SG_ 799 PEPS_MaxTeleEngTimerCfgSt 1;
BA_ "GenSigStartValue" SG_ 799 PEPS_MaxTeleEngTimerCfgSt 5;
BA_ "Remark" SG_ 799 PEPS_WELCfgSt "";
BA_ "GenSigSendType" SG_ 799 PEPS_WELCfgSt 1;
BA_ "Remark" SG_ 799 PEPS_MaxTeleIGNOnTimerCfgSt "";
BA_ "GenSigSendType" SG_ 799 PEPS_MaxTeleIGNOnTimerCfgSt 1;
BA_ "GenSigStartValue" SG_ 799 PEPS_MaxTeleIGNOnTimerCfgSt 3;
BA_ "Remark" SG_ 629 PEPS_IG1FailWarn "";
BA_ "GenSigSendType" SG_ 629 PEPS_IG1FailWarn 1;
BA_ "Remark" SG_ 629 PEPS_IdInVehicleWarning "";
BA_ "GenSigSendType" SG_ 629 PEPS_IdInVehicleWarning 1;
BA_ "Remark" SG_ 629 PEPS_EngForbidWarn "";
BA_ "GenSigSendType" SG_ 629 PEPS_EngForbidWarn 1;
BA_ "Remark" SG_ 629 PEPS_Crankallow "Only for AVNT";
BA_ "GenSigSendType" SG_ 629 PEPS_Crankallow 1;
BA_ "Remark" SG_ 629 PEPS_ETWS_St "";
BA_ "GenSigSendType" SG_ 629 PEPS_ETWS_St 1;
BA_ "Remark" SG_ 629 PEPS_KeyOutWarning "Only for AVNT";
BA_ "GenSigSendType" SG_ 629 PEPS_KeyOutWarning 1;
BA_ "Remark" SG_ 629 PEPS_KeyReminderWarning "Only for AVNT";
BA_ "GenSigSendType" SG_ 629 PEPS_KeyReminderWarning 1;
BA_ "Remark" SG_ 629 PEPS_DoorLockWarning "Only for AVNT";
BA_ "GenSigSendType" SG_ 629 PEPS_DoorLockWarning 1;
BA_ "Remark" SG_ 629 PEPS_FobBattLowWarning "Only for AVNT";
BA_ "GenSigSendType" SG_ 629 PEPS_FobBattLowWarning 1;
BA_ "Remark" SG_ 629 PEPS_ESCLWarning "Only for AVNT";
BA_ "GenSigSendType" SG_ 629 PEPS_ESCLWarning 1;
BA_ "Remark" SG_ 629 PEPS_SSBWarning "Only for AVNT";
BA_ "GenSigSendType" SG_ 629 PEPS_SSBWarning 1;
BA_ "Remark" SG_ 629 PEPS_DeactivationWarning "Only for AVNT";
BA_ "GenSigSendType" SG_ 629 PEPS_DeactivationWarning 1;
BA_ "Remark" SG_ 629 PEPS_OpIndicationWarning "Only for AVNT";
BA_ "GenSigSendType" SG_ 629 PEPS_OpIndicationWarning 1;
BA_ "Remark" SG_ 629 PEPS_AuthFailWarning "Only for AVNT";
BA_ "GenSigSendType" SG_ 629 PEPS_AuthFailWarning 1;
BA_ "Remark" SG_ 826 TPMS_RRTyreTemp "";
BA_ "GenSigSendType" SG_ 826 TPMS_RRTyreTemp 1;
BA_ "GenSigStartValue" SG_ 826 TPMS_RRTyreTemp 255;
BA_ "Remark" SG_ 826 TPMS_RLTyreTemp "";
BA_ "GenSigSendType" SG_ 826 TPMS_RLTyreTemp 1;
BA_ "GenSigStartValue" SG_ 826 TPMS_RLTyreTemp 255;
BA_ "Remark" SG_ 826 TPMS_FRTyreTemp "";
BA_ "GenSigSendType" SG_ 826 TPMS_FRTyreTemp 1;
BA_ "GenSigStartValue" SG_ 826 TPMS_FRTyreTemp 255;
BA_ "Remark" SG_ 826 TPMS_FLTyreTemp "";
BA_ "GenSigSendType" SG_ 826 TPMS_FLTyreTemp 1;
BA_ "GenSigStartValue" SG_ 826 TPMS_FLTyreTemp 255;
BA_ "Remark" SG_ 826 TPMS_RRTyrePr "";
BA_ "GenSigSendType" SG_ 826 TPMS_RRTyrePr 1;
BA_ "GenSigStartValue" SG_ 826 TPMS_RRTyrePr 255;
BA_ "Remark" SG_ 826 TPMS_RLTyrePr "";
BA_ "GenSigSendType" SG_ 826 TPMS_RLTyrePr 1;
BA_ "GenSigStartValue" SG_ 826 TPMS_RLTyrePr 255;
BA_ "Remark" SG_ 826 TPMS_FRTyrePr "";
BA_ "GenSigSendType" SG_ 826 TPMS_FRTyrePr 1;
BA_ "GenSigStartValue" SG_ 826 TPMS_FRTyrePr 255;
BA_ "Remark" SG_ 826 TPMS_FLTyrePr "";
BA_ "GenSigSendType" SG_ 826 TPMS_FLTyrePr 1;
BA_ "GenSigStartValue" SG_ 826 TPMS_FLTyrePr 255;
BA_ "Remark" SG_ 805 TPMS_RRTyreWarn "";
BA_ "GatewayedSignals" SG_ 805 TPMS_RRTyreWarn 1;
BA_ "GenSigSendType" SG_ 805 TPMS_RRTyreWarn 1;
BA_ "Remark" SG_ 805 TPMS_RLTyreWarn "";
BA_ "GatewayedSignals" SG_ 805 TPMS_RLTyreWarn 1;
BA_ "GenSigSendType" SG_ 805 TPMS_RLTyreWarn 1;
BA_ "Remark" SG_ 805 TPMS_FRTyreWarn "";
BA_ "GatewayedSignals" SG_ 805 TPMS_FRTyreWarn 1;
BA_ "GenSigSendType" SG_ 805 TPMS_FRTyreWarn 1;
BA_ "Remark" SG_ 805 TPMS_FLTyreWarn "";
BA_ "GatewayedSignals" SG_ 805 TPMS_FLTyreWarn 1;
BA_ "GenSigSendType" SG_ 805 TPMS_FLTyreWarn 1;
BA_ "Remark" SG_ 805 TPMS_TyreSt "";
BA_ "GatewayedSignals" SG_ 805 TPMS_TyreSt 1;
BA_ "GenSigSendType" SG_ 805 TPMS_TyreSt 1;
BA_ "Remark" SG_ 805 TPMS_SystemSt "";
BA_ "GatewayedSignals" SG_ 805 TPMS_SystemSt 1;
BA_ "GenSigSendType" SG_ 805 TPMS_SystemSt 1;
BA_ "GenSigStartValue" SG_ 805 TPMS_SystemSt 1;
BA_ "Remark" SG_ 974 BCM_TCH_CupholdHeatCoolAutoMdSt "";
BA_ "GenSigSendType" SG_ 974 BCM_TCH_CupholdHeatCoolAutoMdSt 1;
BA_ "GenSigStartValue" SG_ 974 BCM_TCH_CupholdHeatCoolAutoMdSt 2;
BA_ "Remark" SG_ 974 BCM_TCH_CupholderHeatCoolModeSt "";
BA_ "GenSigSendType" SG_ 974 BCM_TCH_CupholderHeatCoolModeSt 1;
BA_ "GenSigStartValue" SG_ 974 BCM_TCH_CupholderHeatCoolModeSt 3;
BA_ "Remark" SG_ 149 BCM_PCS_ButtonPress "";
BA_ "GenSigSendType" SG_ 149 BCM_PCS_ButtonPress 1;
BA_ "GenSigSendType" SG_ 1556 ACU_Freezepermissions_FuncCfg 1;
BA_ "GenSigSendType" SG_ 1556 BCM_HVSPRL_RLFreezPermiFuncCfgSt 1;
BA_ "GenSigSendType" SG_ 1556 HVSPRR_SPABUttonSt 1;
BA_ "GenSigSendType" SG_ 1556 HVSPRL_SPABUttonSt 1;
BA_ "Remark" SG_ 1556 MCMRR_MasMode "";
BA_ "GenSigSendType" SG_ 1556 MCMRR_MasMode 1;
BA_ "Remark" SG_ 1556 MCMRR_MasSt "";
BA_ "GenSigSendType" SG_ 1556 MCMRR_MasSt 1;
BA_ "Remark" SG_ 1556 MCMRR_MasIntensity "";
BA_ "GenSigSendType" SG_ 1556 MCMRR_MasIntensity 1;
BA_ "Remark" SG_ 1556 MCMRL_MasIntensity "";
BA_ "GenSigSendType" SG_ 1556 MCMRL_MasIntensity 1;
BA_ "Remark" SG_ 1556 MCMRL_MasMode "";
BA_ "GenSigSendType" SG_ 1556 MCMRL_MasMode 1;
BA_ "Remark" SG_ 1556 MCMRL_MasSt "";
BA_ "GenSigSendType" SG_ 1556 MCMRL_MasSt 1;
BA_ "GenSigSendType" SG_ 960 BCM_RefuelSwSt 1;
BA_ "Remark" SG_ 960 BCM_RainstormModeReq "";
BA_ "GenSigSendType" SG_ 960 BCM_RainstormModeReq 1;
BA_ "Remark" SG_ 960 BCM_SunshadePstSt "";
BA_ "GenSigSendType" SG_ 960 BCM_SunshadePstSt 1;
BA_ "Remark" SG_ 960 BCM_SunRoofPst "";
BA_ "GenSigSendType" SG_ 960 BCM_SunRoofPst 1;
BA_ "Remark" SG_ 960 BCM_VCU_UnlockACChgPortReqP "";
BA_ "GenSigSendType" SG_ 960 BCM_VCU_UnlockACChgPortReqP 1;
BA_ "Remark" SG_ 960 BCM_AmbientLightSt "";
BA_ "GenSigSendType" SG_ 960 BCM_AmbientLightSt 1;
BA_ "Remark" SG_ 960 BCM_FrontWiperSwitchSt "";
BA_ "GenSigSendType" SG_ 960 BCM_FrontWiperSwitchSt 1;
BA_ "Remark" SG_ 960 BCM_LampOnWarningReq "";
BA_ "GenSigSendType" SG_ 960 BCM_LampOnWarningReq 1;
BA_ "Remark" SG_ 960 BCM_SunRoofOpenWarning "";
BA_ "GenSigSendType" SG_ 960 BCM_SunRoofOpenWarning 1;
BA_ "Remark" SG_ 960 BCM_RearWiperSwitchSt "";
BA_ "GenSigSendType" SG_ 960 BCM_RearWiperSwitchSt 1;
BA_ "GenSigTimeoutValue" SG_ 960 BCM_SunshadePst 1;
BA_ "Remark" SG_ 960 BCM_SunshadePst "";
BA_ "GenSigSendType" SG_ 960 BCM_SunshadePst 1;
BA_ "Remark" SG_ 960 BCM_BrakeLightFaultSt "";
BA_ "GenSigSendType" SG_ 960 BCM_BrakeLightFaultSt 1;
BA_ "Remark" SG_ 960 BCM_BrakeLightSt "";
BA_ "GenSigSendType" SG_ 960 BCM_BrakeLightSt 1;
BA_ "Remark" SG_ 960 BCM_ReverseLightFaultSt "";
BA_ "GenSigSendType" SG_ 960 BCM_ReverseLightFaultSt 1;
BA_ "Remark" SG_ 960 BCM_ReverseLightSt "";
BA_ "GenSigSendType" SG_ 960 BCM_ReverseLightSt 1;
BA_ "Remark" SG_ 960 BCM_RLSWarningLight "";
BA_ "GenSigSendType" SG_ 960 BCM_RLSWarningLight 1;
BA_ "Remark" SG_ 960 BCM_RLSWarningRain "";
BA_ "GenSigSendType" SG_ 960 BCM_RLSWarningRain 1;
BA_ "Remark" SG_ 960 BCM_HazardLampSt "";
BA_ "GenSigSendType" SG_ 960 BCM_HazardLampSt 1;
VAL_ 1085 FCP_NMWakeupOrignin 255 "Reserved" 254 "Reserved" 253 "Reserved" 252 "Reserved" 251 "Reserved" 250 "Reserved" 249 "Reserved" 248 "Reserved" 247 "Reserved" 246 "Reserved" 245 "Reserved" 244 "Reserved" 243 "Reserved" 242 "Reserved" 241 "Reserved" 240 "Reserved" 239 "Reserved" 238 "Reserved" 237 "Reserved" 236 "Reserved" 235 "Reserved" 234 "Reserved" 233 "Reserved" 232 "Reserved" 231 "Reserved" 230 "Reserved" 229 "Reserved" 228 "Reserved" 227 "Reserved" 226 "Reserved" 225 "Reserved" 224 "Reserved" 223 "Reserved" 222 "Reserved" 221 "Reserved" 220 "Reserved" 219 "Reserved" 218 "Reserved" 217 "Reserved" 216 "Reserved" 215 "Reserved" 214 "Reserved" 213 "Reserved" 212 "Reserved" 211 "Reserved" 210 "Reserved" 209 "Reserved" 208 "Reserved" 207 "Reserved" 206 "Reserved" 205 "Reserved" 204 "Reserved" 203 "Reserved" 202 "Reserved" 201 "Reserved" 200 "Reserved" 199 "Reserved" 198 "Reserved" 197 "Reserved" 196 "Reserved" 195 "Reserved" 194 "Reserved" 193 "Reserved" 192 "Reserved" 191 "Reserved" 190 "Reserved" 189 "Reserved" 188 "Reserved" 187 "Reserved" 186 "Reserved" 185 "Reserved" 184 "Reserved" 183 "Reserved" 182 "Reserved" 181 "Reserved" 180 "Reserved" 179 "Reserved" 178 "Reserved" 177 "Reserved" 176 "Reserved" 175 "Reserved" 174 "Reserved" 173 "Reserved" 172 "Reserved" 171 "Reserved" 170 "Reserved" 169 "Reserved" 168 "Reserved" 167 "Reserved" 166 "Reserved" 165 "Reserved" 164 "Reserved" 163 "Reserved" 162 "Reserved" 161 "Reserved" 160 "Reserved" 159 "Reserved" 158 "Reserved" 157 "Reserved" 156 "Reserved" 155 "Reserved" 154 "Reserved" 153 "Reserved" 152 "Reserved" 151 "Reserved" 150 "Reserved" 149 "Reserved" 148 "Reserved" 147 "Reserved" 146 "Reserved" 145 "Reserved" 144 "Reserved" 143 "Reserved" 142 "Reserved" 141 "Reserved" 140 "Reserved" 139 "Reserved" 138 "Reserved" 137 "Reserved" 136 "Reserved" 135 "Reserved" 134 "Reserved" 133 "Reserved" 132 "Reserved" 131 "Reserved" 130 "Reserved" 129 "Reserved" 128 "Reserved" 127 "Reserved" 126 "Reserved" 125 "Reserved" 124 "Reserved" 123 "Reserved" 122 "Reserved" 121 "Reserved" 120 "Reserved" 119 "Reserved" 118 "Reserved" 117 "Reserved" 116 "Reserved" 115 "Reserved" 114 "Reserved" 113 "Reserved" 112 "Reserved" 111 "Reserved" 110 "Reserved" 109 "Reserved" 108 "Reserved" 107 "Reserved" 106 "Reserved" 105 "Reserved" 104 "Reserved" 103 "Reserved" 102 "Reserved" 101 "Reserved" 100 "Reserved" 99 "Reserved" 98 "Reserved" 97 "Reserved" 96 "Reserved" 95 "Reserved" 94 "Reserved" 93 "Reserved" 92 "Reserved" 91 "Reserved" 90 "Reserved" 89 "Reserved" 88 "Reserved" 87 "Reserved" 86 "Reserved" 85 "Reserved" 84 "Reserved" 83 "Reserved" 82 "Reserved" 81 "Reserved" 80 "Reserved" 79 "Reserved" 78 "Reserved" 77 "Reserved" 76 "Reserved" 75 "Reserved" 74 "Reserved" 73 "Reserved" 72 "Reserved" 71 "Reserved" 70 "Reserved" 69 "Reserved" 68 "Reserved" 67 "Reserved" 66 "Reserved" 65 "Reserved" 64 "Reserved" 63 "Reserved" 62 "Reserved" 61 "Reserved" 60 "Reserved" 59 "Reserved" 58 "Reserved" 57 "Reserved" 56 "Reserved" 55 "Reserved" 54 "Reserved" 53 "Reserved" 52 "Reserved" 51 "Reserved" 50 "Reserved" 49 "Reserved" 48 "Reserved" 47 "Reserved" 46 "Reserved" 45 "Reserved" 44 "Reserved" 43 "Reserved" 42 "Reserved" 41 "Reserved" 40 "Reserved" 39 "Reserved" 38 "Reserved" 37 "Reserved" 36 "Reserved" 35 "Reserved" 34 "Reserved" 33 "Reserved" 32 "Reserved" 31 "Reserved" 30 "Reserved" 29 "Reserved" 28 "Reserved" 27 "Reserved" 26 "Reserved" 25 "Reserved" 24 "Reserved" 23 "Reserved" 22 "Reserved" 21 "Reserved" 20 "Reserved" 19 "Reserved" 18 "Reserved" 17 "IGN ACC" 16 "Not used" 15 "Not used" 14 "Not used" 13 "Not used" 12 "Not used" 11 "Not used" 10 "Not used" 9 "Not used" 8 "Not used" 7 "Not used" 6 "Not used" 5 "Not used" 4 "Not used" 3 "Not used" 2 "Not used" 1 "Message wake up" 0 "Not used" ;
VAL_ 1085 FCP_NMSleepAck 1 "Active" 0 "Not active" ;
VAL_ 1085 FCP_NMSleepInd 1 "Active" 0 "Not active" ;
VAL_ 1085 FCP_NMLimpHome 1 "Active" 0 "Not active" ;
VAL_ 1085 FCP_NMRing 1 "Active" 0 "Not active" ;
VAL_ 1085 FCP_NMAlive 1 "Active" 0 "Not active" ;
VAL_ 1082 RCP_NMWakeupOrignin 255 "Reserved" 254 "Reserved" 253 "Reserved" 252 "Reserved" 251 "Reserved" 250 "Reserved" 249 "Reserved" 248 "Reserved" 247 "Reserved" 246 "Reserved" 245 "Reserved" 244 "Reserved" 243 "Reserved" 242 "Reserved" 241 "Reserved" 240 "Reserved" 239 "Reserved" 238 "Reserved" 237 "Reserved" 236 "Reserved" 235 "Reserved" 234 "Reserved" 233 "Reserved" 232 "Reserved" 231 "Reserved" 230 "Reserved" 229 "Reserved" 228 "Reserved" 227 "Reserved" 226 "Reserved" 225 "Reserved" 224 "Reserved" 223 "Reserved" 222 "Reserved" 221 "Reserved" 220 "Reserved" 219 "Reserved" 218 "Reserved" 217 "Reserved" 216 "Reserved" 215 "Reserved" 214 "Reserved" 213 "Reserved" 212 "Reserved" 211 "Reserved" 210 "Reserved" 209 "Reserved" 208 "Reserved" 207 "Reserved" 206 "Reserved" 205 "Reserved" 204 "Reserved" 203 "Reserved" 202 "Reserved" 201 "Reserved" 200 "Reserved" 199 "Reserved" 198 "Reserved" 197 "Reserved" 196 "Reserved" 195 "Reserved" 194 "Reserved" 193 "Reserved" 192 "Reserved" 191 "Reserved" 190 "Reserved" 189 "Reserved" 188 "Reserved" 187 "Reserved" 186 "Reserved" 185 "Reserved" 184 "Reserved" 183 "Reserved" 182 "Reserved" 181 "Reserved" 180 "Reserved" 179 "Reserved" 178 "Reserved" 177 "Reserved" 176 "Reserved" 175 "Reserved" 174 "Reserved" 173 "Reserved" 172 "Reserved" 171 "Reserved" 170 "Reserved" 169 "Reserved" 168 "Reserved" 167 "Reserved" 166 "Reserved" 165 "Reserved" 164 "Reserved" 163 "Reserved" 162 "Reserved" 161 "Reserved" 160 "Reserved" 159 "Reserved" 158 "Reserved" 157 "Reserved" 156 "Reserved" 155 "Reserved" 154 "Reserved" 153 "Reserved" 152 "Reserved" 151 "Reserved" 150 "Reserved" 149 "Reserved" 148 "Reserved" 147 "Reserved" 146 "Reserved" 145 "Reserved" 144 "Reserved" 143 "Reserved" 142 "Reserved" 141 "Reserved" 140 "Reserved" 139 "Reserved" 138 "Reserved" 137 "Reserved" 136 "Reserved" 135 "Reserved" 134 "Reserved" 133 "Reserved" 132 "Reserved" 131 "Reserved" 130 "Reserved" 129 "Reserved" 128 "Reserved" 127 "Reserved" 126 "Reserved" 125 "Reserved" 124 "Reserved" 123 "Reserved" 122 "Reserved" 121 "Reserved" 120 "Reserved" 119 "Reserved" 118 "Reserved" 117 "Reserved" 116 "Reserved" 115 "Reserved" 114 "Reserved" 113 "Reserved" 112 "Reserved" 111 "Reserved" 110 "Reserved" 109 "Reserved" 108 "Reserved" 107 "Reserved" 106 "Reserved" 105 "Reserved" 104 "Reserved" 103 "Reserved" 102 "Reserved" 101 "Reserved" 100 "Reserved" 99 "Reserved" 98 "Reserved" 97 "Reserved" 96 "Reserved" 95 "Reserved" 94 "Reserved" 93 "Reserved" 92 "Reserved" 91 "Reserved" 90 "Reserved" 89 "Reserved" 88 "Reserved" 87 "Reserved" 86 "Reserved" 85 "Reserved" 84 "Reserved" 83 "Reserved" 82 "Reserved" 81 "Reserved" 80 "Reserved" 79 "Reserved" 78 "Reserved" 77 "Reserved" 76 "Reserved" 75 "Reserved" 74 "Reserved" 73 "Reserved" 72 "Reserved" 71 "Reserved" 70 "Reserved" 69 "Reserved" 68 "Reserved" 67 "Reserved" 66 "Reserved" 65 "Reserved" 64 "Reserved" 63 "Reserved" 62 "Reserved" 61 "Reserved" 60 "Reserved" 59 "Reserved" 58 "Reserved" 57 "Reserved" 56 "Reserved" 55 "Reserved" 54 "Reserved" 53 "Reserved" 52 "Reserved" 51 "Reserved" 50 "Reserved" 49 "Reserved" 48 "Reserved" 47 "Reserved" 46 "Reserved" 45 "Reserved" 44 "Reserved" 43 "Reserved" 42 "Reserved" 41 "Reserved" 40 "Reserved" 39 "Reserved" 38 "Reserved" 37 "Reserved" 36 "Reserved" 35 "Reserved" 34 "Reserved" 33 "Reserved" 32 "Reserved" 31 "Reserved" 30 "Reserved" 29 "Reserved" 28 "Reserved" 27 "Reserved" 26 "Reserved" 25 "Reserved" 24 "Reserved" 23 "Reserved" 22 "Reserved" 21 "Reserved" 20 "Reserved" 19 "Reserved" 18 "Reserved" 17 "IGN ACC" 16 "Not used" 15 "Not used" 14 "Not used" 13 "Not used" 12 "Not used" 11 "Not used" 10 "Not used" 9 "Not used" 8 "Not used" 7 "Not used" 6 "Not used" 5 "Not used" 4 "Not used" 3 "Not used" 2 "Not used" 1 "Message wake up" 0 "Not used" ;
VAL_ 1082 RCP_NMSleepAck 1 "Active" 0 "Not active" ;
VAL_ 1082 RCP_NMSleepInd 1 "Active" 0 "Not active" ;
VAL_ 1082 RCP_NMLimpHome 1 "Active" 0 "Not active" ;
VAL_ 1082 RCP_NMRing 1 "Active" 0 "Not active" ;
VAL_ 1082 RCP_NMAlive 1 "Active" 0 "Not active" ;
VAL_ 1060 PLGM_NMWakeupOrigin 255 "Reserved" 254 "Reserved" 253 "Reserved" 252 "Reserved" 251 "Reserved" 250 "Reserved" 249 "Reserved" 248 "Reserved" 247 "Reserved" 246 "Reserved" 245 "Reserved" 244 "Reserved" 243 "Reserved" 242 "Reserved" 241 "Reserved" 240 "Reserved" 239 "Reserved" 238 "Reserved" 237 "Reserved" 236 "Reserved" 235 "Reserved" 234 "Reserved" 233 "Reserved" 232 "Reserved" 231 "Reserved" 230 "Reserved" 229 "Reserved" 228 "Reserved" 227 "Reserved" 226 "Reserved" 225 "Reserved" 224 "Reserved" 223 "Reserved" 222 "Reserved" 221 "Reserved" 220 "Reserved" 219 "Reserved" 218 "Reserved" 217 "Reserved" 216 "Reserved" 215 "Reserved" 214 "Reserved" 213 "Reserved" 212 "Reserved" 211 "Reserved" 210 "Reserved" 209 "Reserved" 208 "Reserved" 207 "Reserved" 206 "Reserved" 205 "Reserved" 204 "Reserved" 203 "Reserved" 202 "Reserved" 201 "Reserved" 200 "Reserved" 199 "Reserved" 198 "Reserved" 197 "Reserved" 196 "Reserved" 195 "Reserved" 194 "Reserved" 193 "Reserved" 192 "Reserved" 191 "Reserved" 190 "Reserved" 189 "Reserved" 188 "Reserved" 187 "Reserved" 186 "Reserved" 185 "Reserved" 184 "Reserved" 183 "Reserved" 182 "Reserved" 181 "Reserved" 180 "Reserved" 179 "Reserved" 178 "Reserved" 177 "Reserved" 176 "Reserved" 175 "Reserved" 174 "Reserved" 173 "Reserved" 172 "Reserved" 171 "Reserved" 170 "Reserved" 169 "Reserved" 168 "Reserved" 167 "Reserved" 166 "Reserved" 165 "Reserved" 164 "Reserved" 163 "Reserved" 162 "Reserved" 161 "Reserved" 160 "Reserved" 159 "Reserved" 158 "Reserved" 157 "Reserved" 156 "Reserved" 155 "Reserved" 154 "Reserved" 153 "Reserved" 152 "Reserved" 151 "Reserved" 150 "Reserved" 149 "Reserved" 148 "Reserved" 147 "Reserved" 146 "Reserved" 145 "Reserved" 144 "Reserved" 143 "Reserved" 142 "Reserved" 141 "Reserved" 140 "Reserved" 139 "Reserved" 138 "Reserved" 137 "Reserved" 136 "Reserved" 135 "Reserved" 134 "Reserved" 133 "Reserved" 132 "Reserved" 131 "Reserved" 130 "Reserved" 129 "Reserved" 128 "Reserved" 127 "Reserved" 126 "Reserved" 125 "Reserved" 124 "Reserved" 123 "Reserved" 122 "Reserved" 121 "Reserved" 120 "Reserved" 119 "Reserved" 118 "Reserved" 117 "Reserved" 116 "Reserved" 115 "Reserved" 114 "Reserved" 113 "Reserved" 112 "Reserved" 111 "Reserved" 110 "Reserved" 109 "Reserved" 108 "Reserved" 107 "Reserved" 106 "Reserved" 105 "Reserved" 104 "Reserved" 103 "Reserved" 102 "Reserved" 101 "Reserved" 100 "Reserved" 99 "Reserved" 98 "Reserved" 97 "Reserved" 96 "Reserved" 95 "Reserved" 94 "Reserved" 93 "Reserved" 92 "Reserved" 91 "Reserved" 90 "Reserved" 89 "Reserved" 88 "Reserved" 87 "Reserved" 86 "Reserved" 85 "Reserved" 84 "Reserved" 83 "Reserved" 82 "Reserved" 81 "Reserved" 80 "Reserved" 79 "Reserved" 78 "Reserved" 77 "Reserved" 76 "Reserved" 75 "Reserved" 74 "Reserved" 73 "Reserved" 72 "Reserved" 71 "Reserved" 70 "Reserved" 69 "Reserved" 68 "Reserved" 67 "Reserved" 66 "Reserved" 65 "Reserved" 64 "Reserved" 63 "Reserved" 62 "Reserved" 61 "Reserved" 60 "Reserved" 59 "Reserved" 58 "Reserved" 57 "Reserved" 56 "Reserved" 55 "Reserved" 54 "Reserved" 53 "Reserved" 52 "Reserved" 51 "Reserved" 50 "Reserved" 49 "Reserved" 48 "Reserved" 47 "Reserved" 46 "Reserved" 45 "Reserved" 44 "Reserved" 43 "Reserved" 42 "Reserved" 41 "Reserved" 40 "Reserved" 39 "Reserved" 38 "Reserved" 37 "Reserved" 36 "Reserved" 35 "Reserved" 34 "Reserved" 33 "Reserved" 32 "Reserved" 31 "Reserved" 30 "Reserved" 29 "Reserved" 28 "Reserved" 27 "Reserved" 26 "Reserved" 25 "Reserved" 24 "Reserved" 23 "Reserved" 22 "Reserved" 21 "Reserved" 20 "Reserved" 19 "Inside Gate Close SW" 18 "LatchDetentSW" 17 "LatchAjarSW" 16 "Not used" 15 "Not used" 14 "Not used" 13 "Not used" 12 "Not used" 11 "Not used" 10 "Not used" 9 "Not used" 8 "Not used" 7 "Not used" 6 "Not used" 5 "Not used" 4 "Not used" 3 "Not used" 2 "Not used" 1 "Message wake up" 0 "Not used" ;
VAL_ 1060 PLGM_NMSleepAck 1 "Active" 0 "Not active" ;
VAL_ 1060 PLGM_NMSleepInd 1 "Active" 0 "Not active" ;
VAL_ 1060 PLGM_NMLimpHome 1 "Active" 0 "Not active" ;
VAL_ 1060 PLGM_NMRing 1 "Active" 0 "Not active" ;
VAL_ 1060 PLGM_NMAlive 1 "Active" 0 "Not active" ;
VAL_ 773 PLGM_ModeSW 1 "Pressed" 0 " Not pressed" ;
VAL_ 773 PLGM_Doorst 7 "Reserved" 6 "Reserved" 5 " Hold" 4 " Closing" 3 " Opening" 2 " FullyClosed" 1 " FullyOpened" 0 " Status Unkown" ;
VAL_ 1116 TSCM_NMSleepAck 1 "Active" 0 "Not active" ;
VAL_ 1116 TSCM_NMSleepInd 1 "Active" 0 "Not active" ;
VAL_ 1116 TSCM_NMLimpHome 1 "Active" 0 "Not active" ;
VAL_ 1116 TSCM_NMRing 1 "Active" 0 "Not active" ;
VAL_ 1116 TSCM_NMAlive 1 "Active" 0 "Not active" ;
VAL_ 1076 MSM_NMWakeupOrignin 255 "Reserved" 254 "Reserved" 253 "Reserved" 252 "Reserved" 251 "Reserved" 250 "Reserved" 249 "Reserved" 248 "Reserved" 247 "Reserved" 246 "Reserved" 245 "Reserved" 244 "Reserved" 243 "Reserved" 242 "Reserved" 241 "Reserved" 240 "Reserved" 239 "Reserved" 238 "Reserved" 237 "Reserved" 236 "Reserved" 235 "Reserved" 234 "Reserved" 233 "Reserved" 232 "Reserved" 231 "Reserved" 230 "Reserved" 229 "Reserved" 228 "Reserved" 227 "Reserved" 226 "Reserved" 225 "Reserved" 224 "Reserved" 223 "Reserved" 222 "Reserved" 221 "Reserved" 220 "Reserved" 219 "Reserved" 218 "Reserved" 217 "Reserved" 216 "Reserved" 215 "Reserved" 214 "Reserved" 213 "Reserved" 212 "Reserved" 211 "Reserved" 210 "Reserved" 209 "Reserved" 208 "Reserved" 207 "Reserved" 206 "Reserved" 205 "Reserved" 204 "Reserved" 203 "Reserved" 202 "Reserved" 201 "Reserved" 200 "Reserved" 199 "Reserved" 198 "Reserved" 197 "Reserved" 196 "Reserved" 195 "Reserved" 194 "Reserved" 193 "Reserved" 192 "Reserved" 191 "Reserved" 190 "Reserved" 189 "Reserved" 188 "Reserved" 187 "Reserved" 186 "Reserved" 185 "Reserved" 184 "Reserved" 183 "Reserved" 182 "Reserved" 181 "Reserved" 180 "Reserved" 179 "Reserved" 178 "Reserved" 177 "Reserved" 176 "Reserved" 175 "Reserved" 174 "Reserved" 173 "Reserved" 172 "Reserved" 171 "Reserved" 170 "Reserved" 169 "Reserved" 168 "Reserved" 167 "Reserved" 166 "Reserved" 165 "Reserved" 164 "Reserved" 163 "Reserved" 162 "Reserved" 161 "Reserved" 160 "Reserved" 159 "Reserved" 158 "Reserved" 157 "Reserved" 156 "Reserved" 155 "Reserved" 154 "Reserved" 153 "Reserved" 152 "Reserved" 151 "Reserved" 150 "Reserved" 149 "Reserved" 148 "Reserved" 147 "Reserved" 146 "Reserved" 145 "Reserved" 144 "Reserved" 143 "Reserved" 142 "Reserved" 141 "Reserved" 140 "Reserved" 139 "Reserved" 138 "Reserved" 137 "Reserved" 136 "Reserved" 135 "Reserved" 134 "Reserved" 133 "Reserved" 132 "Reserved" 131 "Reserved" 130 "Reserved" 129 "Reserved" 128 "Reserved" 127 "Reserved" 126 "Reserved" 125 "Reserved" 124 "Reserved" 123 "Reserved" 122 "Reserved" 121 "Reserved" 120 "Reserved" 119 "Reserved" 118 "Reserved" 117 "Reserved" 116 "Reserved" 115 "Reserved" 114 "Reserved" 113 "Reserved" 112 "Reserved" 111 "Reserved" 110 "Reserved" 109 "Reserved" 108 "Reserved" 107 "Reserved" 106 "Reserved" 105 "Reserved" 104 "Reserved" 103 "Reserved" 102 "Reserved" 101 "Reserved" 100 "Reserved" 99 "Reserved" 98 "Reserved" 97 "Reserved" 96 "Reserved" 95 "Reserved" 94 "Reserved" 93 "Reserved" 92 "Reserved" 91 "Reserved" 90 "Reserved" 89 "Reserved" 88 "Reserved" 87 "Reserved" 86 "Reserved" 85 "Reserved" 84 "Seat sdjust switch" 83 "Rear view mirror adjust switch" 82 "Not used" 81 "Not used" 80 "Not used" 79 "Not used" 78 "Not used" 77 "Not used" 76 "Not used" 75 "Not used" 74 "Not used" 73 "Not used" 72 "Not used" 71 "Not used" 70 "Not used" 69 "Not used" 68 "Not used" 67 "Not used" 66 "Not used" 65 "Not used" 64 "Not used" 63 "Not used" 62 "Not used" 61 "Not used" 60 "Not used" 59 "Not used" 58 "Not used" 57 "Not used" 56 "Not used" 55 "Not used" 54 "Not used" 53 "Not used" 52 "Not used" 51 "Not used" 50 "Not used" 49 "Not used" 48 "Not used" 47 "Not used" 46 "Not used" 45 "Not used" 44 "Not used" 43 "Not used" 42 "Not used" 41 "Not used" 40 "Not used" 39 "Not used" 38 "Not used" 37 "Not used" 36 "Not used" 35 "Not used" 34 "Not used" 33 "Not used" 32 "Not used" 31 "Not used" 30 "Not used" 29 "Not used" 28 "Not used" 27 "Not used" 26 "Not used" 25 "Not used" 24 "Not used" 23 "Not used" 22 "Not used" 21 "Not used" 20 "Not used" 19 "Not used" 18 "IGN ON" 17 "Not used" 16 "Not used" 15 "Not used" 14 "Not used" 13 "Not used" 12 "Not used" 11 "Not used" 10 "Not used" 9 "Not used" 8 "Not used" 7 "Not used" 6 "Not used" 5 "Not used" 4 "Not used" 3 "Not used" 2 "Not used" 1 "Message wake up" ;
VAL_ 1076 MSM_NMSleepAck 1 "Active" 0 "Not active" ;
VAL_ 1076 MSM_NMSleepInd 1 "Active" 0 "Not active" ;
VAL_ 1076 MSM_NMLimpHome 1 "Active" 0 "Not active" ;
VAL_ 1076 MSM_NMRing 1 "Active" 0 "Not active" ;
VAL_ 1076 MSM_NMAlive 1 "Active" 0 "Not active" ;
VAL_ 833 MSM_SeatNapModeSt 3 "Not used" 2 "Snap Mode" 1 "Snap Setting Mode" 0 "Not in Snapmode" ;
VAL_ 833 MSM_SeatPosSaveReq 1 " Active pop-up window" 0 "No command" ;
VAL_ 833 MSM_VoiceCtrlResp 15 "not used" 14 "not used" 13 "Negative" 12 "Stop" 11 "Title down" 10 "Title rise" 9 "back backward" 8 "back forward" 7 "Cushion down" 6 "Cushion rise" 5 "Slide backward" 4 "Slide forward" 3 "Level 3" 2 "Level 2" 1 "Level 1" 0 "No response" ;
VAL_ 833 MSM_SeatNapModePositionSt 1 "Stored" 0 "No stored" ;
VAL_ 833 MSM_WelcomeFuncCfgSt 1 "Active" 0 "Not active" ;
VAL_ 1100 AMP_NMWakeupOrigin 255 "Reserved" 254 "Reserved" 253 "Reserved" 252 "Reserved" 251 "Reserved" 250 "Reserved" 249 "Reserved" 248 "Reserved" 247 "Reserved" 246 "Reserved" 245 "Reserved" 244 "Reserved" 243 "Reserved" 242 "Reserved" 241 "Reserved" 240 "Reserved" 239 "Reserved" 238 "Reserved" 237 "Reserved" 236 "Reserved" 235 "Reserved" 234 "Reserved" 233 "Reserved" 232 "Reserved" 231 "Reserved" 230 "Reserved" 229 "Reserved" 228 "Reserved" 227 "Reserved" 226 "Reserved" 225 "Reserved" 224 "Reserved" 223 "Reserved" 222 "Reserved" 221 "Reserved" 220 "Reserved" 219 "Reserved" 218 "Reserved" 217 "Reserved" 216 "Reserved" 215 "Reserved" 214 "Reserved" 213 "Reserved" 212 "Reserved" 211 "Reserved" 210 "Reserved" 209 "Reserved" 208 "Reserved" 207 "Reserved" 206 "Reserved" 205 "Reserved" 204 "Reserved" 203 "Reserved" 202 "Reserved" 201 "Reserved" 200 "Reserved" 199 "Reserved" 198 "Reserved" 197 "Reserved" 196 "Reserved" 195 "Reserved" 194 "Reserved" 193 "Reserved" 192 "Reserved" 191 "Reserved" 190 "Reserved" 189 "Reserved" 188 "Reserved" 187 "Reserved" 186 "Reserved" 185 "Reserved" 184 "Reserved" 183 "Reserved" 182 "Reserved" 181 "Reserved" 180 "Reserved" 179 "Reserved" 178 "Reserved" 177 "Reserved" 176 "Reserved" 175 "Reserved" 174 "Reserved" 173 "Reserved" 172 "Reserved" 171 "Reserved" 170 "Reserved" 169 "Reserved" 168 "Reserved" 167 "Reserved" 166 "Reserved" 165 "Reserved" 164 "Reserved" 163 "Reserved" 162 "Reserved" 161 "Reserved" 160 "Reserved" 159 "Reserved" 158 "Reserved" 157 "Reserved" 156 "Reserved" 155 "Reserved" 154 "Reserved" 153 "Reserved" 152 "Reserved" 151 "Reserved" 150 "Reserved" 149 "Reserved" 148 "Reserved" 147 "Reserved" 146 "Reserved" 145 "Reserved" 144 "Reserved" 143 "Reserved" 142 "Reserved" 141 "Reserved" 140 "Reserved" 139 "Reserved" 138 "Reserved" 137 "Reserved" 136 "Reserved" 135 "Reserved" 134 "Reserved" 133 "Reserved" 132 "Reserved" 131 "Reserved" 130 "Reserved" 129 "Reserved" 128 "Reserved" 127 "Reserved" 126 "Reserved" 125 "Reserved" 124 "Reserved" 123 "Reserved" 122 "Reserved" 121 "Reserved" 120 "Reserved" 119 "Reserved" 118 "Reserved" 117 "Reserved" 116 "Reserved" 115 "Reserved" 114 "Reserved" 113 "Reserved" 112 "Reserved" 111 "Reserved" 110 "Reserved" 109 "Reserved" 108 "Reserved" 107 "Reserved" 106 "Reserved" 105 "Reserved" 104 "Reserved" 103 "Reserved" 102 "Reserved" 101 "Reserved" 100 "Reserved" 99 "Reserved" 98 "Reserved" 97 "Reserved" 96 "Reserved" 95 "Reserved" 94 "Reserved" 93 "Reserved" 92 "Reserved" 91 "Reserved" 90 "Reserved" 89 "Reserved" 88 "Reserved" 87 "Reserved" 86 "Reserved" 85 "Reserved" 84 "Reserved" 83 "Reserved" 82 "Reserved" 81 "Reserved" 80 "Reserved" 79 "Reserved" 78 "Reserved" 77 "Reserved" 76 "Reserved" 75 "Reserved" 74 "Reserved" 73 "Reserved" 72 "Reserved" 71 "Reserved" 70 "Reserved" 69 "Reserved" 68 "Reserved" 67 "Reserved" 66 "Reserved" 65 "Reserved" 64 "Reserved" 63 "Reserved" 62 "Reserved" 61 "Reserved" 60 "Reserved" 59 "Reserved" 58 "Reserved" 57 "Reserved" 56 "Reserved" 55 "Reserved" 54 "Reserved" 53 "Reserved" 52 "Reserved" 51 "Reserved" 50 "Reserved" 49 "Reserved" 48 "Reserved" 47 "Reserved" 46 "Reserved" 45 "Reserved" 44 "Reserved" 43 "Reserved" 42 "Reserved" 41 "Reserved" 40 "Reserved" 39 "Reserved" 38 "Reserved" 37 "Reserved" 36 "Reserved" 35 "Reserved" 34 "Reserved" 33 "Reserved" 32 "Reserved" 31 "Reserved" 30 "Reserved" 29 "Reserved" 28 "Reserved" 27 "Reserved" 26 "Reserved" 25 "Reserved" 24 "Reserved" 23 "Reserved" 22 "Reserved" 21 "Reserved" 20 "Reserved" 19 "Reserved" 18 "Reserved" 17 "IGN ACC" 16 "Not used" 15 "Not used" 14 "Not used" 13 "Not used" 12 "Not used" 11 "Not used" 10 "Not used" 9 "Not used" 8 "Not used" 7 "Not used" 6 "Not used" 5 "Not used" 4 "Not used" 3 "Not used" 2 "Not used" 1 "Message wake up" ;
VAL_ 1100 AMP_NMSleepAck 1 "Active" 0 "Not active" ;
VAL_ 1100 AMP_NMSleepInd 1 "Active" 0 "Not active" ;
VAL_ 1100 AMP_NMLimpHome 1 "Active" 0 "Not active" ;
VAL_ 1100 AMP_NMRing 1 "Active" 0 "Not active" ;
VAL_ 1100 AMP_NMAlive 1 "Active" 0 "Not active" ;
VAL_ 155 AMP_A2BSet 3 "No Command" 2 "A2BReady" 1 "A2BNotReady" 0 "none" ;
VAL_ 155 AMP_ANC_SwitchStatus 3 "No Command" 2 "Reserved" 1 "on" 0 "off" ;
VAL_ 155 AMP_ICCSts 7 "No Command" 6 "Reserved" 5 "Reserved" 4 "Reserved" 3 "HI" 2 "MID" 1 "LOW" 0 "OFF" ;
VAL_ 155 AMP_ESESts 7 "No Command" 6 "Reserved" 5 "Reserved" 4 "Reserved" 3 "HI" 2 "MID" 1 "LOW" 0 "OFF" ;
VAL_ 155 AMP_SoundmodeSet 3 "No Command" 2 "Reserved" 1 "adigo" 0 "YAMAHA" ;
VAL_ 155 AMP_Headrest_Mode 3 "No Command" 2 "only head" 1 "All Speak" 0 "off" ;
VAL_ 155 AMP_TelSourceSts 7 "No Command" 6 "Reserved" 5 "Reserved" 4 "Reserved" 3 "Phone Ring（BT Phone/Carlife Phone/Carlife Phone）" 2 "BT Phone/Carlife Phone/Carlife Phone/Hicar Phone" 1 "E-Call/B-Call" 0 "None" ;
VAL_ 187 AMP_NaviVolSetSt 63 " No Command" 62 " Reserved" 61 " Reserved" 60 " Reserved" 59 " Reserved" 58 " Reserved" 57 " Reserved" 56 " Reserved" 55 " Reserved" 54 " Reserved" 53 " Reserved" 52 " Reserved" 51 " Reserved" 50 " Reserved" 49 " Reserved" 48 " Reserved" 47 " Reserved" 46 " Reserved" 45 " Reserved" 44 " Reserved" 43 " Reserved" 42 " Reserved" 41 " Reserved" 40 " Reserved" 39 " Reserved" 38 " Reserved" 37 " Reserved" 36 " Reserved" 35 " Reserved" 34 " Reserved" 33 " Reserved" 32 " Reserved" 31 " Reserved" 30 " Reserved" 29 " Reserved" 28 " Reserved" 27 " Reserved" 26 " Reserved" 25 " Reserved" 24 " Reserved" 23 " Reserved" 22 " Reserved" 21 " Reserved" 20 " Reserved" 19 " Reserved" 18 " Reserved" 17 " Reserved" 16 " Reserved" 15 " Reserved" 14 " Reserved" 13 " Reserved" 12 " Reserved" 11 " Reserved" 10 " Navi volume step 0-10" 9 " Navi volume step 0-10" 8 " Navi volume step 0-10" 7 " Navi volume step 0-10" 6 " Navi volume step 0-10" 5 " Navi volume step 0-10" 4 " Navi volume step 0-10" 3 " Navi volume step 0-10" 2 " Navi volume step 0-10" 1 " Navi volume step 0-10" 0 " Navi volume step 0-10" ;
VAL_ 187 AMP_MainVolSetSt 63 " No Command" 62 " Reserved" 61 " Reserved" 60 " Reserved" 59 " Reserved" 58 " Reserved" 57 " Reserved" 56 " Reserved" 55 " Reserved" 54 " Reserved" 53 " Reserved" 52 " Reserved" 51 " Reserved" 50 " Reserved" 49 " Reserved" 48 " Reserved" 47 " Reserved" 46 " Reserved" 45 " Reserved" 44 " Reserved" 43 " Reserved" 42 " Reserved" 41 " Reserved" 40 " Reserved" 39 " Main volume step 0-39" 38 " Main volume step 0-39" 37 " Main volume step 0-39" 36 " Main volume step 0-39" 35 " Main volume step 0-39" 34 " Main volume step 0-39" 33 " Main volume step 0-39" 32 " Main volume step 0-39" 31 " Main volume step 0-39" 30 " Main volume step 0-39" 29 " Main volume step 0-39" 28 " Main volume step 0-39" 27 " Main volume step 0-39" 26 " Main volume step 0-39" 25 " Main volume step 0-39" 24 " Main volume step 0-39" 23 " Main volume step 0-39" 22 " Main volume step 0-39" 21 " Main volume step 0-39" 20 " Main volume step 0-39" 19 " Main volume step 0-39" 18 " Main volume step 0-39" 17 " Main volume step 0-39" 16 " Main volume step 0-39" 15 " Main volume step 0-39" 14 " Main volume step 0-39" 13 " Main volume step 0-39" 12 " Main volume step 0-39" 11 " Main volume step 0-39" 10 " Main volume step 0-39" 9 " Main volume step 0-39" 8 " Main volume step 0-39" 7 " Main volume step 0-39" 6 " Main volume step 0-39" 5 " Main volume step 0-39" 4 " Main volume step 0-39" 3 " Main volume step 0-39" 2 " Main volume step 0-39" 1 " Main volume step 0-39" 0 " Main volume step 0-39" ;
VAL_ 187 AMP_TelVolSetSts 63 " No Command" 62 " Reserved" 61 " Reserved" 60 " Reserved" 59 " Reserved" 58 " Reserved" 57 " Reserved" 56 " Reserved" 55 " Reserved" 54 " Reserved" 53 " Reserved" 52 " Reserved" 51 " Reserved" 50 " Reserved" 49 " Reserved" 48 " Reserved" 47 " Reserved" 46 " Reserved" 45 " Reserved" 44 " Reserved" 43 " Reserved" 42 " Reserved" 41 " Reserved" 40 " Reserved" 39 " Reserved" 38 " Reserved" 37 " Reserved" 36 " Reserved" 35 " Reserved" 34 " Reserved" 33 " Reserved" 32 " Reserved" 31 " Reserved" 30 " Reserved" 29 " Reserved" 28 " Reserved" 27 " Reserved" 26 " Reserved" 25 " Reserved" 24 " Reserved" 23 " Reserved" 22 " Reserved" 21 " Reserved" 20 " Reserved" 19 " Reserved" 18 " Reserved" 17 " Reserved" 16 " Reserved" 15 " Reserved" 14 " Reserved" 13 " Reserved" 12 " Reserved" 11 " Reserved" 10 " HFM volume step 0-10" 9 " HFM volume step 0-10" 8 " HFM volume step 0-10" 7 " HFM volume step 0-10" 6 " HFM volume step 0-10" 5 " HFM volume step 0-10" 4 " HFM volume step 0-10" 3 " HFM volume step 0-10" 2 " HFM volume step 0-10" 1 " HFM volume step 0-10" 0 " HFM volume step 0-10" ;
VAL_ 187 AMP_EQModeSts 3 "No Command" 2 "rear seats" 1 "All seats" 0 "Front seats" ;
VAL_ 187 AMP_VRVolSetSts 63 " No Command" 62 " Reserved" 61 " Reserved" 60 " Reserved" 59 " Reserved" 58 " Reserved" 57 " Reserved" 56 " Reserved" 55 " Reserved" 54 " Reserved" 53 " Reserved" 52 " Reserved" 51 " Reserved" 50 " Reserved" 49 " Reserved" 48 " Reserved" 47 " Reserved" 46 " Reserved" 45 " Reserved" 44 " Reserved" 43 " Reserved" 42 " Reserved" 41 " Reserved" 40 " Reserved" 39 " Reserved" 38 " Reserved" 37 " Reserved" 36 " Reserved" 35 " Reserved" 34 " Reserved" 33 " Reserved" 32 " Reserved" 31 " Reserved" 30 " Reserved" 29 " Reserved" 28 " Reserved" 27 " Reserved" 26 " Reserved" 25 " Reserved" 24 " Reserved" 23 " Reserved" 22 " Reserved" 21 " Reserved" 20 " Reserved" 19 " Reserved" 18 " Reserved" 17 " Reserved" 16 " Reserved" 15 " Reserved" 14 " Reserved" 13 " Reserved" 12 " Reserved" 11 " Reserved" 10 "VR_ TTS volume step 0-10" 9 "VR_ TTS volume step 0-10" 8 "VR_ TTS volume step 0-10" 7 "VR_ TTS volume step 0-10" 6 "VR_ TTS volume step 0-10" 5 "VR_ TTS volume step 0-10" 4 "VR_ TTS volume step 0-10" 3 "VR_ TTS volume step 0-10" 2 "VR_ TTS volume step 0-10" 1 "VR_ TTS volume step 0-10" 0 "VR_ TTS volume step 0-10" ;
VAL_ 187 AMP_VolValue 255 "INo Command" 254 "Amplifier internal voltage value" 253 "Amplifier internal voltage value" 252 "Amplifier internal voltage value" 251 "Amplifier internal voltage value" 250 "Amplifier internal voltage value" 249 "Amplifier internal voltage value" 248 "Amplifier internal voltage value" 247 "Amplifier internal voltage value" 246 "Amplifier internal voltage value" 245 "Amplifier internal voltage value" 244 "Amplifier internal voltage value" 243 "Amplifier internal voltage value" 242 "Amplifier internal voltage value" 241 "Amplifier internal voltage value" 240 "Amplifier internal voltage value" 239 "Amplifier internal voltage value" 238 "Amplifier internal voltage value" 237 "Amplifier internal voltage value" 236 "Amplifier internal voltage value" 235 "Amplifier internal voltage value" 234 "Amplifier internal voltage value" 233 "Amplifier internal voltage value" 232 "Amplifier internal voltage value" 231 "Amplifier internal voltage value" 230 "Amplifier internal voltage value" 229 "Amplifier internal voltage value" 228 "Amplifier internal voltage value" 227 "Amplifier internal voltage value" 226 "Amplifier internal voltage value" 225 "Amplifier internal voltage value" 224 "Amplifier internal voltage value" 223 "Amplifier internal voltage value" 222 "Amplifier internal voltage value" 221 "Amplifier internal voltage value" 220 "Amplifier internal voltage value" 219 "Amplifier internal voltage value" 218 "Amplifier internal voltage value" 217 "Amplifier internal voltage value" 216 "Amplifier internal voltage value" 215 "Amplifier internal voltage value" 214 "Amplifier internal voltage value" 213 "Amplifier internal voltage value" 212 "Amplifier internal voltage value" 211 "Amplifier internal voltage value" 210 "Amplifier internal voltage value" 209 "Amplifier internal voltage value" 208 "Amplifier internal voltage value" 207 "Amplifier internal voltage value" 206 "Amplifier internal voltage value" 205 "Amplifier internal voltage value" 204 "Amplifier internal voltage value" 203 "Amplifier internal voltage value" 202 "Amplifier internal voltage value" 201 "Amplifier internal voltage value" 200 "Amplifier internal voltage value" 199 "Amplifier internal voltage value" 198 "Amplifier internal voltage value" 197 "Amplifier internal voltage value" 196 "Amplifier internal voltage value" 195 "Amplifier internal voltage value" 194 "Amplifier internal voltage value" 193 "Amplifier internal voltage value" 192 "Amplifier internal voltage value" 191 "Amplifier internal voltage value" 190 "Amplifier internal voltage value" 189 "Amplifier internal voltage value" 188 "Amplifier internal voltage value" 187 "Amplifier internal voltage value" 186 "Amplifier internal voltage value" 185 "Amplifier internal voltage value" 184 "Amplifier internal voltage value" 183 "Amplifier internal voltage value" 182 "Amplifier internal voltage value" 181 "Amplifier internal voltage value" 180 "Amplifier internal voltage value" 179 "Amplifier internal voltage value" 178 "Amplifier internal voltage value" 177 "Amplifier internal voltage value" 176 "Amplifier internal voltage value" 175 "Amplifier internal voltage value" 174 "Amplifier internal voltage value" 173 "Amplifier internal voltage value" 172 "Amplifier internal voltage value" 171 "Amplifier internal voltage value" 170 "Amplifier internal voltage value" 169 "Amplifier internal voltage value" 168 "Amplifier internal voltage value" 167 "Amplifier internal voltage value" 166 "Amplifier internal voltage value" 165 "Amplifier internal voltage value" 164 "Amplifier internal voltage value" 163 "Amplifier internal voltage value" 162 "Amplifier internal voltage value" 161 "Amplifier internal voltage value" 160 "Amplifier internal voltage value" 159 "Amplifier internal voltage value" 158 "Amplifier internal voltage value" 157 "Amplifier internal voltage value" 156 "Amplifier internal voltage value" 155 "Amplifier internal voltage value" 154 "Amplifier internal voltage value" 153 "Amplifier internal voltage value" 152 "Amplifier internal voltage value" 151 "Amplifier internal voltage value" 150 "Amplifier internal voltage value" 149 "Amplifier internal voltage value" 148 "Amplifier internal voltage value" 147 "Amplifier internal voltage value" 146 "Amplifier internal voltage value" 145 "Amplifier internal voltage value" 144 "Amplifier internal voltage value" 143 "Amplifier internal voltage value" 142 "Amplifier internal voltage value" 141 "Amplifier internal voltage value" 140 "Amplifier internal voltage value" 139 "Amplifier internal voltage value" 138 "Amplifier internal voltage value" 137 "Amplifier internal voltage value" 136 "Amplifier internal voltage value" 135 "Amplifier internal voltage value" 134 "Amplifier internal voltage value" 133 "Amplifier internal voltage value" 132 "Amplifier internal voltage value" 131 "Amplifier internal voltage value" 130 "Amplifier internal voltage value" 129 "Amplifier internal voltage value" 128 "Amplifier internal voltage value" 127 "Amplifier internal voltage value" 126 "Amplifier internal voltage value" 125 "Amplifier internal voltage value" 124 "Amplifier internal voltage value" 123 "Amplifier internal voltage value" 122 "Amplifier internal voltage value" 121 "Amplifier internal voltage value" 120 "Amplifier internal voltage value" 119 "Amplifier internal voltage value" 118 "Amplifier internal voltage value" 117 "Amplifier internal voltage value" 116 "Amplifier internal voltage value" 115 "Amplifier internal voltage value" 114 "Amplifier internal voltage value" 113 "Amplifier internal voltage value" 112 "Amplifier internal voltage value" 111 "Amplifier internal voltage value" 110 "Amplifier internal voltage value" 109 "Amplifier internal voltage value" 108 "Amplifier internal voltage value" 107 "Amplifier internal voltage value" 106 "Amplifier internal voltage value" 105 "Amplifier internal voltage value" 104 "Amplifier internal voltage value" 103 "Amplifier internal voltage value" 102 "Amplifier internal voltage value" 101 "Amplifier internal voltage value" 100 "Amplifier internal voltage value" 99 "Amplifier internal voltage value" 98 "Amplifier internal voltage value" 97 "Amplifier internal voltage value" 96 "Amplifier internal voltage value" 95 "Amplifier internal voltage value" 94 "Amplifier internal voltage value" 93 "Amplifier internal voltage value" 92 "Amplifier internal voltage value" 91 "Amplifier internal voltage value" 90 "Amplifier internal voltage value" 89 "Amplifier internal voltage value" 88 "Amplifier internal voltage value" 87 "Amplifier internal voltage value" 86 "Amplifier internal voltage value" 85 "Amplifier internal voltage value" 84 "Amplifier internal voltage value" 83 "Amplifier internal voltage value" 82 "Amplifier internal voltage value" 81 "Amplifier internal voltage value" 80 "Amplifier internal voltage value" 79 "Amplifier internal voltage value" 78 "Amplifier internal voltage value" 77 "Amplifier internal voltage value" 76 "Amplifier internal voltage value" 75 "Amplifier internal voltage value" 74 "Amplifier internal voltage value" 73 "Amplifier internal voltage value" 72 "Amplifier internal voltage value" 71 "Amplifier internal voltage value" 70 "Amplifier internal voltage value" 69 "Amplifier internal voltage value" 68 "Amplifier internal voltage value" 67 "Amplifier internal voltage value" 66 "Amplifier internal voltage value" 65 "Amplifier internal voltage value" 64 "Amplifier internal voltage value" 63 "Amplifier internal voltage value" 62 "Amplifier internal voltage value" 61 "Amplifier internal voltage value" 60 "Amplifier internal voltage value" 59 "Amplifier internal voltage value" 58 "Amplifier internal voltage value" 57 "Amplifier internal voltage value" 56 "Amplifier internal voltage value" 55 "Amplifier internal voltage value" 54 "Amplifier internal voltage value" 53 "Amplifier internal voltage value" 52 "Amplifier internal voltage value" 51 "Amplifier internal voltage value" 50 "Amplifier internal voltage value" 49 "Amplifier internal voltage value" 48 "Amplifier internal voltage value" 47 "Amplifier internal voltage value" 46 "Amplifier internal voltage value" 45 "Amplifier internal voltage value" 44 "Amplifier internal voltage value" 43 "Amplifier internal voltage value" 42 "Amplifier internal voltage value" 41 "Amplifier internal voltage value" 40 "Amplifier internal voltage value" 39 "Amplifier internal voltage value" 38 "Amplifier internal voltage value" 37 "Amplifier internal voltage value" 36 "Amplifier internal voltage value" 35 "Amplifier internal voltage value" 34 "Amplifier internal voltage value" 33 "Amplifier internal voltage value" 32 "Amplifier internal voltage value" 31 "Amplifier internal voltage value" 30 "Amplifier internal voltage value" 29 "Amplifier internal voltage value" 28 "Amplifier internal voltage value" 27 "Amplifier internal voltage value" 26 "Amplifier internal voltage value" 25 "Amplifier internal voltage value" 24 "Amplifier internal voltage value" 23 "Amplifier internal voltage value" 22 "Amplifier internal voltage value" 21 "Amplifier internal voltage value" 20 "Amplifier internal voltage value" 19 "Amplifier internal voltage value" 18 "Amplifier internal voltage value" 17 "Amplifier internal voltage value" 16 "Amplifier internal voltage value" 15 "Amplifier internal voltage value" 14 "Amplifier internal voltage value" 13 "Amplifier internal voltage value" 12 "Amplifier internal voltage value" 11 "Amplifier internal voltage value" 10 "Amplifier internal voltage value" 9 "Amplifier internal voltage value" 8 "Amplifier internal voltage value" 7 "Amplifier internal voltage value" 6 "Amplifier internal voltage value" 5 "Amplifier internal voltage value" 4 "Amplifier internal voltage value" 3 "Amplifier internal voltage value" 2 "Amplifier internal voltage value" 1 "Amplifier internal voltage value" 0 "Amplifier internal voltage value" ;
VAL_ 187 AMP_TempValue 255 "No Command" 254 "Amplifier internal temperature value （Offset -50）" 253 "Amplifier internal temperature value （Offset -50）" 252 "Amplifier internal temperature value （Offset -50）" 251 "Amplifier internal temperature value （Offset -50）" 250 "Amplifier internal temperature value （Offset -50）" 249 "Amplifier internal temperature value （Offset -50）" 248 "Amplifier internal temperature value （Offset -50）" 247 "Amplifier internal temperature value （Offset -50）" 246 "Amplifier internal temperature value （Offset -50）" 245 "Amplifier internal temperature value （Offset -50）" 244 "Amplifier internal temperature value （Offset -50）" 243 "Amplifier internal temperature value （Offset -50）" 242 "Amplifier internal temperature value （Offset -50）" 241 "Amplifier internal temperature value （Offset -50）" 240 "Amplifier internal temperature value （Offset -50）" 239 "Amplifier internal temperature value （Offset -50）" 238 "Amplifier internal temperature value （Offset -50）" 237 "Amplifier internal temperature value （Offset -50）" 236 "Amplifier internal temperature value （Offset -50）" 235 "Amplifier internal temperature value （Offset -50）" 234 "Amplifier internal temperature value （Offset -50）" 233 "Amplifier internal temperature value （Offset -50）" 232 "Amplifier internal temperature value （Offset -50）" 231 "Amplifier internal temperature value （Offset -50）" 230 "Amplifier internal temperature value （Offset -50）" 229 "Amplifier internal temperature value （Offset -50）" 228 "Amplifier internal temperature value （Offset -50）" 227 "Amplifier internal temperature value （Offset -50）" 226 "Amplifier internal temperature value （Offset -50）" 225 "Amplifier internal temperature value （Offset -50）" 224 "Amplifier internal temperature value （Offset -50）" 223 "Amplifier internal temperature value （Offset -50）" 222 "Amplifier internal temperature value （Offset -50）" 221 "Amplifier internal temperature value （Offset -50）" 220 "Amplifier internal temperature value （Offset -50）" 219 "Amplifier internal temperature value （Offset -50）" 218 "Amplifier internal temperature value （Offset -50）" 217 "Amplifier internal temperature value （Offset -50）" 216 "Amplifier internal temperature value （Offset -50）" 215 "Amplifier internal temperature value （Offset -50）" 214 "Amplifier internal temperature value （Offset -50）" 213 "Amplifier internal temperature value （Offset -50）" 212 "Amplifier internal temperature value （Offset -50）" 211 "Amplifier internal temperature value （Offset -50）" 210 "Amplifier internal temperature value （Offset -50）" 209 "Amplifier internal temperature value （Offset -50）" 208 "Amplifier internal temperature value （Offset -50）" 207 "Amplifier internal temperature value （Offset -50）" 206 "Amplifier internal temperature value （Offset -50）" 205 "Amplifier internal temperature value （Offset -50）" 204 "Amplifier internal temperature value （Offset -50）" 203 "Amplifier internal temperature value （Offset -50）" 202 "Amplifier internal temperature value （Offset -50）" 201 "Amplifier internal temperature value （Offset -50）" 200 "Amplifier internal temperature value （Offset -50）" 199 "Amplifier internal temperature value （Offset -50）" 198 "Amplifier internal temperature value （Offset -50）" 197 "Amplifier internal temperature value （Offset -50）" 196 "Amplifier internal temperature value （Offset -50）" 195 "Amplifier internal temperature value （Offset -50）" 194 "Amplifier internal temperature value （Offset -50）" 193 "Amplifier internal temperature value （Offset -50）" 192 "Amplifier internal temperature value （Offset -50）" 191 "Amplifier internal temperature value （Offset -50）" 190 "Amplifier internal temperature value （Offset -50）" 189 "Amplifier internal temperature value （Offset -50）" 188 "Amplifier internal temperature value （Offset -50）" 187 "Amplifier internal temperature value （Offset -50）" 186 "Amplifier internal temperature value （Offset -50）" 185 "Amplifier internal temperature value （Offset -50）" 184 "Amplifier internal temperature value （Offset -50）" 183 "Amplifier internal temperature value （Offset -50）" 182 "Amplifier internal temperature value （Offset -50）" 181 "Amplifier internal temperature value （Offset -50）" 180 "Amplifier internal temperature value （Offset -50）" 179 "Amplifier internal temperature value （Offset -50）" 178 "Amplifier internal temperature value （Offset -50）" 177 "Amplifier internal temperature value （Offset -50）" 176 "Amplifier internal temperature value （Offset -50）" 175 "Amplifier internal temperature value （Offset -50）" 174 "Amplifier internal temperature value （Offset -50）" 173 "Amplifier internal temperature value （Offset -50）" 172 "Amplifier internal temperature value （Offset -50）" 171 "Amplifier internal temperature value （Offset -50）" 170 "Amplifier internal temperature value （Offset -50）" 169 "Amplifier internal temperature value （Offset -50）" 168 "Amplifier internal temperature value （Offset -50）" 167 "Amplifier internal temperature value （Offset -50）" 166 "Amplifier internal temperature value （Offset -50）" 165 "Amplifier internal temperature value （Offset -50）" 164 "Amplifier internal temperature value （Offset -50）" 163 "Amplifier internal temperature value （Offset -50）" 162 "Amplifier internal temperature value （Offset -50）" 161 "Amplifier internal temperature value （Offset -50）" 160 "Amplifier internal temperature value （Offset -50）" 159 "Amplifier internal temperature value （Offset -50）" 158 "Amplifier internal temperature value （Offset -50）" 157 "Amplifier internal temperature value （Offset -50）" 156 "Amplifier internal temperature value （Offset -50）" 155 "Amplifier internal temperature value （Offset -50）" 154 "Amplifier internal temperature value （Offset -50）" 153 "Amplifier internal temperature value （Offset -50）" 152 "Amplifier internal temperature value （Offset -50）" 151 "Amplifier internal temperature value （Offset -50）" 150 "Amplifier internal temperature value （Offset -50）" 149 "Amplifier internal temperature value （Offset -50）" 148 "Amplifier internal temperature value （Offset -50）" 147 "Amplifier internal temperature value （Offset -50）" 146 "Amplifier internal temperature value （Offset -50）" 145 "Amplifier internal temperature value （Offset -50）" 144 "Amplifier internal temperature value （Offset -50）" 143 "Amplifier internal temperature value （Offset -50）" 142 "Amplifier internal temperature value （Offset -50）" 141 "Amplifier internal temperature value （Offset -50）" 140 "Amplifier internal temperature value （Offset -50）" 139 "Amplifier internal temperature value （Offset -50）" 138 "Amplifier internal temperature value （Offset -50）" 137 "Amplifier internal temperature value （Offset -50）" 136 "Amplifier internal temperature value （Offset -50）" 135 "Amplifier internal temperature value （Offset -50）" 134 "Amplifier internal temperature value （Offset -50）" 133 "Amplifier internal temperature value （Offset -50）" 132 "Amplifier internal temperature value （Offset -50）" 131 "Amplifier internal temperature value （Offset -50）" 130 "Amplifier internal temperature value （Offset -50）" 129 "Amplifier internal temperature value （Offset -50）" 128 "Amplifier internal temperature value （Offset -50）" 127 "Amplifier internal temperature value （Offset -50）" 126 "Amplifier internal temperature value （Offset -50）" 125 "Amplifier internal temperature value （Offset -50）" 124 "Amplifier internal temperature value （Offset -50）" 123 "Amplifier internal temperature value （Offset -50）" 122 "Amplifier internal temperature value （Offset -50）" 121 "Amplifier internal temperature value （Offset -50）" 120 "Amplifier internal temperature value （Offset -50）" 119 "Amplifier internal temperature value （Offset -50）" 118 "Amplifier internal temperature value （Offset -50）" 117 "Amplifier internal temperature value （Offset -50）" 116 "Amplifier internal temperature value （Offset -50）" 115 "Amplifier internal temperature value （Offset -50）" 114 "Amplifier internal temperature value （Offset -50）" 113 "Amplifier internal temperature value （Offset -50）" 112 "Amplifier internal temperature value （Offset -50）" 111 "Amplifier internal temperature value （Offset -50）" 110 "Amplifier internal temperature value （Offset -50）" 109 "Amplifier internal temperature value （Offset -50）" 108 "Amplifier internal temperature value （Offset -50）" 107 "Amplifier internal temperature value （Offset -50）" 106 "Amplifier internal temperature value （Offset -50）" 105 "Amplifier internal temperature value （Offset -50）" 104 "Amplifier internal temperature value （Offset -50）" 103 "Amplifier internal temperature value （Offset -50）" 102 "Amplifier internal temperature value （Offset -50）" 101 "Amplifier internal temperature value （Offset -50）" 100 "Amplifier internal temperature value （Offset -50）" 99 "Amplifier internal temperature value （Offset -50）" 98 "Amplifier internal temperature value （Offset -50）" 97 "Amplifier internal temperature value （Offset -50）" 96 "Amplifier internal temperature value （Offset -50）" 95 "Amplifier internal temperature value （Offset -50）" 94 "Amplifier internal temperature value （Offset -50）" 93 "Amplifier internal temperature value （Offset -50）" 92 "Amplifier internal temperature value （Offset -50）" 91 "Amplifier internal temperature value （Offset -50）" 90 "Amplifier internal temperature value （Offset -50）" 89 "Amplifier internal temperature value （Offset -50）" 88 "Amplifier internal temperature value （Offset -50）" 87 "Amplifier internal temperature value （Offset -50）" 86 "Amplifier internal temperature value （Offset -50）" 85 "Amplifier internal temperature value （Offset -50）" 84 "Amplifier internal temperature value （Offset -50）" 83 "Amplifier internal temperature value （Offset -50）" 82 "Amplifier internal temperature value （Offset -50）" 81 "Amplifier internal temperature value （Offset -50）" 80 "Amplifier internal temperature value （Offset -50）" 79 "Amplifier internal temperature value （Offset -50）" 78 "Amplifier internal temperature value （Offset -50）" 77 "Amplifier internal temperature value （Offset -50）" 76 "Amplifier internal temperature value （Offset -50）" 75 "Amplifier internal temperature value （Offset -50）" 74 "Amplifier internal temperature value （Offset -50）" 73 "Amplifier internal temperature value （Offset -50）" 72 "Amplifier internal temperature value （Offset -50）" 71 "Amplifier internal temperature value （Offset -50）" 70 "Amplifier internal temperature value （Offset -50）" 69 "Amplifier internal temperature value （Offset -50）" 68 "Amplifier internal temperature value （Offset -50）" 67 "Amplifier internal temperature value （Offset -50）" 66 "Amplifier internal temperature value （Offset -50）" 65 "Amplifier internal temperature value （Offset -50）" 64 "Amplifier internal temperature value （Offset -50）" 63 "Amplifier internal temperature value （Offset -50）" 62 "Amplifier internal temperature value （Offset -50）" 61 "Amplifier internal temperature value （Offset -50）" 60 "Amplifier internal temperature value （Offset -50）" 59 "Amplifier internal temperature value （Offset -50）" 58 "Amplifier internal temperature value （Offset -50）" 57 "Amplifier internal temperature value （Offset -50）" 56 "Amplifier internal temperature value （Offset -50）" 55 "Amplifier internal temperature value （Offset -50）" 54 "Amplifier internal temperature value （Offset -50）" 53 "Amplifier internal temperature value （Offset -50）" 52 "Amplifier internal temperature value （Offset -50）" 51 "Amplifier internal temperature value （Offset -50）" 50 "Amplifier internal temperature value （Offset -50）" 49 "Amplifier internal temperature value （Offset -50）" 48 "Amplifier internal temperature value （Offset -50）" 47 "Amplifier internal temperature value （Offset -50）" 46 "Amplifier internal temperature value （Offset -50）" 45 "Amplifier internal temperature value （Offset -50）" 44 "Amplifier internal temperature value （Offset -50）" 43 "Amplifier internal temperature value （Offset -50）" 42 "Amplifier internal temperature value （Offset -50）" 41 "Amplifier internal temperature value （Offset -50）" 40 "Amplifier internal temperature value （Offset -50）" 39 "Amplifier internal temperature value （Offset -50）" 38 "Amplifier internal temperature value （Offset -50）" 37 "Amplifier internal temperature value （Offset -50）" 36 "Amplifier internal temperature value （Offset -50）" 35 "Amplifier internal temperature value （Offset -50）" 34 "Amplifier internal temperature value （Offset -50）" 33 "Amplifier internal temperature value （Offset -50）" 32 "Amplifier internal temperature value （Offset -50）" 31 "Amplifier internal temperature value （Offset -50）" 30 "Amplifier internal temperature value （Offset -50）" 29 "Amplifier internal temperature value （Offset -50）" 28 "Amplifier internal temperature value （Offset -50）" 27 "Amplifier internal temperature value （Offset -50）" 26 "Amplifier internal temperature value （Offset -50）" 25 "Amplifier internal temperature value （Offset -50）" 24 "Amplifier internal temperature value （Offset -50）" 23 "Amplifier internal temperature value （Offset -50）" 22 "Amplifier internal temperature value （Offset -50）" 21 "Amplifier internal temperature value （Offset -50）" 20 "Amplifier internal temperature value （Offset -50）" 19 "Amplifier internal temperature value （Offset -50）" 18 "Amplifier internal temperature value （Offset -50）" 17 "Amplifier internal temperature value （Offset -50）" 16 "Amplifier internal temperature value （Offset -50）" 15 "Amplifier internal temperature value （Offset -50）" 14 "Amplifier internal temperature value （Offset -50）" 13 "Amplifier internal temperature value （Offset -50）" 12 "Amplifier internal temperature value （Offset -50）" 11 "Amplifier internal temperature value （Offset -50）" 10 "Amplifier internal temperature value （Offset -50）" 9 "Amplifier internal temperature value （Offset -50）" 8 "Amplifier internal temperature value （Offset -50）" 7 "Amplifier internal temperature value （Offset -50）" 6 "Amplifier internal temperature value （Offset -50）" 5 "Amplifier internal temperature value （Offset -50）" 4 "Amplifier internal temperature value （Offset -50）" 3 "Amplifier internal temperature value （Offset -50）" 2 "Amplifier internal temperature value （Offset -50）" 1 "Amplifier internal temperature value （Offset -50）" 0 "Amplifier internal temperature value （Offset -50）" ;
VAL_ 188 AMP_SpeakMid 3 "No Command" 2 "Reserved" 1 "ON" 0 "OFF" ;
VAL_ 188 AMP_SpeakrRR 3 "No Command" 2 "Reserved" 1 "ON" 0 "OFF" ;
VAL_ 188 AMP_SpeakrRL 3 "No Command" 2 "Reserved" 1 "ON" 0 "OFF" ;
VAL_ 188 AMP_SpeakrFR 3 "No Command" 2 "Reserved" 1 "ON" 0 "OFF" ;
VAL_ 188 AMP_SpeakFL 3 "No Command" 2 "Reserved" 1 "ON" 0 "OFF" ;
VAL_ 188 AMP_MediaSourceSt 15 " No Command" 14 "Reserved" 13 "Reserved" 12 "Reserved" 11 "projection screen" 10 "Rear Audio and Video" 9 "3rd Party" 8 "Flytek Game" 7 "Flytek Media " 6 "Carlife Audio" 5 "Carplay Audio" 4 "USB2 Media" 3 "USB1 Media" 2 "Radio" 1 "BT Music" 0 "None" ;
VAL_ 188 AMP_ClariFiSt 3 "No Command" 2 "Reserved" 1 "ON" 0 "OFF" ;
VAL_ 188 AMP_PowerSts 3 "No Command" 2 "Reserved" 1 "ON" 0 "OFF" ;
VAL_ 188 AMP_HighFrqSet 31 "No Command" 30 "Reserved" 29 "Reserved" 28 "Reserved" 27 "Reserved" 26 "Reserved" 25 "Reserved" 24 "Reserved" 23 "Reserved" 22 "Reserved" 21 "Reserved" 20 "10" 19 "9" 18 "8" 17 "7" 16 "6" 15 "5" 14 "4" 13 "3" 12 "2" 11 "1" 10 "0" 9 "-1" 8 "-2" 7 "-3" 6 "-4" 5 "-5" 4 "-6" 3 "-7" 2 "-8" 1 "-9" 0 "-10" ;
VAL_ 188 AMP_TreSurSetSt 3 "No Command" 2 "Reserved" 1 "Surround" 0 "Stereo" ;
VAL_ 188 AMP_GetHUTInfoSts 3 "No Command" 2 "Reserved" 1 "Action" 0 "No action" ;
VAL_ 188 AMP_TEL_ECallSts 3 "No Command" 2 "Reserved" 1 "ON" 0 "OFF" ;
VAL_ 188 AMP_MuteRearSet 3 "No Command" 2 "Reserved" 1 " Mute" 0 " Unmute" ;
VAL_ 188 AMP_MuteSt 3 "No Command" 2 "Reserved" 1 "Mute" 0 "Unmute" ;
VAL_ 188 AMP_DriveSideSt 3 "No Command" 2 "Reserved" 1 "RHD" 0 "LHD" ;
VAL_ 188 AMP_MidFrqSet 31 "No Command" 30 "Reserved" 29 "Reserved" 28 "Reserved" 27 "Reserved" 26 "Reserved" 25 "Reserved" 24 "Reserved" 23 "Reserved" 22 "Reserved" 21 "Reserved" 20 "10" 19 "9" 18 "8" 17 "7" 16 "6" 15 "5" 14 "4" 13 "3" 12 "2" 11 "1" 10 "0" 9 "-1" 8 "-2" 7 "-3" 6 "-4" 5 "-5" 4 "-6" 3 "-7" 2 "-8" 1 "-9" 0 "-10" ;
VAL_ 188 AMP_LowFrqSet 31 "No Command" 30 "Reserved" 29 "Reserved" 28 "Reserved" 27 "Reserved" 26 "Reserved" 25 "Reserved" 24 "Reserved" 23 "Reserved" 22 "Reserved" 21 "Reserved" 20 "+1 - +10" 19 "+1 - +10" 18 "+1 - +10" 17 "+1 - +10" 16 "+1 - +10" 15 "+1 - +10" 14 "+1 - +10" 13 "+1 - +10" 12 "+1 - +10" 11 "+1 - +10" 10 "0" 9 "-10 - -1" 8 "-10 - -1" 7 "-10 - -1" 6 "-10 - -1" 5 "-10 - -1" 4 "-10 - -1" 3 "-10 - -1" 2 "-10 - -1" 1 "-10 - -1" 0 "-10 - -1" ;
VAL_ 188 AMP_VSCModeSt 7 "No Command" 6 "Reserved" 5 "Reserved" 4 "Reserved" 3 "HI" 2 "MID" 1 "LOW" 0 "OFF" ;
VAL_ 188 AMP_FadeSetSt 31 "No Command" 30 "Reserved" 29 "Reserved" 28 "Reserved" 27 "Reserved" 26 "Reserved" 25 "Reserved" 24 "Reserved" 23 "Reserved" 22 "Reserved" 21 "Reserved" 20 "Front+1 - Front+10" 19 "Front+1 - Front+10" 18 "Front+1 - Front+10" 17 "Front+1 - Front+10" 16 "Front+1 - Front+10" 15 "Front+1 - Front+10" 14 "Front+1 - Front+10" 13 "Front+1 - Front+10" 12 "Front+1 - Front+10" 11 "Front+1 - Front+10" 10 "Center" 9 "Rear+10 - Rear+1" 8 "Rear+10 - Rear+1" 7 "Rear+10 - Rear+1" 6 "Rear+10 - Rear+1" 5 "Rear+10 - Rear+1" 4 "Rear+10 - Rear+1" 3 "Rear+10 - Rear+1" 2 "Rear+10 - Rear+1" 1 "Rear+10 - Rear+1" 0 "Rear+10 - Rear+1" ;
VAL_ 188 AMP_BeepSourceSts 7 "No Command" 6 "Reserved(CH III)" 5 "Reserved(CH III)" 4 "Reserved(CH III)" 3 "Warning on" 2 "Radar on" 1 "Beep on" 0 "None" ;
VAL_ 188 AMP_BlcSetSt 31 "No Command" 30 "Reserved" 29 "Reserved" 28 "Reserved" 27 "Reserved" 26 "Reserved" 25 "Reserved" 24 "Reserved" 23 "Reserved" 22 "Reserved" 21 "Reserved" 20 "Rch+1 - Rch+10" 19 "Rch+1 - Rch+10" 18 "Rch+1 - Rch+10" 17 "Rch+1 - Rch+10" 16 "Rch+1 - Rch+10" 15 "Rch+1 - Rch+10" 14 "Rch+1 - Rch+10" 13 "Rch+1 - Rch+10" 12 "Rch+1 - Rch+10" 11 "Rch+1 - Rch+10" 10 "Center" 9 "Lch+10 - Lch+1" 8 "Lch+10 - Lch+1" 7 "Lch+10 - Lch+1" 6 "Lch+10 - Lch+1" 5 "Lch+10 - Lch+1" 4 "Lch+10 - Lch+1" 3 "Lch+10 - Lch+1" 2 "Lch+10 - Lch+1" 1 "Lch+10 - Lch+1" 0 "Lch+10 - Lch+1" ;
VAL_ 1049 FRDCM_NMWakeupOrigin 255 "Reserved" 254 "Reserved" 253 "Reserved" 252 "Reserved" 251 "Reserved" 250 "Reserved" 249 "Reserved" 248 "Reserved" 247 "Reserved" 246 "Reserved" 245 "Reserved" 244 "Reserved" 243 "Reserved" 242 "Reserved" 241 "Reserved" 240 "Reserved" 239 "Reserved" 238 "Reserved" 237 "Reserved" 236 "Reserved" 235 "Reserved" 234 "Reserved" 233 "Reserved" 232 "Reserved" 231 "Reserved" 230 "Reserved" 229 "Reserved" 228 "Reserved" 227 "Reserved" 226 "Reserved" 225 "Reserved" 224 "Reserved" 223 "Reserved" 222 "Reserved" 221 "Reserved" 220 "Reserved" 219 "Reserved" 218 "Reserved" 217 "Reserved" 216 "Reserved" 215 "Reserved" 214 "Reserved" 213 "Reserved" 212 "Reserved" 211 "Reserved" 210 "Reserved" 209 "Reserved" 208 "Reserved" 207 "Reserved" 206 "Reserved" 205 "Reserved" 204 "Reserved" 203 "Reserved" 202 "Reserved" 201 "Reserved" 200 "Reserved" 199 "Reserved" 198 "Reserved" 197 "Reserved" 196 "Reserved" 195 "Reserved" 194 "Reserved" 193 "Reserved" 192 "Reserved" 191 "Reserved" 190 "Reserved" 189 "Reserved" 188 "Reserved" 187 "Reserved" 186 "Reserved" 185 "Reserved" 184 "Reserved" 183 "Reserved" 182 "Reserved" 181 "Reserved" 180 "Reserved" 179 "Reserved" 178 "Reserved" 177 "Reserved" 176 "Reserved" 175 "Reserved" 174 "Reserved" 173 "Reserved" 172 "Reserved" 171 "Reserved" 170 "Reserved" 169 "Reserved" 168 "Reserved" 167 "Reserved" 166 "Reserved" 165 "Reserved" 164 "Reserved" 163 "Reserved" 162 "Reserved" 161 "Reserved" 160 "Reserved" 159 "Reserved" 158 "Reserved" 157 "Reserved" 156 "Reserved" 155 "Reserved" 154 "Reserved" 153 "Reserved" 152 "Reserved" 151 "Reserved" 150 "Reserved" 149 "Reserved" 148 "Reserved" 147 "Reserved" 146 "Reserved" 145 "Reserved" 144 "Reserved" 143 "Reserved" 142 "Reserved" 141 "Reserved" 140 "Reserved" 139 "Reserved" 138 "Reserved" 137 "Reserved" 136 "Reserved" 135 "Reserved" 134 "Reserved" 133 "Reserved" 132 "Reserved" 131 "Reserved" 130 "Reserved" 129 "Reserved" 128 "Reserved" 127 "Reserved" 126 "Reserved" 125 "Reserved" 124 "Reserved" 123 "Reserved" 122 "Reserved" 121 "Reserved" 120 "Reserved" 119 "Reserved" 118 "Reserved" 117 "Reserved" 116 "Reserved" 115 "Reserved" 114 "Reserved" 113 "Reserved" 112 "Reserved" 111 "Reserved" 110 "Reserved" 109 "Reserved" 108 "Reserved" 107 "Reserved" 106 "Reserved" 105 "Reserved" 104 "Reserved" 103 "Reserved" 102 "Reserved" 101 "Reserved" 100 "Reserved" 99 "Reserved" 98 "Reserved" 97 "Reserved" 96 "Reserved" 95 "Reserved" 94 "Reserved" 93 "Reserved" 92 "Reserved" 91 "Reserved" 90 "Reserved" 89 "Reserved" 88 "Reserved" 87 "Reserved" 86 "Reserved" 85 "Reserved" 84 "Reserved" 83 "Reserved" 82 "Reserved" 81 "Reserved" 80 "Reserved" 79 "Reserved" 78 "Reserved" 77 "Reserved" 76 "Reserved" 75 "Reserved" 74 "Reserved" 73 "Reserved" 72 "Reserved" 71 "Reserved" 70 "Reserved" 69 "Reserved" 68 "Reserved" 67 "Reserved" 66 "Reserved" 65 "Reserved" 64 "Reserved" 63 "Reserved" 62 "Reserved" 61 "Reserved" 60 "Reserved" 59 "Reserved" 58 "Reserved" 57 "Reserved" 56 "Reserved" 55 "Reserved" 54 "Reserved" 53 "Reserved" 52 "Reserved" 51 "Reserved" 50 "Reserved" 49 "Reserved" 48 "Reserved" 47 "Reserved" 46 "Reserved" 45 "Reserved" 44 "Reserved" 43 "Reserved" 42 "Reserved" 41 "Reserved" 40 "Reserved" 39 "Reserved" 38 "Reserved" 37 "Reserved" 36 "Reserved" 35 "Reserved" 34 "Reserved" 33 "Reserved" 32 "Reserved" 31 "Reserved" 30 "Reserved" 29 "Reserved" 28 "Reserved" 27 "Reserved" 26 "Reserved" 25 "Reserved" 24 "Reserved" 23 "Reserved" 22 "Reserved" 21 "Reserved" 20 "Reserved" 19 "Reserved" 18 "Reserved" 17 "Reserved" 16 "Reserved" 15 "Reserved" 14 "Reserved" 13 "Reserved" 12 "Reserved" 11 "Reserved" 10 "Reserved" 9 "Reserved" 8 "Reserved" 7 "Reserved" 6 "Reserved" 5 "Reserved" 4 "Reserved" 3 "Reserved" 2 "Reserved" 1 "Message wake up" ;
VAL_ 1049 FRDCM_NMSleepAck 1 "Active" 0 "Not active" ;
VAL_ 1049 FRDCM_NMSleepInd 1 "Active" 0 "Not active" ;
VAL_ 1049 FRDCM_NMLimpHome 1 "Active" 0 "Not active" ;
VAL_ 1049 FRDCM_NMRing 1 "Active" 0 "Not active" ;
VAL_ 1049 FRDCM_NMAlive 1 "Active" 0 "Not active" ;
VAL_ 999 FRDCM_RRWinVentilateModeSt 1 " Actived" 0 " Not actived" ;
VAL_ 999 FRDCM_FRWinVentilateModeSt 1 " Actived" 0 " Not actived" ;
VAL_ 999 FRDCM_RRWinOverheatSt 1 "Actived" 0 "Not actived" ;
VAL_ 999 FRDCM_FRWinOverheatSt 1 "Actived" 0 "Not actived" ;
VAL_ 999 FRDCM_MirrorFoldUnfoldSt 3 "Reserved" 2 "Unfold" 1 "Fold" 0 "Unkonw" ;
VAL_ 999 FRDCM_RRChildLockSt 3 "not used;" 2 "childlock error;" 1 "childlock lock;" 0 "childlock unlock;" ;
VAL_ 999 FRDCM_RRWinOperationSt 3 "Anti-pinch reversing " 2 "Window opening" 1 "Window closing" 0 "Window stoped" ;
VAL_ 999 FRDCM_FRWinOperationSt 3 "Anti-pinch reversing " 2 "Window opening" 1 "Window closing" 0 "Window stoped" ;
VAL_ 999 FRDCM_RRWinSt 3 "Window fully opened" 2 "Between fully closed and fully opened" 1 "Window fully closed" 0 "Undefined window position" ;
VAL_ 999 FRDCM_FRWinSt 3 "Window fully opened" 2 "Between fully closed and fully opened" 1 "Window fully closed" 0 "Undefined window position" ;
VAL_ 1048 FLDCM_NMSleepAck 1 "Active" 0 "Not active" ;
VAL_ 1048 FLDCM_NMSleepInd 1 "Active" 0 "Not active" ;
VAL_ 1048 FLDCM_NMLimpHome 1 "Active" 0 "Not active" ;
VAL_ 1048 FLDCM_NMRing 1 "Active" 0 "Not active" ;
VAL_ 1048 FLDCM_NMAlive 1 "Active" 0 "Not active" ;
VAL_ 997 FLDCM_RLWinVentilateModeSt 1 " Actived" 0 " Not actived" ;
VAL_ 997 FLDCM_FLWinVentilateModeSt 1 " Actived" 0 " Not actived" ;
VAL_ 997 FLDCM_MirrorFoldUnfoldSt 3 "Reserved" 2 "Unfold" 1 "Fold" 0 "Unkonw" ;
VAL_ 997 FLDCM_RLWinOperationSt 3 "Anti-pinch reversing " 2 "Window opening" 1 "Window closing" 0 "Window stoped" ;
VAL_ 997 FLDCM_FLWinOperationSt 3 "Anti-pinch reversing " 2 "Window opening" 1 "Window closing" 0 "Window stoped" ;
VAL_ 997 FLDCM_OSRMAngleAdjFuncCfgSt 3 "Both mirror dip" 2 "Right mirror dip" 1 "Left mirror dip" 0 "Off" ;
VAL_ 997 FLDCM_MemorySysBuzzerReq 3 "Not used" 2 "Sound twice" 1 "Sound once" 0 "Inactive" ;
VAL_ 997 FLDCM_RLWinOverheatSt 1 "Actived" 0 "Not actived" ;
VAL_ 997 FLDCM_FLWinOverheatSt 1 "Actived" 0 "Not actived" ;
VAL_ 997 FLDCM_APWLEnableSt 1 "Enable" 0 "Disable" ;
VAL_ 997 FLDCM_PowerWinOpenWarn 1 "Warning" 0 "Not Warning" ;
VAL_ 997 FLDCM_MemSysOperationReq 1 "Active pop-up window" 0 "No command" ;
VAL_ 997 FLDCM_RLChildLockSt 3 "not used;" 2 "childlock error;" 1 "childlock lock;" 0 "childlock unlock;" ;
VAL_ 997 FLDCM_RLWinSt 3 "Window fully opened" 2 "Between fully closed and fully opened" 1 "Window fully closed" 0 "Undefined window position" ;
VAL_ 997 FLDCM_FLWinSt 3 "Window fully opened" 2 "Between fully closed and fully opened" 1 "Window fully closed" 0 "Undefined window position" ;
VAL_ 1070 IAL_NMWakeupOrignin 255 "Reserved" 254 "Reserved" 253 "Reserved" 252 "Reserved" 251 "Reserved" 250 "Reserved" 249 "Reserved" 248 "Reserved" 247 "Reserved" 246 "Reserved" 245 "Reserved" 244 "Reserved" 243 "Reserved" 242 "Reserved" 241 "Reserved" 240 "Reserved" 239 "Reserved" 238 "Reserved" 237 "Reserved" 236 "Reserved" 235 "Reserved" 234 "Reserved" 233 "Reserved" 232 "Reserved" 231 "Reserved" 230 "Reserved" 229 "Reserved" 228 "Reserved" 227 "Reserved" 226 "Reserved" 225 "Reserved" 224 "Reserved" 223 "Reserved" 222 "Reserved" 221 "Reserved" 220 "Reserved" 219 "Reserved" 218 "Reserved" 217 "Reserved" 216 "Reserved" 215 "Reserved" 214 "Reserved" 213 "Reserved" 212 "Reserved" 211 "Reserved" 210 "Reserved" 209 "Reserved" 208 "Reserved" 207 "Reserved" 206 "Reserved" 205 "Reserved" 204 "Reserved" 203 "Reserved" 202 "Reserved" 201 "Reserved" 200 "Reserved" 199 "Reserved" 198 "Reserved" 197 "Reserved" 196 "Reserved" 195 "Reserved" 194 "Reserved" 193 "Reserved" 192 "Reserved" 191 "Reserved" 190 "Reserved" 189 "Reserved" 188 "Reserved" 187 "Reserved" 186 "Reserved" 185 "Reserved" 184 "Reserved" 183 "Reserved" 182 "Reserved" 181 "Reserved" 180 "Reserved" 179 "Reserved" 178 "Reserved" 177 "Reserved" 176 "Reserved" 175 "Reserved" 174 "Reserved" 173 "Reserved" 172 "Reserved" 171 "Reserved" 170 "Reserved" 169 "Reserved" 168 "Reserved" 167 "Reserved" 166 "Reserved" 165 "Reserved" 164 "Reserved" 163 "Reserved" 162 "Reserved" 161 "Reserved" 160 "Reserved" 159 "Reserved" 158 "Reserved" 157 "Reserved" 156 "Reserved" 155 "Reserved" 154 "Reserved" 153 "Reserved" 152 "Reserved" 151 "Reserved" 150 "Reserved" 149 "Reserved" 148 "Reserved" 147 "Reserved" 146 "Reserved" 145 "Reserved" 144 "Reserved" 143 "Reserved" 142 "Reserved" 141 "Reserved" 140 "Reserved" 139 "Reserved" 138 "Reserved" 137 "Reserved" 136 "Reserved" 135 "Reserved" 134 "Reserved" 133 "Reserved" 132 "Reserved" 131 "Reserved" 130 "Reserved" 129 "Reserved" 128 "Reserved" 127 "Reserved" 126 "Reserved" 125 "Reserved" 124 "Reserved" 123 "Reserved" 122 "Reserved" 121 "Reserved" 120 "Reserved" 119 "Reserved" 118 "Reserved" 117 "Reserved" 116 "Reserved" 115 "Reserved" 114 "Reserved" 113 "Reserved" 112 "Reserved" 111 "Reserved" 110 "Reserved" 109 "Reserved" 108 "Reserved" 107 "Reserved" 106 "Reserved" 105 "Reserved" 104 "Reserved" 103 "Reserved" 102 "Reserved" 101 "Reserved" 100 "Reserved" 99 "Reserved" 98 "Reserved" 97 "Reserved" 96 "Reserved" 95 "Reserved" 94 "Reserved" 93 "Reserved" 92 "Reserved" 91 "Reserved" 90 "Reserved" 89 "Reserved" 88 "Reserved" 87 "Reserved" 86 "Reserved" 85 "Reserved" 84 "Reserved" 83 "Reserved" 82 "Reserved" 81 "Reserved" 80 "Reserved" 79 "Reserved" 78 "Reserved" 77 "Reserved" 76 "Reserved" 75 "Reserved" 74 "Reserved" 73 "Reserved" 72 "Reserved" 71 "Reserved" 70 "Reserved" 69 "Reserved" 68 "Reserved" 67 "Reserved" 66 "Reserved" 65 "Reserved" 64 "Reserved" 63 "Reserved" 62 "Reserved" 61 "Reserved" 60 "Reserved" 59 "Reserved" 58 "Reserved" 57 "Reserved" 56 "Reserved" 55 "Reserved" 54 "Reserved" 53 "Reserved" 52 "Reserved" 51 "Reserved" 50 "Reserved" 49 "Reserved" 48 "Reserved" 47 "Reserved" 46 "Reserved" 45 "Reserved" 44 "Reserved" 43 "Reserved" 42 "Reserved" 41 "Reserved" 40 "Reserved" 39 "Reserved" 38 "Reserved" 37 "Reserved" 36 "Reserved" 35 "Reserved" 34 "Reserved" 33 "Reserved" 32 "Reserved" 31 "Reserved" 30 "Reserved" 29 "Reserved" 28 "Reserved" 27 "Reserved" 26 "Reserved" 25 "Reserved" 24 "Reserved" 23 "Reserved" 22 "Reserved" 21 "Reserved" 20 "Reserved" 19 "Reserved" 18 "Reserved" 17 "IGN ACC" 16 "Not used" 15 "Not used" 14 "Not used" 13 "Not used" 12 "Not used" 11 "Not used" 10 "Not used" 9 "Not used" 8 "Not used" 7 "Not used" 6 "Not used" 5 "Not used" 4 "Not used" 3 "Not used" 2 "Not used" 1 "Message wake up" 0 "Not used" ;
VAL_ 1070 IAL_NMSleepAck 1 "Active" 0 "Not active" ;
VAL_ 1070 IAL_NMSleepInd 1 "Active" 0 "Not active" ;
VAL_ 1070 IAL_NMLimpHome 1 "Active" 0 "Not active" ;
VAL_ 1070 IAL_NMRing 1 "Active" 0 "Not active" ;
VAL_ 1070 IAL_NMAlive 1 "Active" 0 "Not active" ;
VAL_ 1023 IAL_ShortcutMode 15 " Reserved" 14 " Reserved" 13 " Reserved" 12 " Reserved" 11 " Reserved" 10 " Reserved" 9 " Reserved" 8 " Reserved" 7 " Reserved" 6 "quiet Mode" 5 "Party mode" 4 "Wake up mode" 3 "nap mode" 2 "rainstorm mode" 1 "ECO+ Mode" 0 "Normal Mode" ;
VAL_ 1023 IAL_LightWorkSt 3 "Reserved" 2 "Reserved" 1 "Normal ON" 0 "Normal OFF" ;
VAL_ 1023 IAL_WorkSt 15 "Reserved" 14 "Reserved" 13 "Reserved" 12 "Reserved" 11 "Reserved" 10 "Reserved" 9 "Reserved" 8 "Reserved" 7 "Reserved" 6 "Reserved" 5 "CombinedcolorMode 3" 4 "CombinedcolorMode 2" 3 "CombinedcolorMode 1" 2 "DriverMode" 1 "ColorChooseMode" 0 "OFF" ;
VAL_ 847 HVSMR_RRHVSMRAutoModeSt 1 "Auto mode ON" 0 "Auto mode OFF" ;
VAL_ 847 HVSMR_RRVentilatingActLevel 7 "Error" 6 "Not used" 5 "Not used" 4 "Not used" 3 "Level 3" 2 "Level 2" 1 "Level 1" 0 "Off" ;
VAL_ 847 HVSMR_RLHVSMRAutoModeSt 1 "Auto mode ON" 0 "Auto mode OFF" ;
VAL_ 847 HVSMR_RLVentilatingActLevel 7 "Error" 6 "Not used" 5 "Not used" 4 "Not used" 3 "Level 3" 2 "Level 2" 1 "Level 1" 0 "Off" ;
VAL_ 847 HVSMR_RRSeatTempVD 1 "Valid" 0 "Not valid" ;
VAL_ 847 HVSMR_RRHeatingActLevel 7 "Error" 6 "Not used" 5 "Not used" 4 "Not used" 3 "Level 3" 2 "Level 2" 1 "Level 1" 0 "Off" ;
VAL_ 847 HVSMR_RLSeatTempVD 1 "Valid" 0 "Not valid" ;
VAL_ 847 HVSMR_RLHeatingActLevel 7 "Error" 6 "Not used" 5 "Not used" 4 "Not used" 3 "Level 3" 2 "Level 2" 1 "Level 1" 0 "Off" ;
VAL_ 1083 HVSM_NMWakeupOrigin 255 "Reserved" 254 "Reserved" 253 "Reserved" 252 "Reserved" 251 "Reserved" 250 "Reserved" 249 "Reserved" 248 "Reserved" 247 "Reserved" 246 "Reserved" 245 "Reserved" 244 "Reserved" 243 "Reserved" 242 "Reserved" 241 "Reserved" 240 "Reserved" 239 "Reserved" 238 "Reserved" 237 "Reserved" 236 "Reserved" 235 "Reserved" 234 "Reserved" 233 "Reserved" 232 "Reserved" 231 "Reserved" 230 "Reserved" 229 "Reserved" 228 "Reserved" 227 "Reserved" 226 "Reserved" 225 "Reserved" 224 "Reserved" 223 "Reserved" 222 "Reserved" 221 "Reserved" 220 "Reserved" 219 "Reserved" 218 "Reserved" 217 "Reserved" 216 "Reserved" 215 "Reserved" 214 "Reserved" 213 "Reserved" 212 "Reserved" 211 "Reserved" 210 "Reserved" 209 "Reserved" 208 "Reserved" 207 "Reserved" 206 "Reserved" 205 "Reserved" 204 "Reserved" 203 "Reserved" 202 "Reserved" 201 "Reserved" 200 "Reserved" 199 "Reserved" 198 "Reserved" 197 "Reserved" 196 "Reserved" 195 "Reserved" 194 "Reserved" 193 "Reserved" 192 "Reserved" 191 "Reserved" 190 "Reserved" 189 "Reserved" 188 "Reserved" 187 "Reserved" 186 "Reserved" 185 "Reserved" 184 "Reserved" 183 "Reserved" 182 "Reserved" 181 "Reserved" 180 "Reserved" 179 "Reserved" 178 "Reserved" 177 "Reserved" 176 "Reserved" 175 "Reserved" 174 "Reserved" 173 "Reserved" 172 "Reserved" 171 "Reserved" 170 "Reserved" 169 "Reserved" 168 "Reserved" 167 "Reserved" 166 "Reserved" 165 "Reserved" 164 "Reserved" 163 "Reserved" 162 "Reserved" 161 "Reserved" 160 "Reserved" 159 "Reserved" 158 "Reserved" 157 "Reserved" 156 "Reserved" 155 "Reserved" 154 "Reserved" 153 "Reserved" 152 "Reserved" 151 "Reserved" 150 "Reserved" 149 "Reserved" 148 "Reserved" 147 "Reserved" 146 "Reserved" 145 "Reserved" 144 "Reserved" 143 "Reserved" 142 "Reserved" 141 "Reserved" 140 "Reserved" 139 "Reserved" 138 "Reserved" 137 "Reserved" 136 "Reserved" 135 "Reserved" 134 "Reserved" 133 "Reserved" 132 "Reserved" 131 "Reserved" 130 "Reserved" 129 "Reserved" 128 "Reserved" 127 "Reserved" 126 "Reserved" 125 "Reserved" 124 "Reserved" 123 "Reserved" 122 "Reserved" 121 "Reserved" 120 "Reserved" 119 "Reserved" 118 "Reserved" 117 "Reserved" 116 "Reserved" 115 "Reserved" 114 "Reserved" 113 "Reserved" 112 "Reserved" 111 "Reserved" 110 "Reserved" 109 "Reserved" 108 "Reserved" 107 "Reserved" 106 "Reserved" 105 "Reserved" 104 "Reserved" 103 "Reserved" 102 "Reserved" 101 "Reserved" 100 "Reserved" 99 "Reserved" 98 "Reserved" 97 "Reserved" 96 "Reserved" 95 "Reserved" 94 "Reserved" 93 "Reserved" 92 "Reserved" 91 "Reserved" 90 "Reserved" 89 "Reserved" 88 "Reserved" 87 "Reserved" 86 "Reserved" 85 "Reserved" 84 "Reserved" 83 "Reserved" 82 "Reserved" 81 "Reserved" 80 "Reserved" 79 "Reserved" 78 "Reserved" 77 "Reserved" 76 "Reserved" 75 "Reserved" 74 "Reserved" 73 "Reserved" 72 "Reserved" 71 "Reserved" 70 "Reserved" 69 "Reserved" 68 "Reserved" 67 "Reserved" 66 "Reserved" 65 "Reserved" 64 "Reserved" 63 "Reserved" 62 "Reserved" 61 "Reserved" 60 "Reserved" 59 "Reserved" 58 "Reserved" 57 "Reserved" 56 "Reserved" 55 "Reserved" 54 "Reserved" 53 "Reserved" 52 "Reserved" 51 "Reserved" 50 "Reserved" 49 "Reserved" 48 "Reserved" 47 "Reserved" 46 "Reserved" 45 "Reserved" 44 "Reserved" 43 "Reserved" 42 "Reserved" 41 "Reserved" 40 "Reserved" 39 "Reserved" 38 "Reserved" 37 "Reserved" 36 "Reserved" 35 "Reserved" 34 "Reserved" 33 "Reserved" 32 "Reserved" 31 "Reserved" 30 "Reserved" 29 "Reserved" 28 "Reserved" 27 "Reserved" 26 "Reserved" 25 "Reserved" 24 "Reserved" 23 "Reserved" 22 "Reserved" 21 "Reserved" 20 "Reserved" 19 "Reserved" 18 "Reserved" 17 "IGN ACC" 16 "Not used" 15 "Not used" 14 "Not used" 13 "Not used" 12 "Not used" 11 "Not used" 10 "Not used" 9 "Not used" 8 "Not used" 7 "Not used" 6 "Not used" 5 "Not used" 4 "Not used" 3 "Not used" 2 "Not used" 1 "Message wake up" ;
VAL_ 1083 HVSM_NMSleepAck 1 "Active" 0 "Not active" ;
VAL_ 1083 HVSM_NMSleepInd 1 "Active" 0 "Not active" ;
VAL_ 1083 HVSM_NMLimpHome 1 "Active" 0 "Not active" ;
VAL_ 1083 HVSM_NMRing 1 "Active" 0 "Not active" ;
VAL_ 1083 HVSM_NMAlive 1 "Active" 0 "Not active" ;
VAL_ 846 HVSM_FRVentilatingActLevel 7 "Error" 6 "Not used" 5 "Not used" 4 "Not used" 3 "Level 3" 2 "Level 2" 1 "Level 1" 0 "Off" ;
VAL_ 846 HVSM_FLVentilatingActLevel 7 "Error" 6 "Not used" 5 "Not used" 4 "Not used" 3 "Level 3" 2 "Level 2" 1 "Level 1" 0 "Off" ;
VAL_ 1068 HVACF_NMWakeupOrigin 255 "Reserved" 254 "Reserved" 253 "Reserved" 252 "Reserved" 251 "Reserved" 250 "Reserved" 249 "Reserved" 248 "Reserved" 247 "Reserved" 246 "Reserved" 245 "Reserved" 244 "Reserved" 243 "Reserved" 242 "Reserved" 241 "Reserved" 240 "Reserved" 239 "Reserved" 238 "Reserved" 237 "Reserved" 236 "Reserved" 235 "Reserved" 234 "Reserved" 233 "Reserved" 232 "Reserved" 231 "Reserved" 230 "Reserved" 229 "Reserved" 228 "Reserved" 227 "Reserved" 226 "Reserved" 225 "Reserved" 224 "Reserved" 223 "Reserved" 222 "Reserved" 221 "Reserved" 220 "Reserved" 219 "Reserved" 218 "Reserved" 217 "Reserved" 216 "Reserved" 215 "Reserved" 214 "Reserved" 213 "Reserved" 212 "Reserved" 211 "Reserved" 210 "Reserved" 209 "Reserved" 208 "Reserved" 207 "Reserved" 206 "Reserved" 205 "Reserved" 204 "Reserved" 203 "Reserved" 202 "Reserved" 201 "Reserved" 200 "Reserved" 199 "Reserved" 198 "Reserved" 197 "Reserved" 196 "Reserved" 195 "Reserved" 194 "Reserved" 193 "Reserved" 192 "Reserved" 191 "Reserved" 190 "Reserved" 189 "Reserved" 188 "Reserved" 187 "Reserved" 186 "Reserved" 185 "Reserved" 184 "Reserved" 183 "Reserved" 182 "Reserved" 181 "Reserved" 180 "Reserved" 179 "Reserved" 178 "Reserved" 177 "Reserved" 176 "Reserved" 175 "Reserved" 174 "Reserved" 173 "Reserved" 172 "Reserved" 171 "Reserved" 170 "Reserved" 169 "Reserved" 168 "Reserved" 167 "Reserved" 166 "Reserved" 165 "Reserved" 164 "Reserved" 163 "Reserved" 162 "Reserved" 161 "Reserved" 160 "Reserved" 159 "Reserved" 158 "Reserved" 157 "Reserved" 156 "Reserved" 155 "Reserved" 154 "Reserved" 153 "Reserved" 152 "Reserved" 151 "Reserved" 150 "Reserved" 149 "Reserved" 148 "Reserved" 147 "Reserved" 146 "Reserved" 145 "Reserved" 144 "Reserved" 143 "Reserved" 142 "Reserved" 141 "Reserved" 140 "Reserved" 139 "Reserved" 138 "Reserved" 137 "Reserved" 136 "Reserved" 135 "Reserved" 134 "Reserved" 133 "Reserved" 132 "Reserved" 131 "Reserved" 130 "Reserved" 129 "Reserved" 128 "Reserved" 127 "Reserved" 126 "Reserved" 125 "Reserved" 124 "Reserved" 123 "Reserved" 122 "Reserved" 121 "Reserved" 120 "Reserved" 119 "Reserved" 118 "Reserved" 117 "Reserved" 116 "Reserved" 115 "Reserved" 114 "Reserved" 113 "Reserved" 112 "Reserved" 111 "Reserved" 110 "Reserved" 109 "Reserved" 108 "Reserved" 107 "Reserved" 106 "Reserved" 105 "Reserved" 104 "Reserved" 103 "Reserved" 102 "Reserved" 101 "Reserved" 100 "Reserved" 99 "Reserved" 98 "Reserved" 97 "Reserved" 96 "Reserved" 95 "Reserved" 94 "Reserved" 93 "Reserved" 92 "Reserved" 91 "Reserved" 90 "Reserved" 89 "Reserved" 88 "Reserved" 87 "Reserved" 86 "Reserved" 85 "Reserved" 84 "Reserved" 83 "Reserved" 82 "Reserved" 81 "Reserved" 80 "Reserved" 79 "Reserved" 78 "Reserved" 77 "Reserved" 76 "Reserved" 75 "Reserved" 74 "Reserved" 73 "Reserved" 72 "Reserved" 71 "Reserved" 70 "Reserved" 69 "Reserved" 68 "Reserved" 67 "Reserved" 66 "Reserved" 65 "Reserved" 64 "Reserved" 63 "Reserved" 62 "Reserved" 61 "Reserved" 60 "Reserved" 59 "Reserved" 58 "Reserved" 57 "Reserved" 56 "Reserved" 55 "Reserved" 54 "Reserved" 53 "Reserved" 52 "Reserved" 51 "Reserved" 50 "Reserved" 49 "Reserved" 48 "Reserved" 47 "Reserved" 46 "Reserved" 45 "Reserved" 44 "Reserved" 43 "Reserved" 42 "Reserved" 41 "Reserved" 40 "Reserved" 39 "Reserved" 38 "Reserved" 37 "Reserved" 36 "Reserved" 35 "Reserved" 34 "Reserved" 33 "Reserved" 32 "Reserved" 31 "Reserved" 30 "Reserved" 29 "Reserved" 28 "Reserved" 27 "Reserved" 26 "Reserved" 25 "Reserved" 24 "Reserved" 23 "Reserved" 22 "Reserved" 21 "Reserved" 20 "Reserved" 19 "Reserved" 18 "IGN ON" 17 "Reserved" 16 "Reserved" 15 "Reserved" 14 "Reserved" 13 "Reserved" 12 "Reserved" 11 "Reserved" 10 "Reserved" 9 "Reserved" 8 "Reserved" 7 "Reserved" 6 "Reserved" 5 "Reserved" 4 "Reserved" 3 "Reserved" 2 "Reserved" 1 "Message wakeup" 0 "Reserved" ;
VAL_ 1068 HVACF_NMSleepAck 1 "Active" 0 "Not active" ;
VAL_ 1068 HVACF_NMSleepInd 1 "Active" 0 "Not active" ;
VAL_ 1068 HVACF_NMLimpHome 1 "Active" 0 "Not active" ;
VAL_ 1068 HVACF_NMRing 1 "Active" 0 "Not active" ;
VAL_ 1068 HVACF_NMAlive 1 "Active" 0 "Not active" ;
VAL_ 972 HVAC_FRAG_FraganceBoxID 3 "Box_3" 2 "Box_2" 1 "Box_1" 0 "None" ;
VAL_ 972 HVAC_FRAG_FraganceBoxLoad 15 "Invalid" 14 "Reserved" 13 "Reserved" 12 "Reserved" 11 "Reserved" ;
VAL_ 972 HVACF_FRAG_FraganceBoxIDXRatioWa 3 "Not used" 2 "FRAG Fragance Ratio Use Up Warning" 1 "FRAG Fragance Ratio Nearly Use Up Warning" 0 "No command" ;
VAL_ 972 HVAC_FRAG_FraganceConcentration 3 "High" 2 "Mid" 1 "Low" 0 "Off" ;
VAL_ 972 HVAC_FRAG_FraganceTaste 3 "Taste 3" 2 "Taste 2" 1 "Taste 1" 0 "No Action" ;
VAL_ 972 HVAC_FRAG_FragceTastRemantRatio 15 "Invalid" 14 "Reserved" 13 "Reserved" 12 "Reserved" 11 "Reserved" ;
VAL_ 972 HVACF_FRAGCFunction 1 "Have" 0 "Not have" ;
VAL_ 969 HVACF_RearWindExitSpd 15 "Not used" 14 "Not used" 13 "Not used" 12 "Not used" 11 "Not used" 10 "Not used" 9 "Not used" 8 "Not used" 7 "Level 7" 6 " Level 6" 5 "Level 5" 4 "Level 4" 3 " Level 3" 2 " Level 2" 1 "Level 1" 0 "OFF" ;
VAL_ 969 HVACF_IonPopUpReq 1 "Request" 0 "Not request" ;
VAL_ 969 HVACF_HumiditySns 1 "Have" 0 "Not have" ;
VAL_ 969 HVACF_UnlockVentilationSt 1 "ON" 0 "OFF" ;
VAL_ 969 HVACF_EvapratorSelfCleanSt 1 "ON" 0 "OFF" ;
VAL_ 969 HVACF_PopupDisplayReq2 30 "Not used" 29 "Not used" 28 "Not used" 27 "Not used" 26 "Not used" 25 "Not used" 24 "Not used" 23 "Not used" 22 "Not used" 21 "Not used" 20 "Not used" 19 "Not used" 18 "Not used" 17 "Not used" 16 "Not used" 15 "Not used" 14 "Not used" 13 "SYNC" 12 "ION" 11 "Acmax" 10 "Wind mode（Front）" 9 "Rdefrost" 8 "Fdefrost" 7 "Circulation mode" 6 "Acst" 5 "Auto（Front）" 4 "Wind（Front）" 3 "passenger temperature" 2 "driver temperature" 1 "ON/OFF" 0 "Not request" ;
VAL_ 797 HVACF_SceneDisplayReq 3 " Not used" 2 " Fast warming Scene" 1 "Fast cooling Scene" 0 "Comfort Scene" ;
VAL_ 797 HVACF_PM25CleanReqCfgSt 3 "Not used" 2 "Set on auto" 1 "Set on manual" 0 "Set Off" ;
VAL_ 797 HVACF_FanspeedCfgSt 3 "Not used" 2 "High" 1 "Normal" 0 "Low" ;
VAL_ 797 HVACF_PM25CleanReq 1 "Active" 0 "Not active" ;
VAL_ 797 HVACF_PM25Sns 1 "Have" 0 "Not have" ;
VAL_ 797 HVACF_PM10ValueVD 1 "Valid" 0 "Not valid" ;
VAL_ 797 HVACF_PM25ValueVD 1 "Valid" 0 "Not valid" ;
VAL_ 797 HVACF_AutoDefCfgSt 3 "Low sensitivity" 2 "Normal sensitivity" 1 "High sensitivity" 0 "Off" ;
VAL_ 797 HVACF_AirQqualitySenSt 3 "Not used" 2 "low sensitivity " 1 "normal sensitivity" 0 "high sensitivity " ;
VAL_ 797 HVACF_ComfortCfgSt 3 "Not used" 2 "Fast" 1 "Normal" 0 "Soft" ;
VAL_ 797 HVACF_AirCirCfgSt 1 "Manual air circulation" 0 "Auto air circulation" ;
VAL_ 797 HVACF_ACCfgSt 1 "A/C auto on turn off" 0 "A/C auto on turn on" ;
VAL_ 801 HVACF_SmartSt 0 "off" 1 "on" ;
VAL_ 801 HVACF_RearWindExitMode 7 "Not used" 6 "Not used                             " 5 "Not used                                 " 4 "Not used                           " 3 "Foot                                   " 2 "Face/Foot                        " 1 "Face                                                    " 0 "Invalid                            " ;
VAL_ 801 HVACF_RearAutoSt 1 "Auto Mode" 0 "Manual Mode                     " ;
VAL_ 801 HVACF_AirQualitySns 1 "Have" 0 "Not have" ;
VAL_ 801 HVACF_ZoneNum 3 "Not used" 2 "Three zones" 1 "Two zones" 0 "Single zone" ;
VAL_ 801 HVACF_RearSt 1 "Active" 0 "Not active" ;
VAL_ 801 HVACF_TripleZoneSt 1 "On" 0 "Off" ;
VAL_ 801 HVACF_RearTempSelect 31 "Invalid" 30 "reserved" 29 "reserved" ;
VAL_ 800 HVACF_PsnTempSelect 31 "Invalid" 30 "Reserved" 29 "Reserved" ;
VAL_ 800 HVACF_WindExitSpd 15 "Not used   " 14 "Not used" 13 "Not used" 12 "Not used" 11 "Not used" 10 "Not used" 9 "Not used" 8 "Not used" 7 "Level 7" 6 "Level 6" 5 "Level 5" 4 "Level 4" 3 "Level 3" 2 "Level 2" 1 "Level 1" 0 "Off" ;
VAL_ 800 HVACF_IonMode 3 "Not used" 2 "Not used" 1 "on" 0 "Off" ;
VAL_ 800 HVACF_DriverTempSelect 31 "Invalid" 30 "Reserved" 29 "Reserved" ;
VAL_ 800 HVACF_PopUpDisplayReq1 1 "Request" 0 "Not request" ;
VAL_ 800 HVACF_AirCirculationSt 3 "Air circulation auto control" 2 "Outside air circulation" 1 "Inner air circulation" 0 "Invalid" ;
VAL_ 800 HVACF_SYNCSt 1 "On" 0 "Off" ;
VAL_ 800 HVACF_TempSelectManual 7 "Level 7" 6 "Level 6" 5 "Level 5" 4 "Level 4" 3 "Level 3" 2 "Level 2" 1 "Level 1" 0 "Invalid" ;
VAL_ 800 HVACF_IonCleanFunction 1 "Have" 0 "Not have" ;
VAL_ 800 HVACF_WindExitMode 7 "Not used" 6 "Not used" 5 "Defrost" 4 "Foot/defrost" 3 "Foot" 2 "Face/foot" 1 "Face" 0 "Invalid" ;
VAL_ 800 HVACF_Type 1 "Automatic type" 0 "Manual type" ;
VAL_ 800 HVACF_AutoSt 1 "Auto mode" 0 "Manual mode" ;
VAL_ 800 HVACF_DualSyncSt 1 "Press" 0 "Release" ;
VAL_ 800 HVACF_TempSelectAuto 31 "Invalid" 30 "Reserved" 29 "Reserved" ;
VAL_ 800 HVACF_ACSt 1 "Active" 0 " Not active" ;
VAL_ 800 HVACF_CorrectedExterTempVD 1 "Valid" 0 "Not valid" ;
VAL_ 800 HVACF_RearDefrostSt 1 "Active" 0 "Not acitve" ;
VAL_ 1065 LCU_NMSleepAck 1 "Active" 0 "Not active" ;
VAL_ 1065 LCU_NMSleepInd 1 "Active" 0 "Not active" ;
VAL_ 1065 LCU_NMLimpHome 1 "Active" 0 "Not active" ;
VAL_ 1065 LCU_NMRing 1 "Active" 0 "Not active" ;
VAL_ 1065 LCU_NMAlive 1 "Active" 0 "Not active" ;
VAL_ 669 LCU_WelLightSt 15 "Reserved" 14 "Reserved" 13 "Reserved" 12 "Reserved" 11 "Reserved" 10 "Reserved" 9 "Reserved" 8 "Reserved" 7 "Reserved" 6 "Reserved" 5 "Reserved" 4 "Reserved" 3 "Reserved" 2 "Reserved" 1 "Enable" 0 "Disable" ;
VAL_ 669 LCU_FRDRLSt 3 "Reserved" 2 "Error" 1 "ON" 0 "OFF" ;
VAL_ 669 LCU_FRHighBeamSt 3 "Reserved" 2 "Error" 1 "ON" 0 "OFF" ;
VAL_ 672 LCU_ALSFaultSt 1 "Fault" 0 "Not Fault" ;
VAL_ 672 LCU_ADBEnable 1 "Enable" 0 "Disable" ;
VAL_ 672 LCU_ADBSt 7 "Reserved" 6 "Reserved" 5 "Reserved" 4 "Camera signal not valid" 3 "ADB failure" 2 "ADB active" 1 "ADB standby" 0 "ADB off" ;
VAL_ 672 LCU_FLDRLSt 3 "Reserved" 2 "Error" 1 "ON" 0 "OFF" ;
VAL_ 672 LCU_FLHighBeamSt 3 "Reserved" 2 "Error" 1 "ON" 0 "OFF" ;
VAL_ 1089 HUD_NMWakeupOrigin 255 "Reserved" 254 "Reserved" 253 "Reserved" 252 "Reserved" 251 "Reserved" 250 "Reserved" 249 "Reserved" 248 "Reserved" 247 "Reserved" 246 "Reserved" 245 "Reserved" 244 "Reserved" 243 "Reserved" 242 "Reserved" 241 "Reserved" 240 "Reserved" 239 "Reserved" 238 "Reserved" 237 "Reserved" 236 "Reserved" 235 "Reserved" 234 "Reserved" 233 "Reserved" 232 "Reserved" 231 "Reserved" 230 "Reserved" 229 "Reserved" 228 "Reserved" 227 "Reserved" 226 "Reserved" 225 "Reserved" 224 "Reserved" 223 "Reserved" 222 "Reserved" 221 "Reserved" 220 "Reserved" 219 "Reserved" 218 "Reserved" 217 "Reserved" 216 "Reserved" 215 "Reserved" 214 "Reserved" 213 "Reserved" 212 "Reserved" 211 "Reserved" 210 "Reserved" 209 "Reserved" 208 "Reserved" 207 "Reserved" 206 "Reserved" 205 "Reserved" 204 "Reserved" 203 "Reserved" 202 "Reserved" 201 "Reserved" 200 "Reserved" 199 "Reserved" 198 "Reserved" 197 "Reserved" 196 "Reserved" 195 "Reserved" 194 "Reserved" 193 "Reserved" 192 "Reserved" 191 "Reserved" 190 "Reserved" 189 "Reserved" 188 "Reserved" 187 "Reserved" 186 "Reserved" 185 "Reserved" 184 "Reserved" 183 "Reserved" 182 "Reserved" 181 "Reserved" 180 "Reserved" 179 "Reserved" 178 "Reserved" 177 "Reserved" 176 "Reserved" 175 "Reserved" 174 "Reserved" 173 "Reserved" 172 "Reserved" 171 "Reserved" 170 "Reserved" 169 "Reserved" 168 "Reserved" 167 "Reserved" 166 "Reserved" 165 "Reserved" 164 "Reserved" 163 "Reserved" 162 "Reserved" 161 "Reserved" 160 "Reserved" 159 "Reserved" 158 "Reserved" 157 "Reserved" 156 "Reserved" 155 "Reserved" 154 "Reserved" 153 "Reserved" 152 "Reserved" 151 "Reserved" 150 "Reserved" 149 "Reserved" 148 "Reserved" 147 "Reserved" 146 "Reserved" 145 "Reserved" 144 "Reserved" 143 "Reserved" 142 "Reserved" 141 "Reserved" 140 "Reserved" 139 "Reserved" 138 "Reserved" 137 "Reserved" 136 "Reserved" 135 "Reserved" 134 "Reserved" 133 "Reserved" 132 "Reserved" 131 "Reserved" 130 "Reserved" 129 "Reserved" 128 "Reserved" 127 "Reserved" 126 "Reserved" 125 "Reserved" 124 "Reserved" 123 "Reserved" 122 "Reserved" 121 "Reserved" 120 "Reserved" 119 "Reserved" 118 "Reserved" 117 "Reserved" 116 "Reserved" 115 "Reserved" 114 "Reserved" 113 "Reserved" 112 "Reserved" 111 "Reserved" 110 "Reserved" 109 "Reserved" 108 "Reserved" 107 "Reserved" 106 "Reserved" 105 "Reserved" 104 "Reserved" 103 "Reserved" 102 "Reserved" 101 "Reserved" 100 "Reserved" 99 "Reserved" 98 "Reserved" 97 "Reserved" 96 "Reserved" 95 "Reserved" 94 "Reserved" 93 "Reserved" 92 "Reserved" 91 "Reserved" 90 "Reserved" 89 "Reserved" 88 "Reserved" 87 "Reserved" 86 "Reserved" 85 "Reserved" 84 "Reserved" 83 "Reserved" 82 "Reserved" 81 "Reserved" 80 "Reserved" 79 "Reserved" 78 "Reserved" 77 "Reserved" 76 "Reserved" 75 "Reserved" 74 "Reserved" 73 "Reserved" 72 "Reserved" 71 "Reserved" 70 "Reserved" 69 "Reserved" 68 "Reserved" 67 "Reserved" 66 "Reserved" 65 "Reserved" 64 "Reserved" 63 "Reserved" 62 "Reserved" 61 "Reserved" 60 "Reserved" 59 "Reserved" 58 "Reserved" 57 "Reserved" 56 "Reserved" 55 "Reserved" 54 "Reserved" 53 "Reserved" 52 "Reserved" 51 "Reserved" 50 "Reserved" 49 "Reserved" 48 "Reserved" 47 "Reserved" 46 "Reserved" 45 "Reserved" 44 "Reserved" 43 "Reserved" 42 "Reserved" 41 "Reserved" 40 "Reserved" 39 "Reserved" 38 "Reserved" 37 "Reserved" 36 "Reserved" 35 "Reserved" 34 "Reserved" 33 "Reserved" 32 "Reserved" 31 "Reserved" 30 "Reserved" 29 "Reserved" 28 "Reserved" 27 "Reserved" 26 "Reserved" 25 "Reserved" 24 "Reserved" 23 "Reserved" 22 "Reserved" 21 "Reserved" 20 "Reserved" 19 "Reserved" 18 "IGN ON" 17 "Reserved" 16 "Reserved" 15 "Reserved" 14 "Reserved" 13 "Reserved" 12 "Reserved" 11 "Reserved" 10 "Reserved" 9 "Reserved" 8 "Reserved" 7 "Reserved" 6 "Reserved" 5 "Reserved" 4 "Reserved" 3 "Reserved" 2 "Reserved" 1 "Reserved" 0 "Reserved" ;
VAL_ 1089 HUD_NMSleepAck 1 "Active" 0 "Not active" ;
VAL_ 1089 HUD_NMSleepInd 1 "Active" 0 "Not active" ;
VAL_ 1089 HUD_NMLimpHome 1 "Active" 0 "Not active" ;
VAL_ 1089 HUD_NMRing 1 "Active" 0 "Not active" ;
VAL_ 1089 HUD_NMAlive 1 "Active" 0 "Not active" ;
VAL_ 996 HUD_ADASTSRDisEnable 1 "Enable" 0 "Disable" ;
VAL_ 996 HUD_NAV 1 "Enable" 0 "Disable" ;
VAL_ 996 HUD_ADASCruiseDisEnable 1 "Enable" 0 "Disable" ;
VAL_ 996 HUD_OffSt 3 "Reserved" 2 "Active" 1 "Not active" 0 "no command" ;
VAL_ 1056 BCM_NMSleepAck 1 "Active" 0 "Not active" ;
VAL_ 1056 BCM_NMSleepInd 1 "Active" 0 "Not active" ;
VAL_ 1056 BCM_NMLimpHome 1 "Active" 0 "Not active" ;
VAL_ 1056 BCM_NMRing 1 "Active" 0 "Not active" ;
VAL_ 1056 BCM_NMAlive 1 "Active" 0 "Not active" ;
VAL_ 1002 PEPS_NFC_ID 15 "Reserved" 14 "Reserved" 13 "Reserved" 12 "Reserved" 11 "Reserved" 10 "Reserved" 9 "Reserved" 8 "Reserved" 7 "Reserved" 6 "Reserved" 5 "Reserved" 4 "Reserved" 3 "Key3 index" 2 "Key2 index" 1 "Key1 index" 0 "Not used" ;
VAL_ 799 PEPS_IdInVeWarningCfgSt 1 "Active" 0 "Not active" ;
VAL_ 799 PEPS_ESCLCfgSt 1 "ESCL configured" 0 "ESCL not configured" ;
VAL_ 799 PEPS_APUCfgSt 1 "Active" 0 "Not active" ;
VAL_ 799 PEPS_SATOCfgSt 3 "Not used" 2 "SATO function and sound reminder active" 1 "SATO function Active" 0 "Not active" ;
VAL_ 799 PEPS_KickSnsCfgSt 1 "Active" 0 "Not active" ;
VAL_ 799 PEPS_WALCfgSt 1 "Active" 0 "Not active" ;
VAL_ 799 PEPS_WELCfgSt 1 "Active" 0 "Not active" ;
VAL_ 629 PEPS_IG1FailWarn 1 "Warning  " 0 "Not warning" ;
VAL_ 629 PEPS_IdInVehicleWarning 1 "Warning  " 0 "Not warning" ;
VAL_ 629 PEPS_EngForbidWarn 1 "Warning" 0 "Not warning" ;
VAL_ 629 PEPS_Crankallow 1 "Allowed" 0 "Not allowed" ;
VAL_ 629 PEPS_ETWS_St 1 "Warning" 0 "Not warning" ;
VAL_ 629 PEPS_KeyOutWarning 3 "Reserved" 2 "Key out cyclic warning" 1 "Reserved" 0 "No warning" ;
VAL_ 629 PEPS_KeyReminderWarning 3 "Reserved" 2 "Key reminder warning2" 1 "Reserved" 0 "No warning" ;
VAL_ 629 PEPS_DoorLockWarning 3 "Door lock warning3" 2 "Door lock warning2" 1 "Door lock warning1" 0 "No warning" ;
VAL_ 629 PEPS_FobBattLowWarning 1 "Warning" 0 "No warning " ;
VAL_ 629 PEPS_ESCLWarning 7 "Reserved" 6 "Reserved" 5 "Reserved" 4 "Reserved" 3 "ESCL authentication failure warning" 2 "ESCL lock failure warning" 1 "ESCL unlock failure warning" 0 "No warning" ;
VAL_ 629 PEPS_SSBWarning 3 "Reserved" 2 "Reserved" 1 "SSB Stuck warning" 0 "None" ;
VAL_ 629 PEPS_DeactivationWarning 1 "ID deactivation warning" 0 "No warning" ;
VAL_ 629 PEPS_OpIndicationWarning 7 "Reserved" 6 "Reserved" 5 "Reserved" 4 "Engine start operation indicator" 3 "Reserved" 2 "Vehicle Not P warning" 1 "vehicle Not P（Door opened）" 0 "No warning" ;
VAL_ 629 PEPS_AuthFailWarning 3 "Reserved" 2 "Reserved" 1 "Authentication failure warning1" 0 "No warning" ;
VAL_ 826 TPMS_RRTyreTemp 255 "Waiting( Vehicle speed not enough and not valid signal received previous)" ;
VAL_ 826 TPMS_RLTyreTemp 255 "Waiting( Vehicle speed not enough and not valid signal received previous)" ;
VAL_ 826 TPMS_FRTyreTemp 255 "Waiting( Vehicle speed not enough and not valid signal received previous)" ;
VAL_ 826 TPMS_FLTyreTemp 255 "Waiting( Vehicle speed not enough and not valid signal received previous)" ;
VAL_ 805 TPMS_TyreSt 1 "Tyre not OK" 0 "Tyre OK" ;
VAL_ 805 TPMS_SystemSt 1 "System not OK" 0 "System OK" ;
VAL_ 974 BCM_TCH_CupholdHeatCoolAutoMdSt 3 "NTC Abnormal working" 2 "TEC Abnormal working" 1 "Vent Abnormal working" 0 " Regular working" ;
VAL_ 974 BCM_TCH_CupholderHeatCoolModeSt 3 "Not used" 2 "Cooling" 1 "Heating" 0 "OFF" ;
VAL_ 149 BCM_PCS_ButtonPress 1 "Press" 0 " Not Press" ;
VAL_ 1556 MCMRR_MasMode 7 "Not used" 6 "Mode6" 5 "Mode5" 4 "Mode4" 3 "Mode3" 2 "Mode2" 1 "Mode1" 0 "Off" ;
VAL_ 1556 MCMRR_MasSt 1 "On" 0 "Off" ;
VAL_ 1556 MCMRR_MasIntensity 3 "Mode 3" 2 "Mode 2" 1 "Mode 1" 0 "Off" ;
VAL_ 1556 MCMRL_MasIntensity 3 "Mode 3" 2 "Mode 2" 1 "Mode 1" 0 "Off" ;
VAL_ 1556 MCMRL_MasMode 7 "Not used" 6 "Mode6" 5 "Mode5" 4 "Mode4" 3 "Mode3" 2 "Mode2" 1 "Mode1" 0 "Off" ;
VAL_ 1556 MCMRL_MasSt 1 "On" 0 "Off" ;
VAL_ 960 BCM_RainstormModeReq 3 "Not used" 2 "AutoQuit" 1 "EnterRemind" 0 "No  command" ;
VAL_ 960 BCM_SunshadePstSt 15 "Not used" 14 "Not used" 13 "Not used" 12 "Not used" 11 "Not used" 10 "Not used" 9 "Not used" 8 "Not used" 7 "Fully open" 6 "Position not trusted" 5 "Reversing" 4 "Closing" 3 "Opening" 2 "Not used" 1 "Slide open" 0 "Fully close" ;
VAL_ 960 BCM_VCU_UnlockACChgPortReqP 1 "Request" 0 "No Request" ;
VAL_ 960 BCM_AmbientLightSt 1 "Active" 0 "Not active" ;
VAL_ 960 BCM_FrontWiperSwitchSt 3 "Continuous fast" 2 "Continuous slow" 1 " Auto or INT" 0 "OFF" ;
VAL_ 960 BCM_LampOnWarningReq 1 "Active" 0 "Not active" ;
VAL_ 960 BCM_SunRoofOpenWarning 1 "Warning" 0 "Not warning" ;
VAL_ 960 BCM_RearWiperSwitchSt 1 "ON" 0 "OFF" ;
VAL_ 960 BCM_BrakeLightFaultSt 1 "Fault" 0 "Not fault" ;
VAL_ 960 BCM_BrakeLightSt 1 "Active" 0 "Not active" ;
VAL_ 960 BCM_ReverseLightFaultSt 1 "Fault" 0 "Not fault" ;
VAL_ 960 BCM_ReverseLightSt 1 "Active" 0 "Not active" ;
VAL_ 960 BCM_RLSWarningLight 1 "Warning" 0 "Not warning" ;
VAL_ 960 BCM_RLSWarningRain 1 "Warning" 0 "Not warning" ;
VAL_ 960 BCM_HazardLampSt 1 "Active" 0 "Not active" ;
